VERSION ""

NS_ :

BS_:

BU_: CLOCK HUD H_U DATC CCP KMA_TMU CUBIS TMU IPM RSE_R RRC CGW RSE_L AMP EDT SWRC IBOX CLU FHCU ASD MON AVM KBD

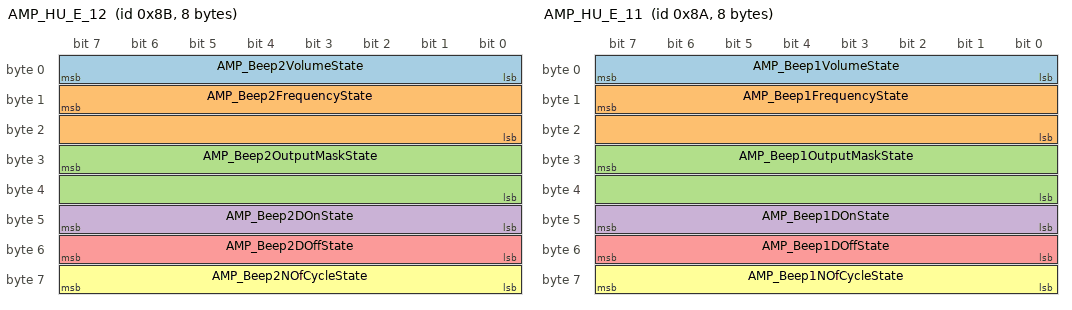
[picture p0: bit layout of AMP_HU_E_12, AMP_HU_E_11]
BO_ 139 AMP_HU_E_12: 8 AMP
 SG_ AMP_Beep2VolumeState : 7|8@0+ (1,0) [0|0] ""  H_U
 SG_ AMP_Beep2FrequencyState : 15|16@0+ (1,0) [0|0] ""  H_U
 SG_ AMP_Beep2OutputMaskState : 31|16@0+ (1,0) [0|0] ""  H_U
 SG_ AMP_Beep2DOnState : 47|8@0+ (1,0) [0|0] ""  H_U
 SG_ AMP_Beep2DOffState : 55|8@0+ (1,0) [0|0] ""  H_U
 SG_ AMP_Beep2NOfCycleState : 63|8@0+ (1,0) [0|0] ""  H_U

BO_ 138 AMP_HU_E_11: 8 AMP
 SG_ AMP_Beep1VolumeState : 7|8@0+ (1,0) [0|0] ""  H_U
 SG_ AMP_Beep1FrequencyState : 15|16@0+ (1,0) [0|0] ""  H_U
 SG_ AMP_Beep1OutputMaskState : 31|16@0+ (1,0) [0|0] ""  H_U
 SG_ AMP_Beep1DOnState : 47|8@0+ (1,0) [0|0] ""  H_U
 SG_ AMP_Beep1DOffState : 55|8@0+ (1,0) [0|0] ""  H_U
 SG_ AMP_Beep1NOfCycleState : 63|8@0+ (1,0) [0|0] ""  H_U

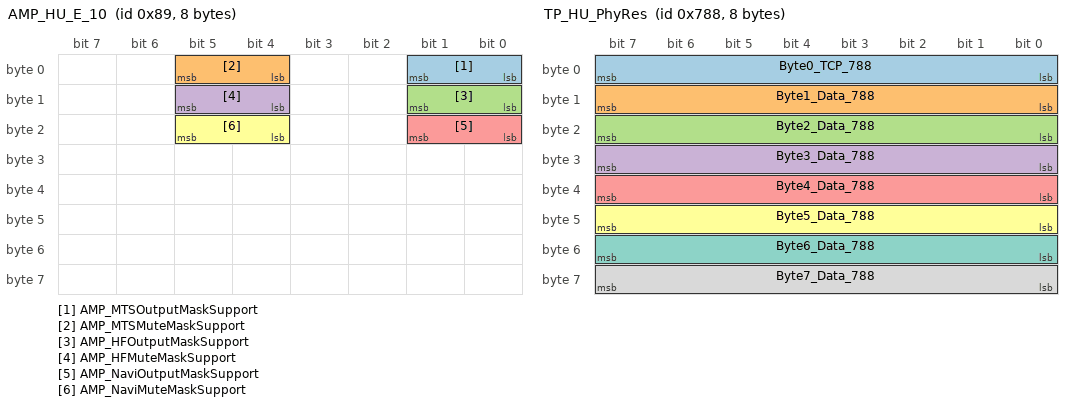
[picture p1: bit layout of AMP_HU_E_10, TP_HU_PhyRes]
BO_ 137 AMP_HU_E_10: 8 AMP
 SG_ AMP_MTSOutputMaskSupport : 1|2@0+ (1,0) [0|0] ""  H_U
 SG_ AMP_MTSMuteMaskSupport : 5|2@0+ (1,0) [0|0] ""  H_U
 SG_ AMP_HFOutputMaskSupport : 9|2@0+ (1,0) [0|0] ""  H_U
 SG_ AMP_HFMuteMaskSupport : 13|2@0+ (1,0) [0|0] ""  H_U
 SG_ AMP_NaviOutputMaskSupport : 17|2@0+ (1,0) [0|0] ""  H_U
 SG_ AMP_NaviMuteMaskSupport : 21|2@0+ (1,0) [0|0] ""  H_U

BO_ 1928 TP_HU_PhyRes: 8 H_U
 SG_ Byte0_TCP_788 : 7|8@0+ (1,0) [0|0] ""  EDT
 SG_ Byte1_Data_788 : 15|8@0+ (1,0) [0|0] ""  EDT
 SG_ Byte2_Data_788 : 23|8@0+ (1,0) [0|0] ""  EDT
 SG_ Byte3_Data_788 : 31|8@0+ (1,0) [0|0] ""  EDT
 SG_ Byte4_Data_788 : 39|8@0+ (1,0) [0|0] ""  EDT
 SG_ Byte5_Data_788 : 47|8@0+ (1,0) [0|0] ""  EDT
 SG_ Byte6_Data_788 : 55|8@0+ (1,0) [0|0] ""  EDT
 SG_ Byte7_Data_788 : 63|8@0+ (1,0) [0|0] ""  EDT

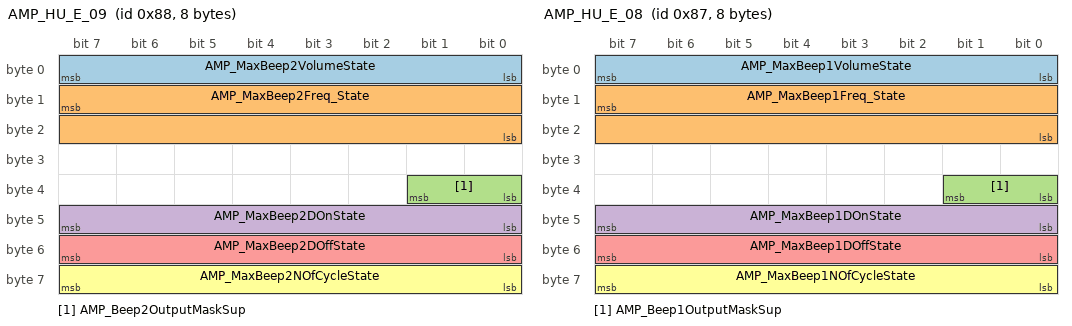
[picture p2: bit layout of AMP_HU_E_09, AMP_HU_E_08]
BO_ 136 AMP_HU_E_09: 8 AMP
 SG_ AMP_MaxBeep2VolumeState : 7|8@0+ (1,0) [0|0] ""  H_U
 SG_ AMP_MaxBeep2Freq_State : 15|16@0+ (1,0) [0|0] ""  H_U
 SG_ AMP_Beep2OutputMaskSup : 33|2@0+ (1,0) [0|0] ""  H_U
 SG_ AMP_MaxBeep2DOnState : 47|8@0+ (1,0) [0|0] ""  H_U
 SG_ AMP_MaxBeep2DOffState : 55|8@0+ (1,0) [0|0] ""  H_U
 SG_ AMP_MaxBeep2NOfCycleState : 63|8@0+ (1,0) [0|0] ""  H_U

BO_ 135 AMP_HU_E_08: 8 AMP
 SG_ AMP_MaxBeep1VolumeState : 7|8@0+ (1,0) [0|0] ""  H_U
 SG_ AMP_MaxBeep1Freq_State : 15|16@0+ (1,0) [0|0] ""  H_U
 SG_ AMP_Beep1OutputMaskSup : 33|2@0+ (1,0) [0|0] ""  H_U
 SG_ AMP_MaxBeep1DOnState : 47|8@0+ (1,0) [0|0] ""  H_U
 SG_ AMP_MaxBeep1DOffState : 55|8@0+ (1,0) [0|0] ""  H_U
 SG_ AMP_MaxBeep1NOfCycleState : 63|8@0+ (1,0) [0|0] ""  H_U

BO_ 134 AMP_HU_E_07: 8 AMP
 SG_ ASD_SetValue : 2|3@0+ (1,0) [0|0] ""  H_U,IBOX
 SG_ ASD_Version : 15|8@0+ (1,0) [0|0] ""  H_U,IBOX

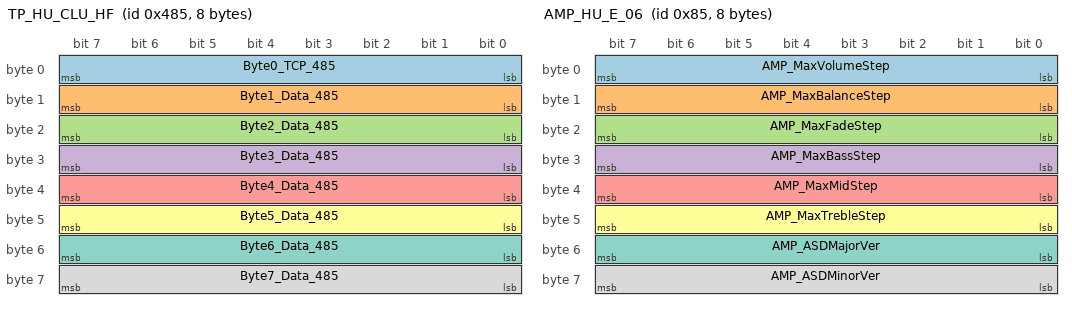
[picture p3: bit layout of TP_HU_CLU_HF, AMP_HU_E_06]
BO_ 1157 TP_HU_CLU_HF: 8 H_U
 SG_ Byte0_TCP_485 : 7|8@0+ (1,0) [0|0] ""  CLU
 SG_ Byte1_Data_485 : 15|8@0+ (1,0) [0|0] ""  CLU
 SG_ Byte2_Data_485 : 23|8@0+ (1,0) [0|0] ""  CLU
 SG_ Byte3_Data_485 : 31|8@0+ (1,0) [0|0] ""  CLU
 SG_ Byte4_Data_485 : 39|8@0+ (1,0) [0|0] ""  CLU
 SG_ Byte5_Data_485 : 47|8@0+ (1,0) [0|0] ""  CLU
 SG_ Byte6_Data_485 : 55|8@0+ (1,0) [0|0] ""  CLU
 SG_ Byte7_Data_485 : 63|8@0+ (1,0) [0|0] ""  CLU

BO_ 133 AMP_HU_E_06: 8 AMP
 SG_ AMP_MaxVolumeStep : 7|8@0+ (1,0) [0|0] ""  H_U
 SG_ AMP_MaxBalanceStep : 15|8@0+ (1,0) [0|0] ""  H_U
 SG_ AMP_MaxFadeStep : 23|8@0+ (1,0) [0|0] ""  H_U
 SG_ AMP_MaxBassStep : 31|8@0+ (1,0) [0|0] ""  H_U
 SG_ AMP_MaxMidStep : 39|8@0+ (1,0) [0|0] ""  H_U
 SG_ AMP_MaxTrebleStep : 47|8@0+ (1,0) [0|0] ""  H_U
 SG_ AMP_ASDMajorVer : 55|8@0+ (1,0) [0|0] ""  H_U
 SG_ AMP_ASDMinorVer : 63|8@0+ (1,0) [0|0] ""  H_U

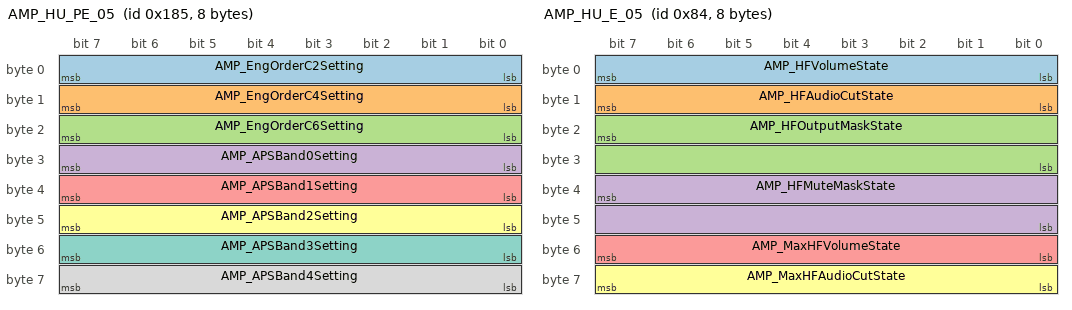
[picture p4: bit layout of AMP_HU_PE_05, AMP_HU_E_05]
BO_ 389 AMP_HU_PE_05: 8 AMP
 SG_ AMP_EngOrderC2Setting : 7|8@0+ (1,0) [0|0] ""  H_U
 SG_ AMP_EngOrderC4Setting : 15|8@0+ (1,0) [0|0] ""  H_U
 SG_ AMP_EngOrderC6Setting : 23|8@0+ (1,0) [0|0] ""  H_U
 SG_ AMP_APSBand0Setting : 31|8@0+ (1,0) [0|0] ""  H_U
 SG_ AMP_APSBand1Setting : 39|8@0+ (1,0) [0|0] ""  H_U
 SG_ AMP_APSBand2Setting : 47|8@0+ (1,0) [0|0] ""  H_U
 SG_ AMP_APSBand3Setting : 55|8@0+ (1,0) [0|0] ""  H_U
 SG_ AMP_APSBand4Setting : 63|8@0+ (1,0) [0|0] ""  H_U

BO_ 132 AMP_HU_E_05: 8 AMP
 SG_ AMP_HFVolumeState : 7|8@0+ (1,0) [0|0] ""  H_U
 SG_ AMP_HFAudioCutState : 15|8@0+ (1,0) [0|0] ""  H_U
 SG_ AMP_HFOutputMaskState : 23|16@0+ (1,0) [0|0] ""  H_U
 SG_ AMP_HFMuteMaskState : 39|16@0+ (1,0) [0|0] ""  H_U
 SG_ AMP_MaxHFVolumeState : 55|8@0+ (1,0) [0|0] ""  H_U
 SG_ AMP_MaxHFAudioCutState : 63|8@0+ (1,0) [0|0] ""  H_U

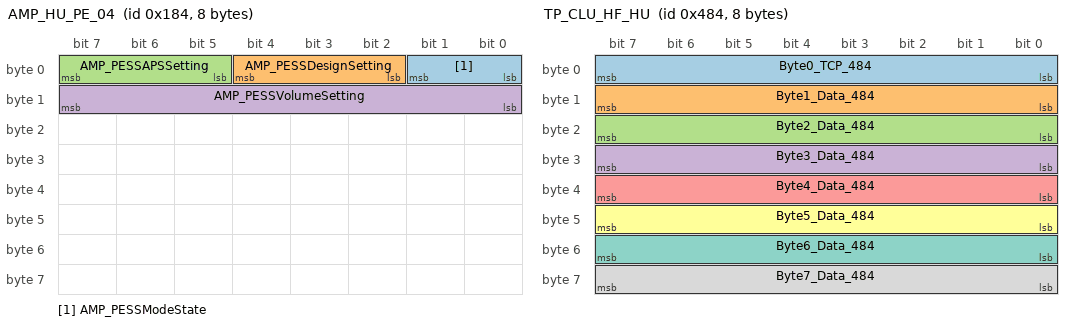
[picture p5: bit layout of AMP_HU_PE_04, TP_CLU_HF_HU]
BO_ 388 AMP_HU_PE_04: 8 AMP
 SG_ AMP_PESSModeState : 1|2@0+ (1,0) [0|0] ""  H_U
 SG_ AMP_PESSDesignSetting : 4|3@0+ (1,0) [0|0] ""  H_U
 SG_ AMP_PESSAPSSetting : 7|3@0+ (1,0) [0|0] ""  H_U
 SG_ AMP_PESSVolumeSetting : 15|8@0+ (1,0) [0|0] ""  H_U

BO_ 1156 TP_CLU_HF_HU: 8 CLU
 SG_ Byte0_TCP_484 : 7|8@0+ (1,0) [0|0] ""  H_U
 SG_ Byte1_Data_484 : 15|8@0+ (1,0) [0|0] ""  H_U
 SG_ Byte2_Data_484 : 23|8@0+ (1,0) [0|0] ""  H_U
 SG_ Byte3_Data_484 : 31|8@0+ (1,0) [0|0] ""  H_U
 SG_ Byte4_Data_484 : 39|8@0+ (1,0) [0|0] ""  H_U
 SG_ Byte5_Data_484 : 47|8@0+ (1,0) [0|0] ""  H_U
 SG_ Byte6_Data_484 : 55|8@0+ (1,0) [0|0] ""  H_U
 SG_ Byte7_Data_484 : 63|8@0+ (1,0) [0|0] ""  H_U

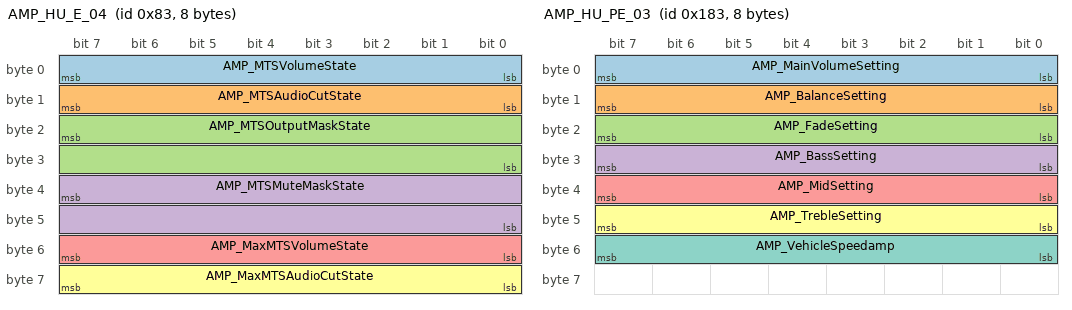
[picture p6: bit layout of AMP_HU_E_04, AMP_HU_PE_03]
BO_ 131 AMP_HU_E_04: 8 AMP
 SG_ AMP_MTSVolumeState : 7|8@0+ (1,0) [0|0] ""  H_U
 SG_ AMP_MTSAudioCutState : 15|8@0+ (1,0) [0|0] ""  H_U
 SG_ AMP_MTSOutputMaskState : 23|16@0+ (1,0) [0|0] ""  H_U
 SG_ AMP_MTSMuteMaskState : 39|16@0+ (1,0) [0|0] ""  H_U
 SG_ AMP_MaxMTSVolumeState : 55|8@0+ (1,0) [0|0] ""  H_U
 SG_ AMP_MaxMTSAudioCutState : 63|8@0+ (1,0) [0|0] ""  H_U

BO_ 387 AMP_HU_PE_03: 8 AMP
 SG_ AMP_MainVolumeSetting : 7|8@0+ (1,0) [0|0] ""  H_U
 SG_ AMP_BalanceSetting : 15|8@0+ (1,0) [0|0] ""  H_U
 SG_ AMP_FadeSetting : 23|8@0+ (1,0) [0|0] ""  H_U
 SG_ AMP_BassSetting : 31|8@0+ (1,0) [0|0] ""  H_U
 SG_ AMP_MidSetting : 39|8@0+ (1,0) [0|0] ""  H_U
 SG_ AMP_TrebleSetting : 47|8@0+ (1,0) [0|0] ""  H_U
 SG_ AMP_VehicleSpeedamp : 55|8@0+ (1,0) [0|0] ""  H_U

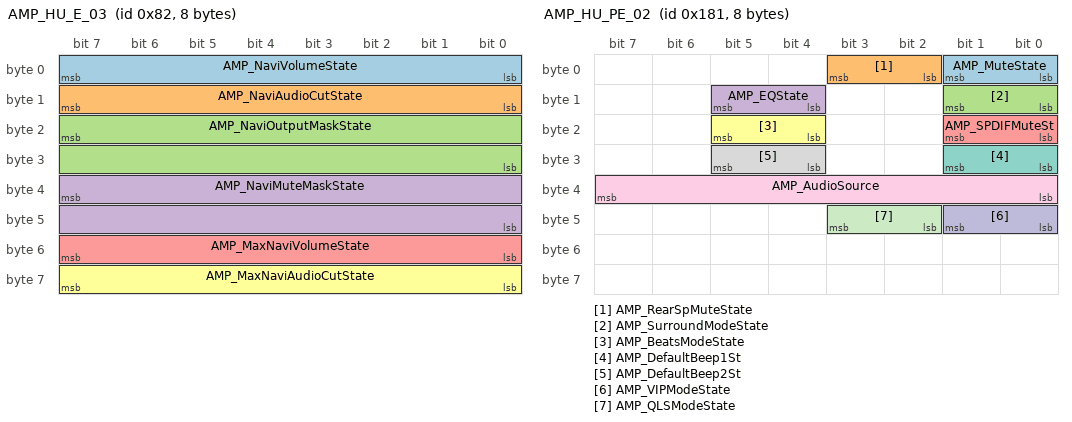
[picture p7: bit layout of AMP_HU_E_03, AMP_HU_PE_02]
BO_ 130 AMP_HU_E_03: 8 AMP
 SG_ AMP_NaviVolumeState : 7|8@0+ (1,0) [0|0] ""  H_U
 SG_ AMP_NaviAudioCutState : 15|8@0+ (1,0) [0|0] ""  H_U
 SG_ AMP_NaviOutputMaskState : 23|16@0+ (1,0) [0|0] ""  H_U
 SG_ AMP_NaviMuteMaskState : 39|16@0+ (1,0) [0|0] ""  H_U
 SG_ AMP_MaxNaviVolumeState : 55|8@0+ (1,0) [0|0] ""  H_U
 SG_ AMP_MaxNaviAudioCutState : 63|8@0+ (1,0) [0|0] ""  H_U

BO_ 129 AMP_HU_E_02: 8 AMP
 SG_ AMP_DriveState : 1|2@0+ (1,0) [0|0] ""  H_U
 SG_ AMP_ConvertibleTopState : 5|2@0+ (1,0) [0|0] ""  H_U

BO_ 385 AMP_HU_PE_02: 8 AMP
 SG_ AMP_MuteState : 1|2@0+ (1,0) [0|0] ""  H_U
 SG_ AMP_RearSpMuteState : 3|2@0+ (1,0) [0|0] ""  H_U
 SG_ AMP_SurroundModeState : 9|2@0+ (1,0) [0|0] ""  H_U
 SG_ AMP_EQState : 13|2@0+ (1,0) [0|0] ""  H_U
 SG_ AMP_SPDIFMuteSt : 17|2@0+ (1,0) [0|0] ""  H_U
 SG_ AMP_BeatsModeState : 21|2@0+ (1,0) [0|0] ""  H_U
 SG_ AMP_DefaultBeep1St : 25|2@0+ (1,0) [0|0] ""  H_U
 SG_ AMP_DefaultBeep2St : 29|2@0+ (1,0) [0|0] ""  H_U
 SG_ AMP_AudioSource : 39|8@0+ (1,0) [0|0] ""  H_U
 SG_ AMP_VIPModeState : 41|2@0+ (1,0) [0|0] ""  H_U
 SG_ AMP_QLSModeState : 43|2@0+ (1,0) [0|0] ""  H_U

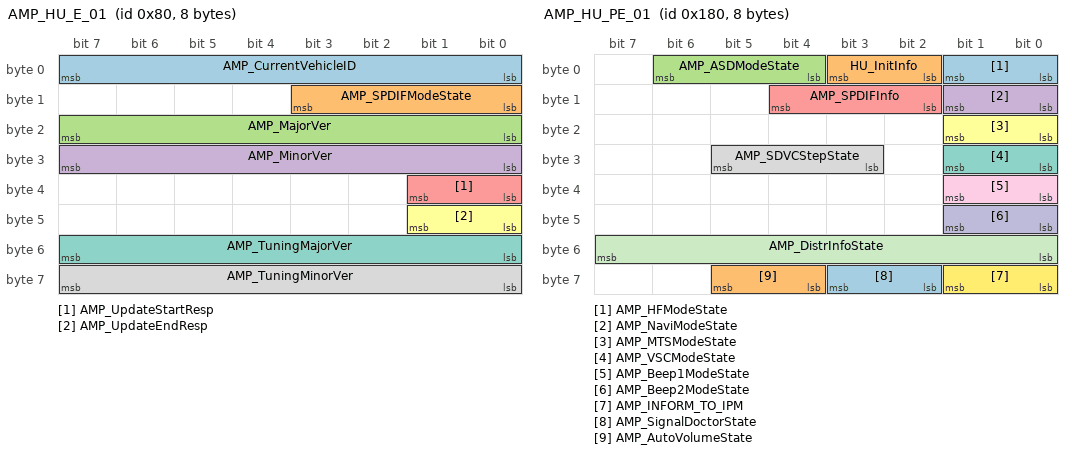
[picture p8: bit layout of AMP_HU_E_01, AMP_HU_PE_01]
BO_ 128 AMP_HU_E_01: 8 AMP
 SG_ AMP_CurrentVehicleID : 7|8@0+ (1,0) [0|0] ""  H_U
 SG_ AMP_SPDIFModeState : 11|4@0+ (1,0) [0|0] ""  H_U
 SG_ AMP_MajorVer : 23|8@0+ (1,0) [0|0] ""  H_U,MON
 SG_ AMP_MinorVer : 31|8@0+ (1,0) [0|0] ""  H_U,MON
 SG_ AMP_UpdateStartResp : 33|2@0+ (1,0) [0|0] ""  H_U
 SG_ AMP_UpdateEndResp : 41|2@0+ (1,0) [0|0] ""  H_U
 SG_ AMP_TuningMajorVer : 55|8@0+ (1,0) [0|0] ""  H_U
 SG_ AMP_TuningMinorVer : 63|8@0+ (1,0) [0|0] ""  H_U

BO_ 384 AMP_HU_PE_01: 8 AMP
 SG_ AMP_HFModeState : 1|2@0+ (1,0) [0|0] ""  CLU,H_U
 SG_ HU_InitInfo : 3|2@0+ (1,0) [0|0] ""  CLU,H_U
 SG_ AMP_ASDModeState : 6|3@0+ (1,0) [0|0] ""  CLU,H_U
 SG_ AMP_NaviModeState : 9|2@0+ (1,0) [0|0] ""  CLU,H_U
 SG_ AMP_SPDIFInfo : 12|3@0+ (1,0) [0|0] ""  CLU,H_U
 SG_ AMP_MTSModeState : 17|2@0+ (1,0) [0|0] ""  CLU,H_U
 SG_ AMP_VSCModeState : 25|2@0+ (1,0) [0|0] ""  CLU,H_U
 SG_ AMP_SDVCStepState : 29|3@0+ (1,0) [0|0] ""  CLU,H_U
 SG_ AMP_Beep1ModeState : 33|2@0+ (1,0) [0|0] ""  CLU,H_U
 SG_ AMP_Beep2ModeState : 41|2@0+ (1,0) [0|0] ""  CLU,H_U
 SG_ AMP_DistrInfoState : 55|8@0+ (1,0) [0|0] ""  CLU,H_U
 SG_ AMP_INFORM_TO_IPM : 57|2@0+ (1,0) [0|0] ""  CGW,CLU,DATC,H_U,IPM
 SG_ AMP_SignalDoctorState : 59|2@0+ (1,0) [0|0] ""  H_U
 SG_ AMP_AutoVolumeState : 61|2@0+ (1,0) [0|0] ""  H_U

BO_ 1408 AMP_HU_P_01: 8 AMP
 SG_ AMP_SupportMute : 1|2@0+ (1,0) [0|0] ""  H_U
 SG_ AMP_SupportHFMode : 3|2@0+ (1,0) [0|0] ""  H_U
 SG_ AMP_SupportCfgBeep1 : 5|2@0+ (1,0) [0|0] ""  H_U
 SG_ AMP_SupportCfgBeep2 : 7|2@0+ (1,0) [0|0] ""  H_U
 SG_ AMP_SupportSpeedAdjust : 9|2@0+ (1,0) [0|0] ""  H_U
 SG_ AMP_SupportSurroundMode : 11|2@0+ (1,0) [0|0] ""  H_U
 SG_ AMP_SupportNaviMode : 13|2@0+ (1,0) [0|0] ""  H_U
 SG_ AMP_SupportMTSMode : 15|2@0+ (1,0) [0|0] ""  H_U
 SG_ AMP_SupportTopState : 17|2@0+ (1,0) [0|0] ""  H_U
 SG_ AMP_SupportBothLHDandRHD : 19|2@0+ (1,0) [0|0] ""  H_U
 SG_ AMP_SupportEQState : 21|2@0+ (1,0) [0|0] ""  H_U
 SG_ AMP_SupportVehicleID : 23|2@0+ (1,0) [0|0] ""  H_U
 SG_ AMP_SupportAudioSource : 25|2@0+ (1,0) [0|0] ""  H_U
 SG_ AMP_SupportSPDIFModeState : 27|2@0+ (1,0) [0|0] ""  H_U
 SG_ AMP_SupportRearSpMute : 29|2@0+ (1,0) [0|0] ""  H_U
 SG_ AMP_SupportVEQMode : 31|2@0+ (1,0) [0|0] ""  H_U
 SG_ AMP_MakerID : 39|8@0+ (1,0) [0|0] ""  H_U
 SG_ AMP_SupportASDMode : 41|2@0+ (1,0) [0|0] ""  H_U
 SG_ AMP_SupportBeatsMode : 43|2@0+ (1,0) [0|0] ""  H_U
 SG_ AMP_SupportVIPMode : 45|2@0+ (1,0) [0|0] ""  H_U
 SG_ AMP_SupportQLS : 47|2@0+ (1,0) [0|0] ""  H_U
 SG_ AMP_SupportSignalDoctor : 49|2@0+ (1,0) [0|0] ""  H_U
 SG_ AMP_SupportAutoVolume : 51|2@0+ (1,0) [0|0] ""  H_U
 SG_ AMP_SupportPESSMode : 53|2@0+ (1,0) [0|0] ""  H_U

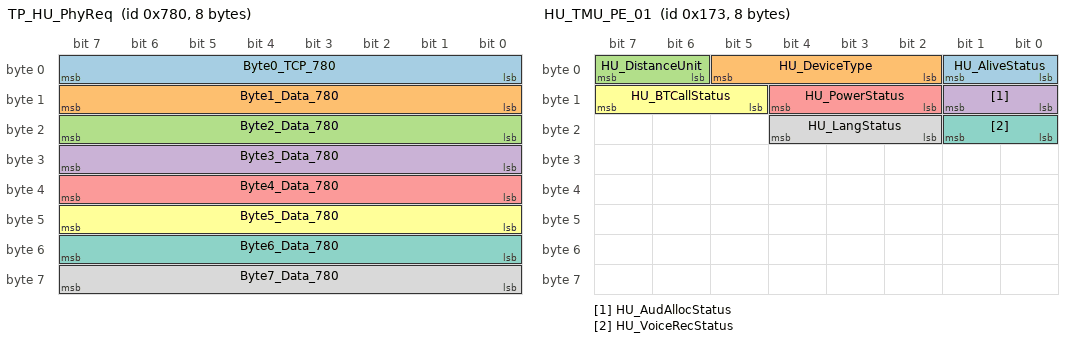
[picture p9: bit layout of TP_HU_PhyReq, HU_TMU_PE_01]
BO_ 1920 TP_HU_PhyReq: 8 EDT
 SG_ Byte0_TCP_780 : 7|8@0+ (1,0) [0|0] ""  H_U
 SG_ Byte1_Data_780 : 15|8@0+ (1,0) [0|0] ""  H_U
 SG_ Byte2_Data_780 : 23|8@0+ (1,0) [0|0] ""  H_U
 SG_ Byte3_Data_780 : 31|8@0+ (1,0) [0|0] ""  H_U
 SG_ Byte4_Data_780 : 39|8@0+ (1,0) [0|0] ""  H_U
 SG_ Byte5_Data_780 : 47|8@0+ (1,0) [0|0] ""  H_U
 SG_ Byte6_Data_780 : 55|8@0+ (1,0) [0|0] ""  H_U
 SG_ Byte7_Data_780 : 63|8@0+ (1,0) [0|0] ""  H_U

BO_ 371 HU_TMU_PE_01: 8 H_U
 SG_ HU_AliveStatus : 1|2@0+ (1,0) [0|0] ""  CLU,CGW,TMU
 SG_ HU_DeviceType : 5|4@0+ (1,0) [0|0] ""  TMU
 SG_ HU_DistanceUnit : 7|2@0+ (1,0) [0|0] ""  TMU
 SG_ HU_AudAllocStatus : 9|2@0+ (1,0) [0|0] ""  TMU
 SG_ HU_PowerStatus : 12|3@0+ (1,0) [0|0] ""  TMU
 SG_ HU_BTCallStatus : 15|3@0+ (1,0) [0|0] ""  TMU
 SG_ HU_VoiceRecStatus : 17|2@0+ (1,0) [0|0] ""  TMU
 SG_ HU_LangStatus : 20|3@0+ (1,0) [0|0] ""  TMU

BO_ 369 HU_Car_PE_01: 8 H_U
 SG_ HU_VehiclePwr : 3|4@0+ (1,0) [0|0] ""  AMP,ASD,AVM,CCP,CLOCK,CLU,CUBIS,DATC,FHCU,IPM,KBD,KMA_TMU,MON,RRC,RSE_L,RSE_R,TMU

BO_ 1392 HU_TMU_P_01: 8 H_U
 SG_ HU_GPS_Signal : 7|64@0+ (1,0) [0|0] ""  TMU

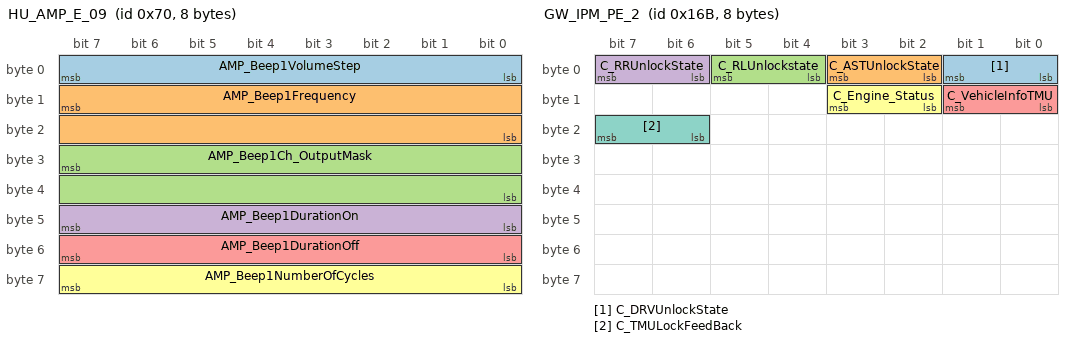
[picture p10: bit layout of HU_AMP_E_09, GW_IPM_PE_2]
BO_ 112 HU_AMP_E_09: 8 H_U
 SG_ AMP_Beep1VolumeStep : 7|8@0+ (1,0) [0|0] ""  AMP
 SG_ AMP_Beep1Frequency : 15|16@0+ (1,0) [0|0] ""  AMP
 SG_ AMP_Beep1Ch_OutputMask : 31|16@0+ (1,0) [0|0] ""  AMP
 SG_ AMP_Beep1DurationOn : 47|8@0+ (1,0) [0|0] ""  AMP
 SG_ AMP_Beep1DurationOff : 55|8@0+ (1,0) [0|0] ""  AMP
 SG_ AMP_Beep1NumberOfCycles : 63|8@0+ (1,0) [0|0] ""  AMP

BO_ 1390 GW_CLU_P: 8 CLU
 SG_ C_VehicleSpeed : 7|8@0+ (1,0) [0|254] ""  H_U,IBOX
 SG_ C_Odometer : 15|24@0+ (1,0) [0|999999] ""  H_U,IBOX

BO_ 363 GW_IPM_PE_2: 8 CLU
 SG_ C_DRVUnlockState : 1|2@0+ (1,0) [0|0] ""  CUBIS,TMU
 SG_ C_ASTUnlockState : 3|2@0+ (1,0) [0|0] ""  CUBIS,TMU
 SG_ C_RLUnlockstate : 5|2@0+ (1,0) [0|0] ""  CUBIS,TMU
 SG_ C_RRUnlockState : 7|2@0+ (1,0) [0|0] ""  CUBIS,TMU
 SG_ C_VehicleInfoTMU : 9|2@0+ (1,0) [0|0] ""  CUBIS,TMU
 SG_ C_Engine_Status : 11|2@0+ (1,0) [0|0] ""  CUBIS,TMU
 SG_ C_TMULockFeedBack : 23|2@0+ (1,0) [0|0] ""  CUBIS,TMU

BO_ 362 GW_IPM_PE_1: 8 CLU
 SG_ C_AV_Tail : 1|2@0+ (1,0) [0|0] ""  AMP,CCP,CLOCK,CLU,HUD,H_U,IBOX,RRC,RSE_L
 SG_ C_ParkingBrakeSW : 3|2@0+ (1,0) [0|0] ""  H_U
 SG_ C_RKECMD : 7|4@0+ (1,0) [0|0] ""  H_U
 SG_ C_BAState : 9|2@0+ (1,0) [0|0] ""  H_U,IBOX
 SG_ C_IGNSW : 14|3@0+ (1,0) [0|0] ""  AMP,AVM,CUBIS,EDT,H_U,MON,RRC,SWRC
 SG_ C_CountryCfg : 18|3@0+ (1,0) [0|0] ""  AVM,H_U
 SG_ C_AltL : 25|2@0+ (1,0) [0|0] ""  H_U
 SG_ C_TailLampActivity : 27|2@0+ (1,0) [0|0] ""  AMP,CCP,CLOCK,HUD,H_U,IBOX,RRC,RSE_L,SWRC
 SG_ RearSW_RSELockOnOff : 29|2@0+ (1,0) [0|0] ""  H_U,IBOX
 SG_ C_TMULockFeedBack : 31|2@0+ (1,0) [0|0] ""  CUBIS,TMU
 SG_ C_SMKTeleCrankingState : 33|2@0+ (1,0) [0|0] ""  H_U,IBOX
 SG_ C_SMKTeleCrankingFailRes : 35|2@0+ (1,0) [0|0] ""  H_U,IBOX
 SG_ C_RKECMD_GEN2 : 39|3@0+ (1,0) [0|0] ""  H_U,IBOX
 SG_ C_Acu_CshAct : 41|2@0+ (1,0) [0|0] ""  H_U,IBOX
 SG_ C_IntTailAct : 43|2@0+ (1,0) [0|0] ""  AMP,CCP,CLOCK,CLU,HUD,H_U,IBOX,RRC,RSE_L
 SG_ C_PassiveAccessUnlock : 47|3@0+ (1,0) [0|0] ""  H_U,IBOX
 SG_ Lca_IndLeft : 49|2@0+ (1,0) [0|0] ""  H_U
 SG_ FL_SndWarn : 51|2@0+ (1,0) [0|0] ""  AMP
 SG_ FR_SndWarn : 53|2@0+ (1,0) [0|0] ""  AMP
 SG_ Lca_IndRight : 55|2@0+ (1,0) [0|0] ""  H_U
 SG_ RCTA_IndLeft : 57|2@0+ (1,0) [0|0] ""  H_U
 SG_ RL_SndWarn : 59|2@0+ (1,0) [0|0] ""  AMP
 SG_ RR_SndWarn : 61|2@0+ (1,0) [0|0] ""  AMP
 SG_ RCTA_IndRight : 63|2@0+ (1,0) [0|0] ""  H_U

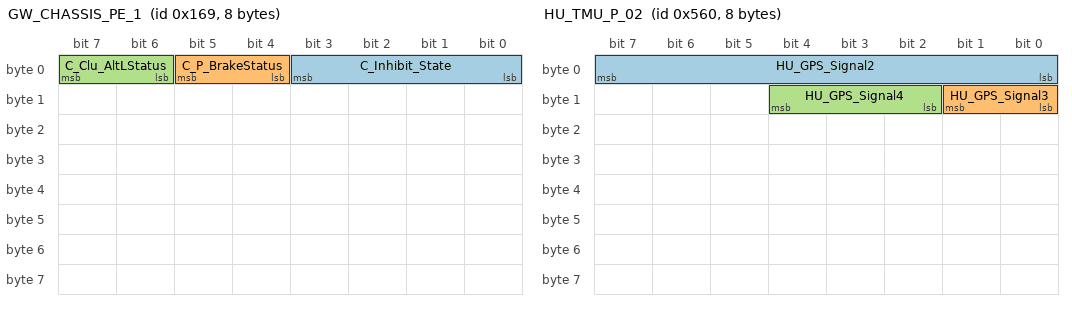
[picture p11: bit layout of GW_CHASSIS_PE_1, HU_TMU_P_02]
BO_ 361 GW_CHASSIS_PE_1: 8 CLU
 SG_ C_Inhibit_State : 3|4@0+ (1,0) [0|0] ""  AVM,H_U
 SG_ C_P_BrakeStatus : 5|2@0+ (1,0) [0|0] ""  AVM,H_U
 SG_ C_Clu_AltLStatus : 7|2@0+ (1,0) [0|0] ""  AVM,H_U

BO_ 359 GW_WARNING_PE_01: 8 CLU
 SG_ Spas_BEEP_Alarm : 3|4@0+ (1,0) [0|0] ""  AMP
 SG_ Spas_Audio_VolumeDown : 5|2@0+ (1,0) [0|0] ""  AMP
 SG_ Spas_Spkr_Flh_Alarm : 9|2@0+ (1,0) [0|0] ""  AMP,H_U
 SG_ Spas_Spkr_Fcnt_Alarm : 11|2@0+ (1,0) [0|0] ""  AMP,H_U
 SG_ Spas_Spkr_Frh_Alarm : 13|2@0+ (1,0) [0|0] ""  AMP,H_U
 SG_ Spas_Spkr_Rlh_Alarm : 17|2@0+ (1,0) [0|0] ""  AMP,H_U
 SG_ Spas_Spkr_Rcnt_Alarm : 19|2@0+ (1,0) [0|0] ""  AMP,H_U
 SG_ Spas_Spkr_Rrh_Alarm : 21|2@0+ (1,0) [0|0] ""  AMP,H_U
 SG_ Lkas_SysStatus : 27|4@0+ (1,0) [0|0] ""  AMP,H_U
 SG_ Lkas_LH_Warning : 29|2@0+ (1,0) [0|0] ""  AMP,H_U
 SG_ Lkas_RH_Warning : 31|2@0+ (1,0) [0|0] ""  AMP,H_U
 SG_ Spas_Spkr_Level : 35|3@0+ (1,0) [0|0] ""  AMP
 SG_ Lkas_Audio_VolumeDown : 37|2@0+ (1,0) [0|0] ""  AMP,H_U
 SG_ Audio_VolumeDown : 39|2@0+ (1,0) [0|0] ""  AMP,H_U
 SG_ Pas_BEEP_Alarm : 43|4@0+ (1,0) [0|0] ""  AMP
 SG_ Pas_Audio_VolumeDown : 45|2@0+ (1,0) [0|0] ""  AMP,H_U
 SG_ Pas_Spkr_Level : 32|3@0+ (1,0) [0|0] ""  AMP
 SG_ Pas_Spkr_Flh_Alarm : 49|2@0+ (1,0) [0|0] ""  AMP,H_U
 SG_ Pas_Spkr_Fcnt_Alarm : 51|2@0+ (1,0) [0|0] ""  AMP,H_U
 SG_ Pas_Spkr_Frh_Alarm : 53|2@0+ (1,0) [0|0] ""  AMP,H_U
 SG_ Pas_Spkr_Rlh_Alarm : 57|2@0+ (1,0) [0|0] ""  AMP,H_U
 SG_ Pas_Spkr_Rcnt_Alarm : 59|2@0+ (1,0) [0|0] ""  AMP,H_U
 SG_ Pas_Spkr_Rrh_Alarm : 61|2@0+ (1,0) [0|0] ""  AMP,H_U

BO_ 1376 HU_TMU_P_02: 8 H_U
 SG_ HU_GPS_Signal2 : 7|8@0+ (2,0) [0|0] "Degree"  TMU
 SG_ HU_GPS_Signal3 : 9|2@0+ (1,0) [0|0] ""  TMU
 SG_ HU_GPS_Signal4 : 12|3@0+ (1,0) [0|0] ""  TMU

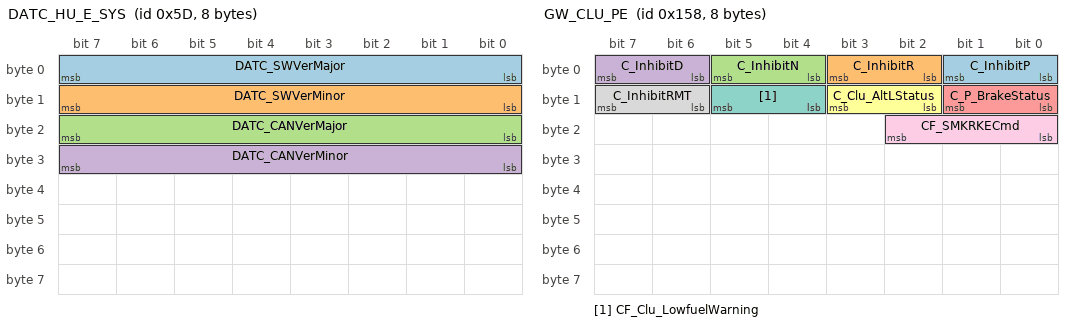
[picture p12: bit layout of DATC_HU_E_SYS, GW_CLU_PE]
BO_ 93 DATC_HU_E_SYS: 8 CLU
 SG_ DATC_SWVerMajor : 7|8@0+ (1,0) [0|254] ""  H_U
 SG_ DATC_SWVerMinor : 15|8@0+ (1,0) [0|254] ""  H_U
 SG_ DATC_CANVerMajor : 23|8@0+ (1,0) [0|254] ""  H_U
 SG_ DATC_CANVerMinor : 31|8@0+ (1,0) [0|254] ""  H_U

BO_ 344 GW_CLU_PE: 8 CLU
 SG_ C_InhibitP : 1|2@0+ (1,0) [0|0] ""  H_U,IBOX
 SG_ C_InhibitR : 3|2@0+ (1,0) [0|0] ""  H_U,IBOX
 SG_ C_InhibitN : 5|2@0+ (1,0) [0|0] ""  H_U,IBOX
 SG_ C_InhibitD : 7|2@0+ (1,0) [0|0] ""  H_U,IBOX
 SG_ C_P_BrakeStatus : 9|2@0+ (1,0) [0|0] ""  H_U,IBOX
 SG_ C_Clu_AltLStatus : 11|2@0+ (1,0) [0|0] ""  H_U,IBOX
 SG_ CF_Clu_LowfuelWarning : 13|2@0+ (1,0) [0|0] ""  H_U,IBOX
 SG_ C_InhibitRMT : 15|2@0+ (1,0) [0|0] ""  H_U
 SG_ CF_SMKRKECmd : 18|3@0+ (1,0) [0|0] ""  H_U

BO_ 87 HU_E_02: 8 H_U
 SG_ NaviValidity : 1|2@0+ (1,0) [0|0] ""  CGW,CLU

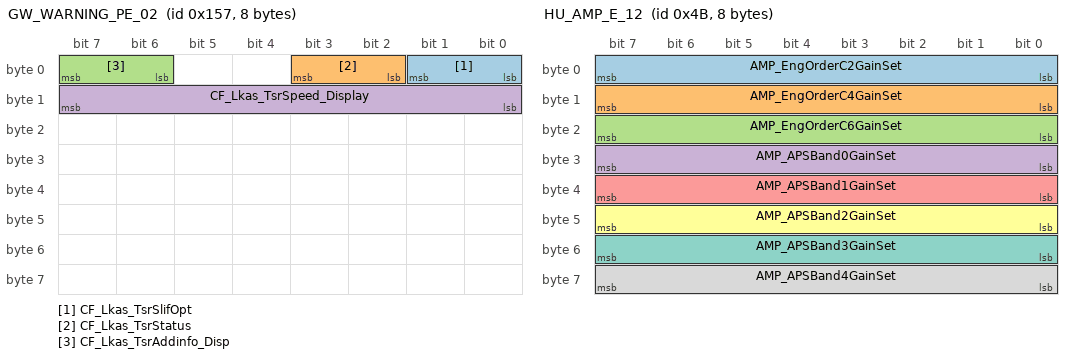
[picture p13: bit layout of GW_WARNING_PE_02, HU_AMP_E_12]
BO_ 343 GW_WARNING_PE_02: 8 CLU
 SG_ CF_Lkas_TsrSlifOpt : 1|2@0+ (1,0) [0|3] ""  H_U
 SG_ CF_Lkas_TsrStatus : 3|2@0+ (1,0) [0|3] ""  H_U
 SG_ CF_Lkas_TsrAddinfo_Disp : 7|2@0+ (1,0) [0|3] ""  H_U
 SG_ CF_Lkas_TsrSpeed_Display : 15|8@0+ (1,0) [0|255] ""  H_U

BO_ 75 HU_AMP_E_12: 8 H_U
 SG_ AMP_EngOrderC2GainSet : 7|8@0+ (1,0) [0|0] ""  AMP
 SG_ AMP_EngOrderC4GainSet : 15|8@0+ (1,0) [0|0] ""  AMP
 SG_ AMP_EngOrderC6GainSet : 23|8@0+ (1,0) [0|0] ""  AMP
 SG_ AMP_APSBand0GainSet : 31|8@0+ (1,0) [0|0] ""  AMP
 SG_ AMP_APSBand1GainSet : 39|8@0+ (1,0) [0|0] ""  AMP
 SG_ AMP_APSBand2GainSet : 47|8@0+ (1,0) [0|0] ""  AMP
 SG_ AMP_APSBand3GainSet : 55|8@0+ (1,0) [0|0] ""  AMP
 SG_ AMP_APSBand4GainSet : 63|8@0+ (1,0) [0|0] ""  AMP

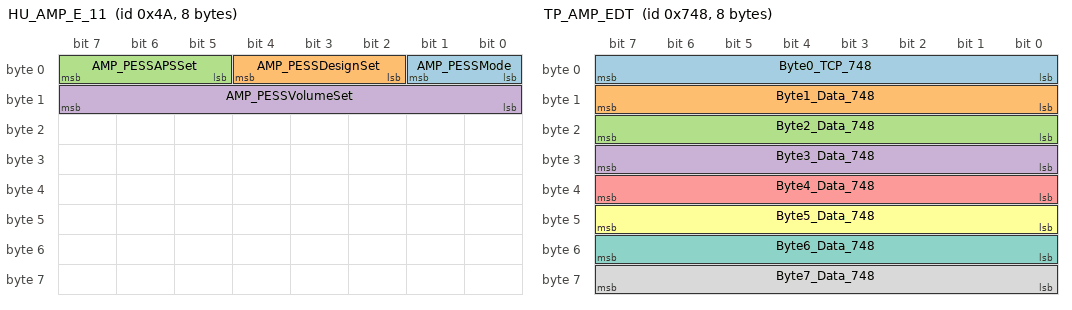
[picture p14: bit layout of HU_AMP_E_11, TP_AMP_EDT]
BO_ 74 HU_AMP_E_11: 8 H_U
 SG_ AMP_PESSMode : 1|2@0+ (1,0) [0|0] ""  AMP
 SG_ AMP_PESSDesignSet : 4|3@0+ (1,0) [0|0] ""  AMP
 SG_ AMP_PESSAPSSet : 7|3@0+ (1,0) [0|0] ""  AMP
 SG_ AMP_PESSVolumeSet : 15|8@0+ (1,0) [0|0] ""  AMP

BO_ 1864 TP_AMP_EDT: 8 AMP
 SG_ Byte0_TCP_748 : 7|8@0+ (1,0) [0|0] ""  EDT
 SG_ Byte1_Data_748 : 15|8@0+ (1,0) [0|0] ""  EDT
 SG_ Byte2_Data_748 : 23|8@0+ (1,0) [0|0] ""  EDT
 SG_ Byte3_Data_748 : 31|8@0+ (1,0) [0|0] ""  EDT
 SG_ Byte4_Data_748 : 39|8@0+ (1,0) [0|0] ""  EDT
 SG_ Byte5_Data_748 : 47|8@0+ (1,0) [0|0] ""  EDT
 SG_ Byte6_Data_748 : 55|8@0+ (1,0) [0|0] ""  EDT
 SG_ Byte7_Data_748 : 63|8@0+ (1,0) [0|0] ""  EDT

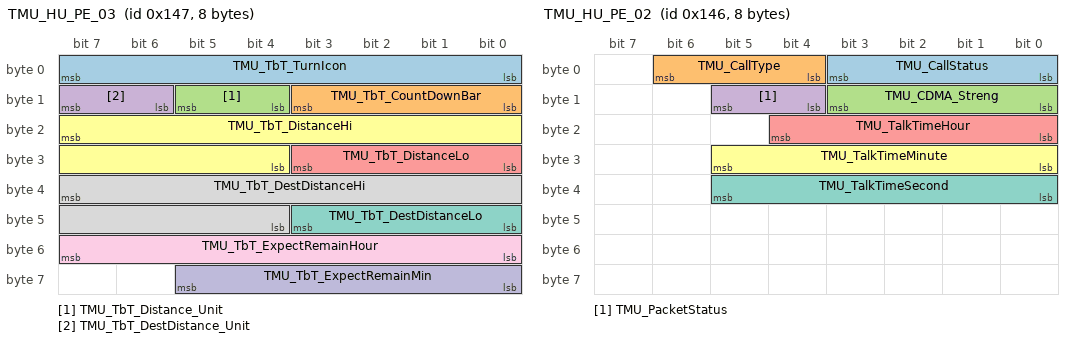
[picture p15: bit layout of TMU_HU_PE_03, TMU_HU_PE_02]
BO_ 327 TMU_HU_PE_03: 8 TMU
 SG_ TMU_TbT_TurnIcon : 7|8@0+ (1,0) [0|0] ""  H_U
 SG_ TMU_TbT_CountDownBar : 11|4@0+ (1,0) [0|0] ""  H_U
 SG_ TMU_TbT_Distance_Unit : 13|2@0+ (1,0) [0|0] ""  H_U
 SG_ TMU_TbT_DestDistance_Unit : 15|2@0+ (1,0) [0|0] ""  H_U
 SG_ TMU_TbT_DistanceLo : 27|4@0+ (1,0) [0|0] ""  H_U
 SG_ TMU_TbT_DistanceHi : 23|12@0+ (1,0) [0|0] ""  H_U
 SG_ TMU_TbT_DestDistanceLo : 43|4@0+ (1,0) [0|0] ""  H_U
 SG_ TMU_TbT_DestDistanceHi : 39|12@0+ (1,0) [0|0] ""  H_U
 SG_ TMU_TbT_ExpectRemainHour : 55|8@0+ (1,0) [0|0] ""  H_U
 SG_ TMU_TbT_ExpectRemainMin : 61|6@0+ (1,0) [0|0] ""  H_U

BO_ 326 TMU_HU_PE_02: 8 TMU
 SG_ TMU_CallStatus : 3|4@0+ (1,0) [0|0] ""  H_U
 SG_ TMU_CallType : 6|3@0+ (1,0) [0|0] ""  H_U
 SG_ TMU_CDMA_Streng : 11|4@0+ (1,0) [0|0] ""  H_U
 SG_ TMU_PacketStatus : 13|2@0+ (1,0) [0|0] ""  H_U
 SG_ TMU_TalkTimeHour : 20|5@0+ (1,0) [0|0] ""  H_U
 SG_ TMU_TalkTimeMinute : 29|6@0+ (1,0) [0|0] ""  H_U
 SG_ TMU_TalkTimeSecond : 37|6@0+ (1,0) [0|0] ""  H_U

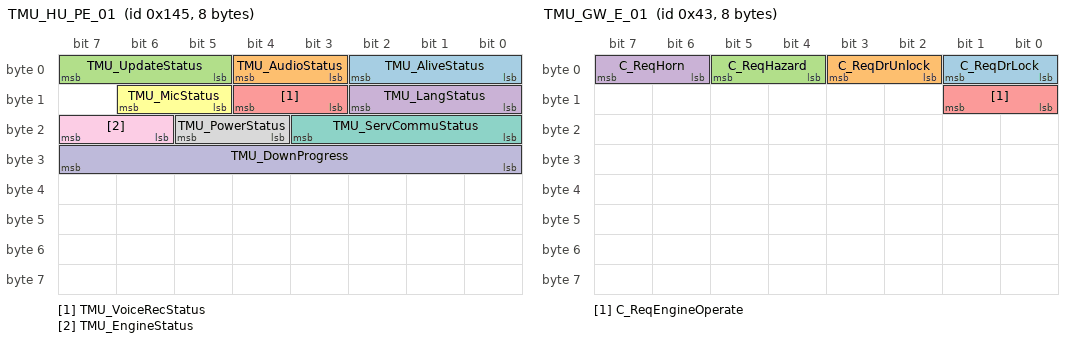
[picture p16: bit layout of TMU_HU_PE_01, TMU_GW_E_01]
BO_ 325 TMU_HU_PE_01: 8 TMU
 SG_ TMU_AliveStatus : 2|3@0+ (1,0) [0|0] ""  H_U
 SG_ TMU_AudioStatus : 4|2@0+ (1,0) [0|0] ""  H_U
 SG_ TMU_UpdateStatus : 7|3@0+ (1,0) [0|0] ""  H_U
 SG_ TMU_LangStatus : 10|3@0+ (1,0) [0|0] ""  H_U
 SG_ TMU_VoiceRecStatus : 12|2@0+ (1,0) [0|0] ""  H_U
 SG_ TMU_MicStatus : 14|2@0+ (1,0) [0|0] ""  H_U
 SG_ TMU_ServCommuStatus : 19|4@0+ (1,0) [0|0] ""  H_U
 SG_ TMU_PowerStatus : 21|2@0+ (1,0) [0|0] ""  H_U
 SG_ TMU_EngineStatus : 23|2@0+ (1,0) [0|0] ""  H_U
 SG_ TMU_DownProgress : 31|8@0+ (1,0) [0|0] ""  H_U

BO_ 69 TMU_HU_E_04: 8 TMU
 SG_ TMU_eCall : 1|2@0+ (1,0) [0|0] ""  H_U

BO_ 67 TMU_GW_E_01: 8 TMU
 SG_ C_ReqDrLock : 1|2@0+ (1,0) [0|0] ""  CGW,CLU,DATC,IPM
 SG_ C_ReqDrUnlock : 3|2@0+ (1,0) [0|0] ""  CGW,CLU,DATC,IPM
 SG_ C_ReqHazard : 5|2@0+ (1,0) [0|0] ""  CGW,CLU,DATC,IPM
 SG_ C_ReqHorn : 7|2@0+ (1,0) [0|0] ""  CGW,CLU,DATC,IPM
 SG_ C_ReqEngineOperate : 9|2@0+ (1,0) [0|0] ""  CGW,CLU,DATC,IPM

BO_ 66 TMU_HU_E_03: 8 TMU
 SG_ CDMA_SelfDiag : 1|2@0+ (1,0) [0|0] ""  H_U
 SG_ CDMA_Antena_SelfDiag : 3|2@0+ (1,0) [0|0] ""  H_U

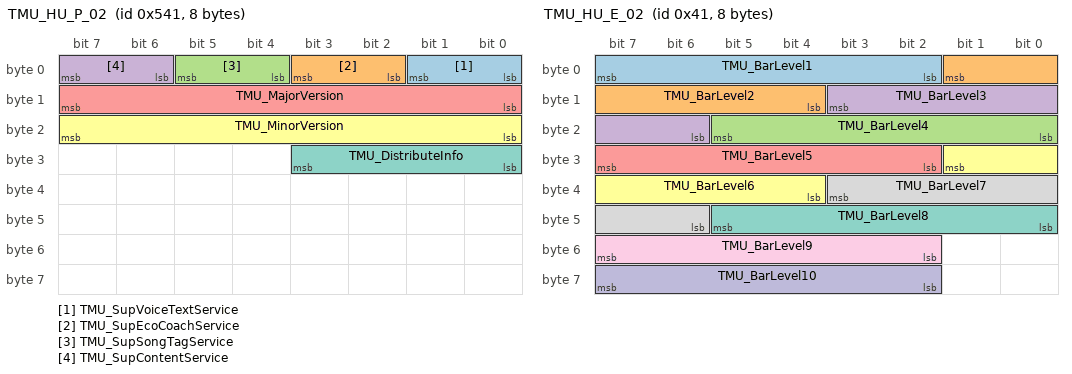
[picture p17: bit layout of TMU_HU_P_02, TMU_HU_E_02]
BO_ 1345 TMU_HU_P_02: 8 TMU
 SG_ TMU_SupVoiceTextService : 1|2@0+ (1,0) [0|0] ""  H_U
 SG_ TMU_SupEcoCoachService : 3|2@0+ (1,0) [0|0] ""  H_U
 SG_ TMU_SupSongTagService : 5|2@0+ (1,0) [0|0] ""  H_U
 SG_ TMU_SupContentService : 7|2@0+ (1,0) [0|0] ""  H_U
 SG_ TMU_MajorVersion : 15|8@0+ (1,0) [0|0] ""  H_U
 SG_ TMU_MinorVersion : 23|8@0+ (1,0) [0|0] ""  H_U
 SG_ TMU_DistributeInfo : 27|4@0+ (1,0) [0|0] ""  H_U

BO_ 65 TMU_HU_E_02: 8 TMU
 SG_ TMU_BarLevel1 : 7|6@0+ (1,0) [0|0] ""  H_U
 SG_ TMU_BarLevel2 : 1|6@0+ (1,0) [0|0] ""  H_U
 SG_ TMU_BarLevel4 : 21|6@0+ (1,0) [0|0] ""  H_U
 SG_ TMU_BarLevel3 : 11|6@0+ (1,0) [0|0] ""  H_U
 SG_ TMU_BarLevel5 : 31|6@0+ (1,0) [0|0] ""  H_U
 SG_ TMU_BarLevel6 : 25|6@0+ (1,0) [0|0] ""  H_U
 SG_ TMU_BarLevel8 : 45|6@0+ (1,0) [0|0] ""  H_U
 SG_ TMU_BarLevel7 : 35|6@0+ (1,0) [0|0] ""  H_U
 SG_ TMU_BarLevel9 : 55|6@0+ (1,0) [0|0] ""  H_U
 SG_ TMU_BarLevel10 : 63|6@0+ (1,0) [0|0] ""  H_U

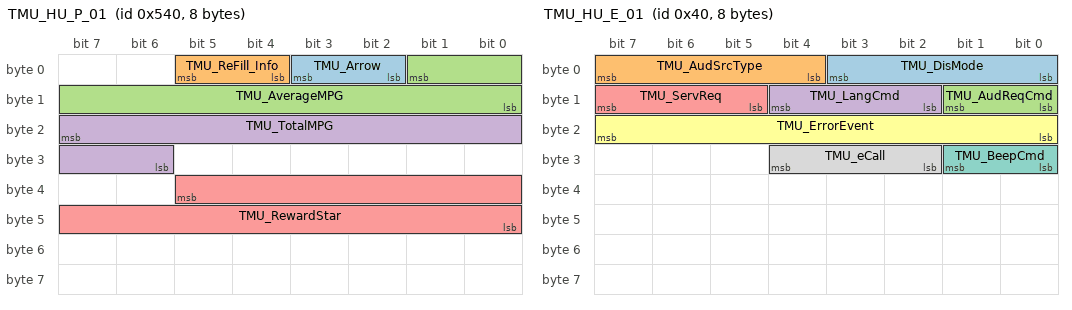
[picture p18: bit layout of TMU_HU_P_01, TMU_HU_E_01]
BO_ 1344 TMU_HU_P_01: 8 TMU
 SG_ TMU_Arrow : 3|2@0+ (1,0) [0|0] ""  H_U
 SG_ TMU_ReFill_Info : 5|2@0+ (1,0) [0|0] ""  H_U
 SG_ TMU_AverageMPG : 1|10@0+ (1,0) [0|0] ""  H_U
 SG_ TMU_TotalMPG : 23|10@0+ (1,0) [0|0] ""  H_U
 SG_ TMU_RewardStar : 37|14@0+ (1,0) [0|0] ""  H_U

BO_ 64 TMU_HU_E_01: 8 TMU
 SG_ TMU_DisMode : 3|4@0+ (1,0) [0|0] ""  H_U
 SG_ TMU_AudSrcType : 7|4@0+ (1,0) [0|0] ""  CLU,DATC,H_U
 SG_ TMU_AudReqCmd : 9|2@0+ (1,0) [0|0] ""  H_U
 SG_ TMU_LangCmd : 12|3@0+ (1,0) [0|0] ""  H_U
 SG_ TMU_ServReq : 15|3@0+ (1,0) [0|0] ""  H_U
 SG_ TMU_ErrorEvent : 23|8@0+ (1,0) [0|0] ""  H_U
 SG_ TMU_BeepCmd : 25|2@0+ (1,0) [0|0] ""  H_U
 SG_ TMU_eCall : 28|3@0+ (1,0) [0|0] ""  H_U

CM_ BO_ 139 "[EW] On Event and On Write";
CM_ SG_ 139 AMP_Beep2VolumeState "current beep2 volume setting";
CM_ SG_ 139 AMP_Beep2FrequencyState "current beep2 frequency setting";
CM_ SG_ 139 AMP_Beep2OutputMaskState "current status of bit mask used to identify which channels output Beep2";
CM_ SG_ 139 AMP_Beep2DOnState "current beep2 on-time setting

(the middle pause in double beeP= 0.5 x AMP_Beep2DurationOn)";
CM_ SG_ 139 AMP_Beep2DOffState "current beep2 off-time setting";
CM_ SG_ 139 AMP_Beep2NOfCycleState "current Beep2 repetition number";
CM_ BO_ 138 "[EW] On Event and On Write";
CM_ SG_ 138 AMP_Beep1VolumeState "current beep1 volume setting";
CM_ SG_ 138 AMP_Beep1FrequencyState "current beep1 frequency setting";
CM_ SG_ 138 AMP_Beep1OutputMaskState "current status of bit mask used to identify which channels output Beep1";
CM_ SG_ 138 AMP_Beep1DOnState "current Beep1 on-time setting";
CM_ SG_ 138 AMP_Beep1DOffState "current Beep1 off-time setting";
CM_ SG_ 138 AMP_Beep1NOfCycleState "current Beep1 repetition number";
CM_ BO_ 137 "[EC] On Event and On Change";
CM_ SG_ 137 AMP_MTSOutputMaskSupport "does amPsupport output masking during MTS mode?";
CM_ SG_ 137 AMP_MTSMuteMaskSupport "does amPsupport mute masking during MTS mode?";
CM_ SG_ 137 AMP_HFOutputMaskSupport "does amPsupport output masking during HF mode?";
CM_ SG_ 137 AMP_HFMuteMaskSupport "does amPsupport mute masking during HF mode?";
CM_ SG_ 137 AMP_NaviOutputMaskSupport "does amPsupport output masking during NAVI mode?";
CM_ SG_ 137 AMP_NaviMuteMaskSupport "does amPsupport mute masking during NAVI mode?";
CM_ BO_ 1928 "[TP] TP Message";
CM_ SG_ 1928 Byte0_TCP_788 "Diagnosis Response to external tester";
CM_ SG_ 1928 Byte1_Data_788 "Diagnosis Response to external tester";
CM_ SG_ 1928 Byte2_Data_788 "Diagnosis Response to external tester";
CM_ SG_ 1928 Byte3_Data_788 "Diagnosis Response to external tester";
CM_ SG_ 1928 Byte4_Data_788 "Diagnosis Response to external tester";
CM_ SG_ 1928 Byte5_Data_788 "Diagnosis Response to external tester";
CM_ SG_ 1928 Byte6_Data_788 "Diagnosis Response to external tester";
CM_ SG_ 1928 Byte7_Data_788 "Diagnosis Response to external tester";
CM_ BO_ 136 "[EC] On Event and On Change";
CM_ SG_ 136 AMP_MaxBeep2VolumeState "current beeP2 max volume limit";
CM_ SG_ 136 AMP_MaxBeep2Freq_State "current Beep2 max frequency limit";
CM_ SG_ 136 AMP_Beep2OutputMaskSup "Does amPsupport output masking for beep2";
CM_ SG_ 136 AMP_MaxBeep2DOnState "Current Beep2 max on-time limit";
CM_ SG_ 136 AMP_MaxBeep2DOffState "Current Beep2 max off-time limit";
CM_ SG_ 136 AMP_MaxBeep2NOfCycleState "current max beep2 repetition limit";
CM_ BO_ 135 "[EC] On Event and On Change";
CM_ SG_ 135 AMP_MaxBeep1VolumeState "current beeP1 max volume limit";
CM_ SG_ 135 AMP_MaxBeep1Freq_State "current Beep1 max frequency limit";
CM_ SG_ 135 AMP_Beep1OutputMaskSup "Does amPsupport output masking for beep1?";
CM_ SG_ 135 AMP_MaxBeep1DOnState "Current Beep1 max on-time limit";
CM_ SG_ 135 AMP_MaxBeep1DOffState "Current Beep1 max off-time limit";
CM_ SG_ 135 AMP_MaxBeep1NOfCycleState "current max beep1 repetition limit";
CM_ BO_ 134 "[EC] On Event and On Change";
CM_ SG_ 134 ASD_SetValue "ASD Set Function Signal";
CM_ SG_ 134 ASD_Version "ASD Module Version";
CM_ BO_ 1157 "[TP] TP Message";
CM_ BO_ 133 "[EC] On Event and On Change";
CM_ SG_ 133 AMP_MaxVolumeStep "current max Main audio volume limit";
CM_ SG_ 133 AMP_MaxBalanceStep "current max Left/right audio balance limit";
CM_ SG_ 133 AMP_MaxFadeStep "current max Front/rear audio fader limit";
CM_ SG_ 133 AMP_MaxBassStep "current max Bass tone control limit";
CM_ SG_ 133 AMP_MaxMidStep "current max Midrange tone control limit";
CM_ SG_ 133 AMP_MaxTrebleStep "current max Treble tone control limit";
CM_ SG_ 133 AMP_ASDMajorVer "Version information related with ASD Module";
CM_ SG_ 133 AMP_ASDMinorVer "Version information related with ASD Module";
CM_ BO_ 389 "[PE] Periodic and On Event";
CM_ BO_ 132 "[EC] On Event and On Change";
CM_ SG_ 132 AMP_HFVolumeState "current HF call volume setting status";
CM_ SG_ 132 AMP_HFAudioCutState "current main audio volume cut setting status during HF call";
CM_ SG_ 132 AMP_HFOutputMaskState "current status of bit mask used to identify which speakers will output HF call audio";
CM_ SG_ 132 AMP_HFMuteMaskState "current status of bit mask used to identify which speakers will mute main audio during HF call";
CM_ SG_ 132 AMP_MaxHFVolumeState "HFM Maximum Volume limit";
CM_ SG_ 132 AMP_MaxHFAudioCutState "maximum main audio volume limit during HF mode";
CM_ BO_ 388 "[PE] Periodic and On Event";
CM_ BO_ 1156 "[TP] TP Message";
CM_ BO_ 131 "[EC] On Event and On Change";
CM_ SG_ 131 AMP_MTSVolumeState "current MTS call volume setting status";
CM_ SG_ 131 AMP_MTSAudioCutState "current main audio volume cut setting status during MTS call";
CM_ SG_ 131 AMP_MTSOutputMaskState "current status of bit mask used to identify which speakers will output MTS call audio";
CM_ SG_ 131 AMP_MTSMuteMaskState "current status of bit mask used to identify which speakers will mute main audio during MTS call";
CM_ SG_ 131 AMP_MaxMTSVolumeState "MTS Maximum Volume limit";
CM_ SG_ 131 AMP_MaxMTSAudioCutState "maximum main audio volume limit during MTS mode";
CM_ BO_ 387 "[PE] Periodic and On Event";
CM_ SG_ 387 AMP_MainVolumeSetting "Current main audio volume setting status";
CM_ SG_ 387 AMP_BalanceSetting "Current Left/Right Audio balance setting status";
CM_ SG_ 387 AMP_FadeSetting "Current Front/Rear audio Fader Setting status";
CM_ SG_ 387 AMP_BassSetting "Current bass tone control setting status";
CM_ SG_ 387 AMP_MidSetting "current midrange tone control setting status";
CM_ SG_ 387 AMP_TrebleSetting "Current treble tone control setting status";
CM_ SG_ 387 AMP_VehicleSpeedamp "current vehicle speed status";
CM_ BO_ 130 "[EC] On Event and On Change";
CM_ SG_ 130 AMP_NaviVolumeState "current Navi prompt volume setting";
CM_ SG_ 130 AMP_NaviAudioCutState "current main audio volume setting during NAVI prompt";
CM_ SG_ 130 AMP_NaviOutputMaskState "current status of bit mask used to identify which speakers will output NAVI prompt";
CM_ SG_ 130 AMP_NaviMuteMaskState "current status of bit mask used to identify which speakers will mute main audio during NAVI prompt";
CM_ SG_ 130 AMP_MaxNaviVolumeState "Navi Prompt Maximum Volume limit";
CM_ SG_ 130 AMP_MaxNaviAudioCutState "maximum main audio volume limit during NAVI mode";
CM_ BO_ 129 "[EC] On Event and On Change";
CM_ SG_ 129 AMP_DriveState "Current status of Driver side";
CM_ SG_ 129 AMP_ConvertibleTopState "current convertible toPinformation status";
CM_ BO_ 385 "[PE] Periodic and On Event";
CM_ SG_ 385 AMP_MuteState "Current mute state";
CM_ SG_ 385 AMP_RearSpMuteState "Current rear speaker mute state during RSE
use";
CM_ SG_ 385 AMP_SurroundModeState "Current surround on/off status";
CM_ SG_ 385 AMP_EQState "Current EQ loading and active state check";
CM_ SG_ 385 AMP_SPDIFMuteSt "Current SPDIF Mute state";
CM_ SG_ 385 AMP_BeatsModeState "Current Beats On/Off state";
CM_ SG_ 385 AMP_DefaultBeep1St "current Beep1 state";
CM_ SG_ 385 AMP_DefaultBeep2St "current Beep1 state";
CM_ SG_ 385 AMP_AudioSource "Current audio mode status";
CM_ SG_ 385 AMP_VIPModeState "Current VIP mode ON/OFF state";
CM_ SG_ 385 AMP_QLSModeState "Current QLS mode ON/OFF state";
CM_ BO_ 128 "[EC] On Event and On Change";
CM_ SG_ 128 AMP_CurrentVehicleID "current Vehicle ID setting status";
CM_ SG_ 128 AMP_SPDIFModeState "current SPDIF audio source information status";
CM_ SG_ 128 AMP_MajorVer "Version information releated with Hardware";
CM_ SG_ 128 AMP_MinorVer "Version information releated with Software";
CM_ SG_ 128 AMP_UpdateStartResp "Responds to AMPUpdate？Command Start";
CM_ SG_ 128 AMP_UpdateEndResp "Responds to AMPUpdate？Command End";
CM_ SG_ 128 AMP_TuningMajorVer "Version information related with tuning data";
CM_ SG_ 128 AMP_TuningMinorVer "Version information related with tuning data";
CM_ BO_ 384 "[PE] Periodic and On Event";
CM_ SG_ 384 AMP_HFModeState "current HF call status";
CM_ SG_ 384 HU_InitInfo "External AMP Initiation related signal

0x1 : Request AMP Initialization
0x2 : AMP Initialization complted";
CM_ SG_ 384 AMP_ASDModeState "current ASD Mode status";
CM_ SG_ 384 AMP_NaviModeState "current Navi prompt status";
CM_ SG_ 384 AMP_SPDIFInfo "External AMP Initiation related signal

0x1: SPDIF PLL Unlock
0x2: PLL Lock & Null Data Received 
0x3:PLL Lock &  PCM Data Received 
0x4: PLL Lock & Compressed Data Received";
CM_ SG_ 384 AMP_MTSModeState "current MTS call status";
CM_ SG_ 384 AMP_VSCModeState "current Vehicle Speed Compensation mode
state";
CM_ SG_ 384 AMP_SDVCStepState "current SDVC stePstate";
CM_ SG_ 384 AMP_Beep1ModeState "current Beep1 mode status";
CM_ SG_ 384 AMP_Beep2ModeState "current Beep2 mode status";
CM_ SG_ 384 AMP_DistrInfoState "current status of:
Region :Europe/North America/..
 Driver Position : RHD/LHD
  Positionning Information";
CM_ SG_ 384 AMP_INFORM_TO_IPM "AMPIS CONNECTED MM-CAN";
CM_ SG_ 384 AMP_SignalDoctorState "Current SignalDoctor ON/OFF state";
CM_ SG_ 384 AMP_AutoVolumeState "Current AutoVolume ON/OFF state";
CM_ BO_ 1408 "[P] Periodic";
CM_ SG_ 1408 AMP_SupportMute "does amPsupport mute control?";
CM_ SG_ 1408 AMP_SupportHFMode "does amPsupport HF mode?";
CM_ SG_ 1408 AMP_SupportCfgBeep1 "does amPsupport configurable Beep1?";
CM_ SG_ 1408 AMP_SupportCfgBeep2 "does amPsupport configurable Beep1?";
CM_ SG_ 1408 AMP_SupportSpeedAdjust "does amPsupport Vehicle Speed Compensation function?";
CM_ SG_ 1408 AMP_SupportSurroundMode "does amPsupport Surround mode?";
CM_ SG_ 1408 AMP_SupportNaviMode "does amPsupport NAVI mode?";
CM_ SG_ 1408 AMP_SupportMTSMode "does amPsupport MTS mode?";
CM_ SG_ 1408 AMP_SupportTopState "does amPsupport ConvertibleToPState?";
CM_ SG_ 1408 AMP_SupportBothLHDandRHD "does amPsupport both LHD and RHD?";
CM_ SG_ 1408 AMP_SupportEQState "does amPsupport EQ loading status?";
CM_ SG_ 1408 AMP_SupportVehicleID "does amPsupport Vehicle ID recognition?";
CM_ SG_ 1408 AMP_SupportAudioSource "does amPsupport Audio Source?";
CM_ SG_ 1408 AMP_SupportSPDIFModeState "does amPsupport SPDIF mode state?";
CM_ SG_ 1408 AMP_SupportRearSpMute "does amPsupport Rear Speaker Mute during RSE use?";
CM_ SG_ 1408 AMP_SupportVEQMode "does amPsupport VEQ Mode?";
CM_ SG_ 1408 AMP_MakerID "For model afrer 2014, use 0x01~0x03 only.";
CM_ SG_ 1408 AMP_SupportASDMode "does amPsupport ASD?";
CM_ SG_ 1408 AMP_SupportBeatsMode "Does amp Support Beats mode?";
CM_ SG_ 1408 AMP_SupportVIPMode "Does amp support VIP mode?";
CM_ SG_ 1408 AMP_SupportQLS "Does amp support Quantum Logic Surround mode?";
CM_ SG_ 1408 AMP_SupportSignalDoctor "Does amp support SignalDoctor?";
CM_ SG_ 1408 AMP_SupportAutoVolume "Does amp support AutoVolume?";
CM_ SG_ 1408 AMP_SupportPESSMode "Does amp
Support
PESS mode?";
CM_ BO_ 1920 "[TP] TP Message";
CM_ SG_ 1920 Byte0_TCP_780 "TP";
CM_ SG_ 1920 Byte1_Data_780 "TP";
CM_ SG_ 1920 Byte2_Data_780 "TP";
CM_ SG_ 1920 Byte3_Data_780 "TP";
CM_ SG_ 1920 Byte4_Data_780 "TP";
CM_ SG_ 1920 Byte5_Data_780 "TP";
CM_ SG_ 1920 Byte6_Data_780 "TP";
CM_ SG_ 1920 Byte7_Data_780 "TP";
CM_ BO_ 371 "[PE] Periodic and On Event";
CM_ SG_ 371 HU_AliveStatus "descripe the status of Head Unit
0x00 : Headunit is booting so, Headunit cant display any state
0x01 : Headunit is normal state, Headunit could display according to MM CAN  command.
0x02 : Headunit is doing their internal process, so Headunit cant communicate with other node.";
CM_ SG_ 371 HU_DeviceType "decribe the Head Unit type";
CM_ SG_ 371 HU_DistanceUnit "Head Unit Distance Unit";
CM_ SG_ 371 HU_AudAllocStatus "Response of TMU_AudReqCmd signal";
CM_ SG_ 371 HU_BTCallStatus "describe the Bluetooth Phone Status connectted with Headunit";
CM_ SG_ 371 HU_VoiceRecStatus "audio TMU only notifies HU VR is using";
CM_ SG_ 371 HU_LangStatus "shows language setting of HU";
CM_ BO_ 369 "[PE] Periodic and On Event";
CM_ SG_ 369 HU_VehiclePwr "descripe the status of IGN Switch";
CM_ BO_ 1392 "[P] Periodic";
CM_ SG_ 1392 HU_GPS_Signal "GPS Signal


GPS Signal(MSB) nsFlag(1) + Latitude_sub(5) + Latitude(20) + ewFlag(1) + Longitute_sub(5) + Longitute(20) + Heading(12) (LSB)";
CM_ BO_ 112 "[EC] On Event and On Change";
CM_ SG_ 112 AMP_Beep1VolumeStep "Beep1 Frequency Setting";
CM_ SG_ 112 AMP_Beep1Frequency "Beep1 frequency setting";
CM_ SG_ 112 AMP_Beep1Ch_OutputMask "Bit mask used to identify which speakers will output beep1";
CM_ SG_ 112 AMP_Beep1DurationOn "Beep1 on-time setting";
CM_ SG_ 112 AMP_Beep1DurationOff "Beep 1 Off time setting";
CM_ SG_ 112 AMP_Beep1NumberOfCycles "Beep1 repitition number setting";
CM_ BO_ 1390 "[P] Periodic";
CM_ SG_ 1390 C_VehicleSpeed "Vehicle speed";
CM_ SG_ 1390 C_Odometer "Odometer";
CM_ BO_ 363 "[PE] Periodic and On Event";
CM_ SG_ 363 C_DRVUnlockState "Driver Door Lock Status";
CM_ SG_ 363 C_ASTUnlockState "Assist Door Lock Status";
CM_ SG_ 363 C_RLUnlockstate "Rear Left Door Lock Status";
CM_ SG_ 363 C_RRUnlockState "Rear Right Door Lock Status";
CM_ SG_ 363 C_VehicleInfoTMU "Buglar Alarm / Panic Signal";
CM_ SG_ 363 C_Engine_Status "Engine Start/Stop Status";
CM_ SG_ 363 C_TMULockFeedBack "All Door lock & Close State";
CM_ BO_ 362 "[PE] Periodic and On Event";
CM_ SG_ 362 C_AV_Tail "Autolight Info";
CM_ SG_ 362 C_RKECMD "리모콘 door Unlock 신호
(리모콘 MAX 4개까지 등록 가능 각각 구분함)";
CM_ SG_ 362 C_BAState "Alarm Detection";
CM_ SG_ 362 C_IGNSW "Vehicle engine status data";
CM_ SG_ 362 C_CountryCfg "Country Configuration";
CM_ SG_ 362 C_AltL "C_AltL 시그널 수신 필요";
CM_ SG_ 362 C_TailLampActivity "Tail Lamp Info";
CM_ SG_ 362 RearSW_RSELockOnOff "Rear Console SW Lock Request";
CM_ SG_ 362 C_TMULockFeedBack "All Door Lock & Close State";
CM_ SG_ 362 C_SMKTeleCrankingState "Telematics cranking operation mode
On : Telematics cranking on mode
Off : Telematics cranking off mode";
CM_ SG_ 362 C_SMKTeleCrankingFailRes "Telematics cranking fail reason";
CM_ SG_ 362 C_RKECMD_GEN2 "RKE Input Info (2세대 C-CAN)";
CM_ SG_ 362 C_Acu_CshAct "Vehicle crash Info";
CM_ SG_ 362 C_IntTailAct "Interior Tail Lamp Activity";
CM_ SG_ 362 C_PassiveAccessUnlock "This signal is used for control about Passive access unlock function.";
CM_ SG_ 362 Lca_IndLeft "BSD Warning Display : LH";
CM_ SG_ 362 FL_SndWarn "LCA Warning Sound : LH";
CM_ SG_ 362 FR_SndWarn "LCA Warning Sound : RH";
CM_ SG_ 362 Lca_IndRight "BSD Warning Display : RH";
CM_ SG_ 362 RCTA_IndLeft "RCTA Warning Display : LH";
CM_ SG_ 362 RL_SndWarn "RCTA Warning Sound : LH";
CM_ SG_ 362 RR_SndWarn "RCTA Warning Sound : RH";
CM_ SG_ 362 RCTA_IndRight "RCTA Warning Display : RH";
CM_ BO_ 361 "[PE] Periodic and On Event";
CM_ SG_ 361 C_Inhibit_State "Selected gear";
CM_ BO_ 359 "[PE] Periodic and On Event";
CM_ SG_ 359 Spas_BEEP_Alarm "Warning Sound based on SPAS alarms";
CM_ SG_ 359 Spas_Audio_VolumeDown "Current AMP Main Audio Volume attenuation during Multi-tone Beep output";
CM_ SG_ 359 Spas_Spkr_Flh_Alarm "SPAS Warning Sound : Frt Left";
CM_ SG_ 359 Spas_Spkr_Fcnt_Alarm "SPAS Warning Sound : Frt Left + Frt Right";
CM_ SG_ 359 Spas_Spkr_Frh_Alarm "SPAS Warning Sound : Frt Right";
CM_ SG_ 359 Spas_Spkr_Rlh_Alarm "SPAS Warning Sound : Rear Left";
CM_ SG_ 359 Spas_Spkr_Rcnt_Alarm "SPAS Warning Sound : Rear Left + Rear Right";
CM_ SG_ 359 Spas_Spkr_Rrh_Alarm "SPAS Warning Sound : Rear Right";
CM_ SG_ 359 Lkas_SysStatus "Warning Sound based on Driver status, hand off or not";
CM_ SG_ 359 Lkas_LH_Warning "LKAS Warning Sound : LH";
CM_ SG_ 359 Lkas_RH_Warning "LKAS Warning Sound : RH";
CM_ SG_ 359 Spas_Spkr_Level "SPAS Warning Sound Level Adjustment";
CM_ SG_ 359 Lkas_Audio_VolumeDown "Current AMP Main Audio Volume attenuation during Multi-tone Beep output";
CM_ SG_ 359 Audio_VolumeDown "Audio Volume down for making clear warning sound (SPAS, LKAS, BSD, PAS, SCC)";
CM_ SG_ 359 Pas_BEEP_Alarm "Warning Sound based on PAS alarms";
CM_ SG_ 359 Pas_Audio_VolumeDown "Current AMP Main Audio Volume attenuation during Multi-tone Beep output";
CM_ SG_ 359 Pas_Spkr_Level "PAS Warning Sound Level Adjustment";
CM_ SG_ 359 Pas_Spkr_Flh_Alarm "PAS Warning Sound : Frt Left";
CM_ SG_ 359 Pas_Spkr_Fcnt_Alarm "PAS Warning Sound : Frt Left + Frt Right";
CM_ SG_ 359 Pas_Spkr_Frh_Alarm "PAS Warning Sound : Frt Right";
CM_ SG_ 359 Pas_Spkr_Rlh_Alarm "PAS Warning Sound : Rear Left";
CM_ SG_ 359 Pas_Spkr_Rcnt_Alarm "PAS Warning Sound : Rear Left + Rear Right";
CM_ SG_ 359 Pas_Spkr_Rrh_Alarm "PAS Warning Sound : Rear Right";
CM_ BO_ 1376 "[P] Periodic";
CM_ SG_ 1376 HU_GPS_Signal2 "Vehicle Directional information";
CM_ SG_ 1376 HU_GPS_Signal3 "GPS signal confidence information";
CM_ SG_ 1376 HU_GPS_Signal4 "GNSS Diagnostics information";
CM_ BO_ 93 "[EC] On Event and On Change";
CM_ SG_ 93 DATC_SWVerMajor "SW Major Version of DATC";
CM_ SG_ 93 DATC_SWVerMinor "SW Minor Version of DATC";
CM_ SG_ 93 DATC_CANVerMajor "CAN Major Version of DATC";
CM_ SG_ 93 DATC_CANVerMinor "CAN Minor Version of DATC";
CM_ BO_ 344 "[PE] Periodic and On Event";
CM_ SG_ 344 C_InhibitP "TGS Lever - P";
CM_ SG_ 344 C_InhibitR "TGS Lever - R";
CM_ SG_ 344 C_InhibitN "TGS Lever - N";
CM_ SG_ 344 C_InhibitD "TGS Lever - D";
CM_ SG_ 344 C_P_BrakeStatus "Parking Brake Status";
CM_ SG_ 344 C_Clu_AltLStatus "Alternator Status";
CM_ SG_ 344 CF_Clu_LowfuelWarning "Low fuel warning information";
CM_ SG_ 344 CF_SMKRKECmd "This signal is used for confirm the SMK RKE command.

This signal is valid from B+ (Battery attached) state. (Also valid over B+ : ACC, IGN1)
And it can be used to wake up C-CAN bus during IG-OFF Status.

-B-CAN Source: C_SMKRKECmd";
CM_ BO_ 87 "[EC] On Event and On Change";
CM_ SG_ 87 NaviValidity "SCC로 전달되는 TP 데이터의 유효성을 판단하는 기준이 되는 신호.
Normal인 경우 SCC는 TP 데이터를 처리.
Navi Error인 경우 SCC는 TP 데이터 미처리.
No Navi 인 경우 TP 데이터 미전송하므로 SCC는 신호 기다리지 말 것.";
CM_ BO_ 343 "[PE] Periodic and On Event";
CM_ SG_ 343 CF_Lkas_TsrSlifOpt "SLIF option information";
CM_ SG_ 343 CF_Lkas_TsrStatus "Validity of TSR information";
CM_ SG_ 343 CF_Lkas_TsrAddinfo_Disp "Passing Zone information setting";
CM_ SG_ 343 CF_Lkas_TsrSpeed_Display "TSR(ISA/SLIF) speed information for velocity display";
CM_ BO_ 75 "[EC] On Event and On Change";
CM_ BO_ 74 "[E] On Event";
CM_ BO_ 1864 "[TP] TP Message";
CM_ SG_ 1864 Byte0_TCP_748 "TP";
CM_ SG_ 1864 Byte1_Data_748 "TP";
CM_ SG_ 1864 Byte2_Data_748 "TP";
CM_ SG_ 1864 Byte3_Data_748 "TP";
CM_ SG_ 1864 Byte4_Data_748 "TP";
CM_ SG_ 1864 Byte5_Data_748 "TP";
CM_ SG_ 1864 Byte6_Data_748 "TP";
CM_ SG_ 1864 Byte7_Data_748 "TP";
CM_ BO_ 327 "[PE] Periodic and On Event";
CM_ SG_ 327 TMU_TbT_TurnIcon "Turn Icon";
CM_ SG_ 327 TMU_TbT_CountDownBar "Count Down Bar";
CM_ SG_ 327 TMU_TbT_DistanceLo "Distance Low Bit";
CM_ SG_ 327 TMU_TbT_DistanceHi "Distance Hi Bit";
CM_ SG_ 327 TMU_TbT_DestDistanceLo "Destination Distance Low Bit";
CM_ SG_ 327 TMU_TbT_DestDistanceHi "Destination Distance Hi Bit";
CM_ SG_ 327 TMU_TbT_ExpectRemainHour "Expect Remain Hour";
CM_ SG_ 327 TMU_TbT_ExpectRemainMin "Expect Remain Minute";
CM_ BO_ 326 "[PE] Periodic and On Event";
CM_ SG_ 326 TMU_CallStatus "This signal shall be set according to CDMA status";
CM_ SG_ 326 TMU_CallType "defines incoming call type.";
CM_ SG_ 326 TMU_CDMA_Streng "CDMA Strength";
CM_ SG_ 326 TMU_PacketStatus "Packet Status";
CM_ SG_ 326 TMU_TalkTimeHour "Talk Time Hour";
CM_ SG_ 326 TMU_TalkTimeMinute "Talk Time Minute";
CM_ SG_ 326 TMU_TalkTimeSecond "Talk Time Second";
CM_ BO_ 325 "[PE] Periodic and On Event";
CM_ SG_ 325 TMU_AliveStatus "According to TMU mode, this signal shall be set.";
CM_ SG_ 325 TMU_AudioStatus "Whenever TMU generates audio sound, this signal shall be set to 'Playing Audio'";
CM_ SG_ 325 TMU_UpdateStatus "This signal shall be set when device is updating";
CM_ SG_ 325 TMU_LangStatus "This signal shows language setting on TMU";
CM_ SG_ 325 TMU_VoiceRecStatus "This signal shall be set when VR is active or VRS prompt is playing.";
CM_ SG_ 325 TMU_MicStatus "Mic Status";
CM_ SG_ 325 TMU_ServCommuStatus "Server Communication Status";
CM_ SG_ 325 TMU_PowerStatus "TMU Power Status";
CM_ SG_ 325 TMU_EngineStatus "It shows what percentage of operation is progressed";
CM_ SG_ 325 TMU_DownProgress "Engine Running Status";
CM_ BO_ 69 "[EC] On Event and On Change";
CM_ SG_ 69 TMU_eCall "This signal shall be set to 0x01 when eCall mode. If H/U receive 0x01, H/U mute all sound and eCall unit can get MIC operational control. 'eCall in progress' pop-up shall be displayed";
CM_ BO_ 67 "[EC] On Event and On Change";
CM_ SG_ 67 C_ReqDrLock "Request Door Lock";
CM_ SG_ 67 C_ReqDrUnlock "Request Door Unlock";
CM_ SG_ 67 C_ReqHazard "Request Hazard On";
CM_ SG_ 67 C_ReqHorn "Request Horn On";
CM_ SG_ 67 C_ReqEngineOperate "Request Engine Start/Stop";
CM_ BO_ 66 "[EC] On Event and On Change";
CM_ SG_ 66 CDMA_SelfDiag "This signal shall be set only if engineer requests CDMA status";
CM_ SG_ 66 CDMA_Antena_SelfDiag "This signal shall be set only if engineer requests CDMA status";
CM_ BO_ 1345 "[P] Periodic";
CM_ SG_ 1345 TMU_SupVoiceTextService "Availability of Voice Text Serviec";
CM_ SG_ 1345 TMU_SupEcoCoachService "Availability of Eco Coach Service";
CM_ SG_ 1345 TMU_SupSongTagService "Availability of SongTag Service";
CM_ SG_ 1345 TMU_SupContentService "Availability of Weather Service";
CM_ SG_ 1345 TMU_MajorVersion "H/W version";
CM_ SG_ 1345 TMU_MinorVersion "S/W version";
CM_ SG_ 1345 TMU_DistributeInfo "TMU Module Distribution Information";
CM_ BO_ 65 "[EC] On Event and On Change";
CM_ SG_ 65 TMU_BarLevel1 "1st level of historgram
This value is converted form average MPG per 2.5 minutes";
CM_ SG_ 65 TMU_BarLevel2 "2nd level of historgram
This value is converted form average MPG per 2.5 minutes";
CM_ SG_ 65 TMU_BarLevel4 "4th level of historgram
This value is converted form average MPG per 2.5 minutes";
CM_ SG_ 65 TMU_BarLevel3 "3rd level of historgram
This value is converted form average MPG per 2.5 minutes";
CM_ SG_ 65 TMU_BarLevel5 "5th level of historgram
This value is converted form average MPG per 2.5 minutes";
CM_ SG_ 65 TMU_BarLevel6 "6th level of historgram
This value is converted form average MPG per 2.5 minutes";
CM_ SG_ 65 TMU_BarLevel8 "8th level of historgram
This value is converted form average MPG per 2.5 minutes";
CM_ SG_ 65 TMU_BarLevel7 "7th level of historgram
This value is converted form average MPG per 2.5 minutes";
CM_ SG_ 65 TMU_BarLevel9 "9th level of historgram
This value is converted form average MPG per 2.5 minutes";
CM_ SG_ 65 TMU_BarLevel10 "10th level of historgram
This value is converted form average MPG per 2.5 minutes";
CM_ BO_ 1344 "[P] Periodic";
CM_ SG_ 1344 TMU_Arrow "Arrow";
CM_ SG_ 1344 TMU_ReFill_Info "TMU shall send ClearRequest to HU when fuel is refilled.";
CM_ SG_ 1344 TMU_AverageMPG "E=N*0.1
MPG range = 0 ~ 35.9(TBD)";
CM_ SG_ 1344 TMU_TotalMPG "E=N*0.1
MPG range = 0 ~ 35.9(TBD)";
CM_ SG_ 1344 TMU_RewardStar "Reward Star";
CM_ BO_ 64 "[EC] On Event and On Change";
CM_ SG_ 64 TMU_DisMode "This signal shall be set to proper display mode
before requesting display to HU";
CM_ SG_ 64 TMU_AudSrcType "This signal shall be set to proper source type
before requesting audio allocation";
CM_ SG_ 64 TMU_AudReqCmd "TMU shall set this signal before generating or releasing audio sound";
CM_ SG_ 64 TMU_LangCmd "If language of TMU is changed, this signal shall be set to the changed language";
CM_ SG_ 64 TMU_ServReq "If song tag is requested by VR command, this signal shall be set to 'Song Tag'.
If TMU is in SVR mode, this signal shall be set to 'Power On by Stolen Vehicle'.";
CM_ SG_ 64 TMU_ErrorEvent "If there is any error, this signal shall be set.";
CM_ SG_ 64 TMU_BeepCmd "TMU shall set this signal before generating or releasing audio sound";
CM_ SG_ 64 TMU_eCall "This signal shall be set to 0x01 when eCall mode and 0x03 when Test mode. If H/U receive 0x01 or 0x03, H/U mute all sound and eCall unit can get MIC operational control with relative Pop-up message.";
BA_DEF_ SG_  "Gatewaysignal" ENUM  "No","M-B","B-M","M-C","C-M","M-C-B";
BA_DEF_ SG_  "GenSigEnvVarType" ENUM  "Int","Float","undef";
BA_DEF_ SG_  "GenSigSendType" ENUM  "Cyclic","OnWrite","OnWriteWithRepetition","OnChange","OnChangeWithRepetition","IfActive","IfActiveWithRepetition","NoSigSendType";
BA_DEF_ SG_  "GenSigStartValue" INT 0 0;
BA_DEF_ SG_  "GwSigLatencyTime" INT 0 65535;
BA_DEF_ SG_  "GwSigMissingSourceType" ENUM  "Undef","OldValue","DefaultValue","InitialValue";
BA_DEF_ SG_  "NmNetworkRequest" ENUM  "No","Yes";
BA_DEF_ SG_  "NmNetworkRequestHoldingTime" INT 0 65535;
BA_DEF_ SG_  "Purpose" ENUM  "<t.b.d.>","Function","Diagnostic","Development","NM";
BA_DEF_ SG_  "SignalCategory" HEX 10 15;
BA_DEF_ SG_  "TimeoutValue" STRING ;
BA_DEF_ SG_  "UpdateRateMax" INT 0 0;
BA_DEF_ SG_  "UpdateRateMin" INT 0 0;
BA_DEF_ SG_  "Validity" ENUM  "B+","ACC","IGN1","IGN2";
BA_DEF_ BO_  "DiagRequest" ENUM  "No","Yes";
BA_DEF_ BO_  "DiagResponse" ENUM  "No","Yes";
BA_DEF_ BO_  "DiagState" ENUM  "No","Yes";
BA_DEF_ BO_  "GenMsgCycleTime" INT 0 100000;
BA_DEF_ BO_  "GenMsgCycleTimeFast" INT 0 500;
BA_DEF_ BO_  "GenMsgDelayTime" INT 0 20;
BA_DEF_ BO_  "GenMsgEVName" STRING ;
BA_DEF_ BO_  "GenMsgILSupport" ENUM  "No","Yes";
BA_DEF_ BO_  "GenMsgNrOfRepetition" INT 0 3;
BA_DEF_ BO_  "GenMsgSendType" ENUM  "Cyclic","not_used","not_used","not_used","not_used","not_used","not_used","not_used","NoMsgSendType";
BA_DEF_ BO_  "GenMsgStartDelayTime" INT 0 2000;
BA_DEF_ BO_  "NmMessage" ENUM  "No","Yes";
BA_DEF_ BO_  "RoutingType" ENUM  "<n.a.>","Direct","Indirect";
BA_DEF_ BO_  "TpMessage" ENUM  "No","Yes";
BA_DEF_ BO_  "TpTxIndex" INT 0 255;
BA_DEF_REL_ BU_SG_REL_  "GenSigTimeoutTime" INT 0 7000;
BA_DEF_DEF_  "Gatewaysignal" "No";
BA_DEF_DEF_  "GenSigEnvVarType" "undef";
BA_DEF_DEF_  "GenSigSendType" "NoSigSendType";
BA_DEF_DEF_  "GenSigStartValue" 0;
BA_DEF_DEF_  "GwSigLatencyTime" 40;
BA_DEF_DEF_  "GwSigMissingSourceType" "Undef";
BA_DEF_DEF_  "NmNetworkRequest" "No";
BA_DEF_DEF_  "NmNetworkRequestHoldingTime" 0;
BA_DEF_DEF_  "Purpose" "<t.b.d.>";
BA_DEF_DEF_  "SignalCategory" 12;
BA_DEF_DEF_  "TimeoutValue" "";
BA_DEF_DEF_  "UpdateRateMax" 0;
BA_DEF_DEF_  "UpdateRateMin" 0;
BA_DEF_DEF_  "Validity" "ACC";
BA_DEF_DEF_  "DiagRequest" "No";
BA_DEF_DEF_  "DiagResponse" "No";
BA_DEF_DEF_  "DiagState" "No";
BA_DEF_DEF_  "GenMsgCycleTime" 0;
BA_DEF_DEF_  "GenMsgCycleTimeFast" 0;
BA_DEF_DEF_  "GenMsgDelayTime" 20;
BA_DEF_DEF_  "GenMsgEVName" "@Signame";
BA_DEF_DEF_  "GenMsgILSupport" "Yes";
BA_DEF_DEF_  "GenMsgNrOfRepetition" 0;
BA_DEF_DEF_  "GenMsgSendType" "NoMsgSendType";
BA_DEF_DEF_  "GenMsgStartDelayTime" 0;
BA_DEF_DEF_  "NmMessage" "No";
BA_DEF_DEF_  "RoutingType" "<n.a.>";
BA_DEF_DEF_  "TpMessage" "No";
BA_DEF_DEF_  "TpTxIndex" 0;
BA_DEF_DEF_REL_ "GenSigTimeoutTime" 700;
BA_ "GenMsgCycleTimeFast" BO_ 139 40;
BA_ "GenMsgNrOfRepetition" BO_ 139 3;
BA_ "GenMsgCycleTimeFast" BO_ 138 40;
BA_ "GenMsgNrOfRepetition" BO_ 138 3;
BA_ "GenMsgCycleTimeFast" BO_ 137 40;
BA_ "GenMsgNrOfRepetition" BO_ 137 3;
BA_ "DiagResponse" BO_ 1928 1;
BA_ "GenMsgILSupport" BO_ 1928 0;
BA_ "TpMessage" BO_ 1928 1;
BA_ "TpTxIndex" BO_ 1928 13;
BA_ "GenMsgCycleTimeFast" BO_ 136 40;
BA_ "GenMsgNrOfRepetition" BO_ 136 3;
BA_ "GenMsgCycleTimeFast" BO_ 135 40;
BA_ "GenMsgNrOfRepetition" BO_ 135 3;
BA_ "GenMsgCycleTimeFast" BO_ 134 40;
BA_ "GenMsgNrOfRepetition" BO_ 134 3;
BA_ "GenMsgILSupport" BO_ 1157 0;
BA_ "TpMessage" BO_ 1157 1;
BA_ "TpTxIndex" BO_ 1157 10;
BA_ "GenMsgCycleTimeFast" BO_ 133 40;
BA_ "GenMsgNrOfRepetition" BO_ 133 3;
BA_ "GenMsgSendType" BO_ 389 0;
BA_ "GenMsgCycleTime" BO_ 389 2000;
BA_ "GenMsgCycleTimeFast" BO_ 389 40;
BA_ "GenMsgNrOfRepetition" BO_ 389 3;
BA_ "GenMsgCycleTimeFast" BO_ 132 40;
BA_ "GenMsgNrOfRepetition" BO_ 132 3;
BA_ "GenMsgSendType" BO_ 388 0;
BA_ "GenMsgCycleTime" BO_ 388 2000;
BA_ "GenMsgCycleTimeFast" BO_ 388 40;
BA_ "GenMsgNrOfRepetition" BO_ 388 3;
BA_ "GenMsgILSupport" BO_ 1156 0;
BA_ "TpMessage" BO_ 1156 1;
BA_ "TpTxIndex" BO_ 1156 10;
BA_ "GenMsgCycleTimeFast" BO_ 131 40;
BA_ "GenMsgNrOfRepetition" BO_ 131 3;
BA_ "GenMsgSendType" BO_ 387 0;
BA_ "GenMsgCycleTime" BO_ 387 2000;
BA_ "GenMsgCycleTimeFast" BO_ 387 40;
BA_ "GenMsgNrOfRepetition" BO_ 387 3;
BA_ "GenMsgStartDelayTime" BO_ 387 30;
BA_ "GenMsgCycleTimeFast" BO_ 130 40;
BA_ "GenMsgNrOfRepetition" BO_ 130 3;
BA_ "GenMsgCycleTimeFast" BO_ 129 40;
BA_ "GenMsgNrOfRepetition" BO_ 129 3;
BA_ "GenMsgSendType" BO_ 385 0;
BA_ "GenMsgCycleTime" BO_ 385 1000;
BA_ "GenMsgCycleTimeFast" BO_ 385 40;
BA_ "GenMsgNrOfRepetition" BO_ 385 3;
BA_ "GenMsgStartDelayTime" BO_ 385 20;
BA_ "GenMsgCycleTimeFast" BO_ 128 40;
BA_ "GenMsgNrOfRepetition" BO_ 128 3;
BA_ "GenMsgSendType" BO_ 384 0;
BA_ "GenMsgCycleTime" BO_ 384 1000;
BA_ "GenMsgCycleTimeFast" BO_ 384 40;
BA_ "GenMsgNrOfRepetition" BO_ 384 3;
BA_ "GenMsgStartDelayTime" BO_ 384 10;
BA_ "GenMsgSendType" BO_ 1408 0;
BA_ "GenMsgCycleTime" BO_ 1408 200;
BA_ "DiagRequest" BO_ 1920 1;
BA_ "GenMsgILSupport" BO_ 1920 0;
BA_ "TpMessage" BO_ 1920 1;
BA_ "TpTxIndex" BO_ 1920 13;
BA_ "GenMsgSendType" BO_ 371 0;
BA_ "GenMsgCycleTime" BO_ 371 200;
BA_ "GenMsgCycleTimeFast" BO_ 371 40;
BA_ "GenMsgNrOfRepetition" BO_ 371 3;
BA_ "GenMsgStartDelayTime" BO_ 371 30;
BA_ "GenMsgSendType" BO_ 369 0;
BA_ "GenMsgCycleTime" BO_ 369 200;
BA_ "GenMsgCycleTimeFast" BO_ 369 40;
BA_ "GenMsgNrOfRepetition" BO_ 369 3;
BA_ "GenMsgStartDelayTime" BO_ 369 20;
BA_ "GenMsgSendType" BO_ 1392 0;
BA_ "GenMsgCycleTime" BO_ 1392 1000;
BA_ "GenMsgStartDelayTime" BO_ 1392 120;
BA_ "GenMsgCycleTimeFast" BO_ 112 40;
BA_ "GenMsgNrOfRepetition" BO_ 112 3;
BA_ "GenMsgSendType" BO_ 1390 0;
BA_ "GenMsgCycleTime" BO_ 1390 200;
BA_ "GenMsgSendType" BO_ 363 0;
BA_ "GenMsgCycleTime" BO_ 363 200;
BA_ "GenMsgCycleTimeFast" BO_ 363 40;
BA_ "GenMsgNrOfRepetition" BO_ 363 3;
BA_ "GenMsgStartDelayTime" BO_ 363 10;
BA_ "GenMsgSendType" BO_ 362 0;
BA_ "GenMsgCycleTime" BO_ 362 200;
BA_ "GenMsgCycleTimeFast" BO_ 362 40;
BA_ "GenMsgNrOfRepetition" BO_ 362 3;
BA_ "GenMsgStartDelayTime" BO_ 362 10;
BA_ "GenMsgSendType" BO_ 361 0;
BA_ "GenMsgCycleTime" BO_ 361 200;
BA_ "GenMsgCycleTimeFast" BO_ 361 40;
BA_ "GenMsgNrOfRepetition" BO_ 361 3;
BA_ "GenMsgSendType" BO_ 359 0;
BA_ "GenMsgCycleTime" BO_ 359 1000;
BA_ "GenMsgCycleTimeFast" BO_ 359 40;
BA_ "GenMsgNrOfRepetition" BO_ 359 3;
BA_ "GenMsgSendType" BO_ 1376 0;
BA_ "GenMsgCycleTime" BO_ 1376 1000;
BA_ "GenMsgCycleTimeFast" BO_ 93 40;
BA_ "GenMsgNrOfRepetition" BO_ 93 3;
BA_ "GenMsgSendType" BO_ 344 0;
BA_ "GenMsgCycleTime" BO_ 344 200;
BA_ "GenMsgCycleTimeFast" BO_ 344 40;
BA_ "GenMsgNrOfRepetition" BO_ 344 3;
BA_ "GenMsgCycleTimeFast" BO_ 87 40;
BA_ "GenMsgNrOfRepetition" BO_ 87 3;
BA_ "GenMsgSendType" BO_ 343 0;
BA_ "GenMsgCycleTime" BO_ 343 200;
BA_ "GenMsgCycleTimeFast" BO_ 75 40;
BA_ "GenMsgNrOfRepetition" BO_ 75 3;
BA_ "GenMsgCycleTimeFast" BO_ 74 40;
BA_ "GenMsgNrOfRepetition" BO_ 74 3;
BA_ "GenMsgILSupport" BO_ 1864 0;
BA_ "TpMessage" BO_ 1864 1;
BA_ "TpTxIndex" BO_ 1864 6;
BA_ "GenMsgSendType" BO_ 327 0;
BA_ "GenMsgCycleTime" BO_ 327 200;
BA_ "GenMsgCycleTimeFast" BO_ 327 40;
BA_ "GenMsgNrOfRepetition" BO_ 327 3;
BA_ "GenMsgStartDelayTime" BO_ 327 30;
BA_ "GenMsgSendType" BO_ 326 0;
BA_ "GenMsgCycleTime" BO_ 326 1000;
BA_ "GenMsgCycleTimeFast" BO_ 326 40;
BA_ "GenMsgNrOfRepetition" BO_ 326 3;
BA_ "GenMsgStartDelayTime" BO_ 326 20;
BA_ "GenMsgSendType" BO_ 325 0;
BA_ "GenMsgCycleTime" BO_ 325 200;
BA_ "GenMsgCycleTimeFast" BO_ 325 40;
BA_ "GenMsgNrOfRepetition" BO_ 325 3;
BA_ "GenMsgStartDelayTime" BO_ 325 10;
BA_ "GenMsgCycleTimeFast" BO_ 67 40;
BA_ "GenMsgNrOfRepetition" BO_ 67 3;
BA_ "GenMsgCycleTimeFast" BO_ 66 40;
BA_ "GenMsgNrOfRepetition" BO_ 66 3;
BA_ "GenMsgSendType" BO_ 1345 0;
BA_ "GenMsgCycleTime" BO_ 1345 1000;
BA_ "GenMsgStartDelayTime" BO_ 1345 10;
BA_ "GenMsgCycleTimeFast" BO_ 65 40;
BA_ "GenMsgNrOfRepetition" BO_ 65 3;
BA_ "GenMsgSendType" BO_ 1344 0;
BA_ "GenMsgCycleTime" BO_ 1344 2000;
BA_ "GenMsgCycleTimeFast" BO_ 64 40;
BA_ "GenMsgNrOfRepetition" BO_ 64 3;
BA_ "GenSigSendType" SG_ 139 AMP_Beep2VolumeState 2;
BA_ "GenSigStartValue" SG_ 139 AMP_Beep2VolumeState 255;
BA_ "NmNetworkRequest" SG_ 139 AMP_Beep2VolumeState 1;
BA_ "GenSigSendType" SG_ 139 AMP_Beep2FrequencyState 2;
BA_ "GenSigStartValue" SG_ 139 AMP_Beep2FrequencyState 65535;
BA_ "NmNetworkRequest" SG_ 139 AMP_Beep2FrequencyState 1;
BA_ "GenSigSendType" SG_ 139 AMP_Beep2OutputMaskState 2;
BA_ "GenSigStartValue" SG_ 139 AMP_Beep2OutputMaskState 65535;
BA_ "NmNetworkRequest" SG_ 139 AMP_Beep2OutputMaskState 1;
BA_ "GenSigSendType" SG_ 139 AMP_Beep2DOnState 2;
BA_ "GenSigStartValue" SG_ 139 AMP_Beep2DOnState 255;
BA_ "NmNetworkRequest" SG_ 139 AMP_Beep2DOnState 1;
BA_ "GenSigSendType" SG_ 139 AMP_Beep2DOffState 2;
BA_ "GenSigStartValue" SG_ 139 AMP_Beep2DOffState 255;
BA_ "NmNetworkRequest" SG_ 139 AMP_Beep2DOffState 1;
BA_ "GenSigSendType" SG_ 139 AMP_Beep2NOfCycleState 2;
BA_ "GenSigStartValue" SG_ 139 AMP_Beep2NOfCycleState 255;
BA_ "NmNetworkRequest" SG_ 139 AMP_Beep2NOfCycleState 1;
BA_ "GenSigSendType" SG_ 138 AMP_Beep1VolumeState 2;
BA_ "GenSigStartValue" SG_ 138 AMP_Beep1VolumeState 255;
BA_ "NmNetworkRequest" SG_ 138 AMP_Beep1VolumeState 1;
BA_ "GenSigSendType" SG_ 138 AMP_Beep1FrequencyState 2;
BA_ "GenSigStartValue" SG_ 138 AMP_Beep1FrequencyState 65535;
BA_ "NmNetworkRequest" SG_ 138 AMP_Beep1FrequencyState 1;
BA_ "GenSigSendType" SG_ 138 AMP_Beep1OutputMaskState 2;
BA_ "GenSigStartValue" SG_ 138 AMP_Beep1OutputMaskState 65535;
BA_ "NmNetworkRequest" SG_ 138 AMP_Beep1OutputMaskState 1;
BA_ "GenSigSendType" SG_ 138 AMP_Beep1DOnState 2;
BA_ "GenSigStartValue" SG_ 138 AMP_Beep1DOnState 255;
BA_ "NmNetworkRequest" SG_ 138 AMP_Beep1DOnState 1;
BA_ "GenSigSendType" SG_ 138 AMP_Beep1DOffState 2;
BA_ "GenSigStartValue" SG_ 138 AMP_Beep1DOffState 255;
BA_ "NmNetworkRequest" SG_ 138 AMP_Beep1DOffState 1;
BA_ "GenSigSendType" SG_ 138 AMP_Beep1NOfCycleState 2;
BA_ "GenSigStartValue" SG_ 138 AMP_Beep1NOfCycleState 255;
BA_ "NmNetworkRequest" SG_ 138 AMP_Beep1NOfCycleState 1;
BA_ "GenSigSendType" SG_ 137 AMP_MTSOutputMaskSupport 4;
BA_ "GenSigStartValue" SG_ 137 AMP_MTSOutputMaskSupport 3;
BA_ "NmNetworkRequest" SG_ 137 AMP_MTSOutputMaskSupport 1;
BA_ "GenSigSendType" SG_ 137 AMP_MTSMuteMaskSupport 4;
BA_ "GenSigStartValue" SG_ 137 AMP_MTSMuteMaskSupport 3;
BA_ "NmNetworkRequest" SG_ 137 AMP_MTSMuteMaskSupport 1;
BA_ "GenSigSendType" SG_ 137 AMP_HFOutputMaskSupport 4;
BA_ "GenSigStartValue" SG_ 137 AMP_HFOutputMaskSupport 3;
BA_ "NmNetworkRequest" SG_ 137 AMP_HFOutputMaskSupport 1;
BA_ "GenSigSendType" SG_ 137 AMP_HFMuteMaskSupport 4;
BA_ "GenSigStartValue" SG_ 137 AMP_HFMuteMaskSupport 3;
BA_ "NmNetworkRequest" SG_ 137 AMP_HFMuteMaskSupport 1;
BA_ "GenSigSendType" SG_ 137 AMP_NaviOutputMaskSupport 4;
BA_ "GenSigStartValue" SG_ 137 AMP_NaviOutputMaskSupport 3;
BA_ "NmNetworkRequest" SG_ 137 AMP_NaviOutputMaskSupport 1;
BA_ "GenSigSendType" SG_ 137 AMP_NaviMuteMaskSupport 4;
BA_ "GenSigStartValue" SG_ 137 AMP_NaviMuteMaskSupport 3;
BA_ "NmNetworkRequest" SG_ 137 AMP_NaviMuteMaskSupport 1;
BA_ "GenSigSendType" SG_ 136 AMP_MaxBeep2VolumeState 4;
BA_ "GenSigStartValue" SG_ 136 AMP_MaxBeep2VolumeState 255;
BA_ "NmNetworkRequest" SG_ 136 AMP_MaxBeep2VolumeState 1;
BA_ "GenSigSendType" SG_ 136 AMP_MaxBeep2Freq_State 4;
BA_ "GenSigStartValue" SG_ 136 AMP_MaxBeep2Freq_State 65535;
BA_ "NmNetworkRequest" SG_ 136 AMP_MaxBeep2Freq_State 1;
BA_ "GenSigSendType" SG_ 136 AMP_Beep2OutputMaskSup 4;
BA_ "GenSigStartValue" SG_ 136 AMP_Beep2OutputMaskSup 3;
BA_ "NmNetworkRequest" SG_ 136 AMP_Beep2OutputMaskSup 1;
BA_ "GenSigSendType" SG_ 136 AMP_MaxBeep2DOnState 4;
BA_ "GenSigStartValue" SG_ 136 AMP_MaxBeep2DOnState 255;
BA_ "NmNetworkRequest" SG_ 136 AMP_MaxBeep2DOnState 1;
BA_ "GenSigSendType" SG_ 136 AMP_MaxBeep2DOffState 4;
BA_ "GenSigStartValue" SG_ 136 AMP_MaxBeep2DOffState 255;
BA_ "NmNetworkRequest" SG_ 136 AMP_MaxBeep2DOffState 1;
BA_ "GenSigSendType" SG_ 136 AMP_MaxBeep2NOfCycleState 4;
BA_ "GenSigStartValue" SG_ 136 AMP_MaxBeep2NOfCycleState 255;
BA_ "NmNetworkRequest" SG_ 136 AMP_MaxBeep2NOfCycleState 1;
BA_ "GenSigSendType" SG_ 135 AMP_MaxBeep1VolumeState 4;
BA_ "GenSigStartValue" SG_ 135 AMP_MaxBeep1VolumeState 255;
BA_ "NmNetworkRequest" SG_ 135 AMP_MaxBeep1VolumeState 1;
BA_ "GenSigSendType" SG_ 135 AMP_MaxBeep1Freq_State 4;
BA_ "GenSigStartValue" SG_ 135 AMP_MaxBeep1Freq_State 65535;
BA_ "NmNetworkRequest" SG_ 135 AMP_MaxBeep1Freq_State 1;
BA_ "GenSigSendType" SG_ 135 AMP_Beep1OutputMaskSup 4;
BA_ "GenSigStartValue" SG_ 135 AMP_Beep1OutputMaskSup 3;
BA_ "NmNetworkRequest" SG_ 135 AMP_Beep1OutputMaskSup 1;
BA_ "GenSigSendType" SG_ 135 AMP_MaxBeep1DOnState 4;
BA_ "GenSigStartValue" SG_ 135 AMP_MaxBeep1DOnState 255;
BA_ "NmNetworkRequest" SG_ 135 AMP_MaxBeep1DOnState 1;
BA_ "GenSigSendType" SG_ 135 AMP_MaxBeep1DOffState 4;
BA_ "GenSigStartValue" SG_ 135 AMP_MaxBeep1DOffState 255;
BA_ "NmNetworkRequest" SG_ 135 AMP_MaxBeep1DOffState 1;
BA_ "GenSigSendType" SG_ 135 AMP_MaxBeep1NOfCycleState 4;
BA_ "GenSigStartValue" SG_ 135 AMP_MaxBeep1NOfCycleState 255;
BA_ "NmNetworkRequest" SG_ 135 AMP_MaxBeep1NOfCycleState 1;
BA_ "GenSigSendType" SG_ 134 ASD_SetValue 4;
BA_ "GenSigStartValue" SG_ 134 ASD_SetValue 7;
BA_ "NmNetworkRequest" SG_ 134 ASD_SetValue 1;
BA_ "GenSigSendType" SG_ 134 ASD_Version 4;
BA_ "GenSigStartValue" SG_ 134 ASD_Version 255;
BA_ "NmNetworkRequest" SG_ 134 ASD_Version 1;
BA_ "GenSigSendType" SG_ 133 AMP_MaxVolumeStep 4;
BA_ "GenSigStartValue" SG_ 133 AMP_MaxVolumeStep 255;
BA_ "NmNetworkRequest" SG_ 133 AMP_MaxVolumeStep 1;
BA_ "GenSigSendType" SG_ 133 AMP_MaxBalanceStep 4;
BA_ "GenSigStartValue" SG_ 133 AMP_MaxBalanceStep 255;
BA_ "NmNetworkRequest" SG_ 133 AMP_MaxBalanceStep 1;
BA_ "GenSigSendType" SG_ 133 AMP_MaxFadeStep 4;
BA_ "GenSigStartValue" SG_ 133 AMP_MaxFadeStep 255;
BA_ "NmNetworkRequest" SG_ 133 AMP_MaxFadeStep 1;
BA_ "GenSigSendType" SG_ 133 AMP_MaxBassStep 4;
BA_ "GenSigStartValue" SG_ 133 AMP_MaxBassStep 255;
BA_ "NmNetworkRequest" SG_ 133 AMP_MaxBassStep 1;
BA_ "GenSigSendType" SG_ 133 AMP_MaxMidStep 4;
BA_ "GenSigStartValue" SG_ 133 AMP_MaxMidStep 255;
BA_ "NmNetworkRequest" SG_ 133 AMP_MaxMidStep 1;
BA_ "GenSigSendType" SG_ 133 AMP_MaxTrebleStep 4;
BA_ "GenSigStartValue" SG_ 133 AMP_MaxTrebleStep 255;
BA_ "NmNetworkRequest" SG_ 133 AMP_MaxTrebleStep 1;
BA_ "GenSigSendType" SG_ 133 AMP_ASDMajorVer 4;
BA_ "GenSigStartValue" SG_ 133 AMP_ASDMajorVer 255;
BA_ "NmNetworkRequest" SG_ 133 AMP_ASDMajorVer 1;
BA_ "GenSigSendType" SG_ 133 AMP_ASDMinorVer 4;
BA_ "GenSigStartValue" SG_ 133 AMP_ASDMinorVer 255;
BA_ "NmNetworkRequest" SG_ 133 AMP_ASDMinorVer 1;
BA_ "GenSigSendType" SG_ 389 AMP_EngOrderC2Setting 4;
BA_ "GenSigStartValue" SG_ 389 AMP_EngOrderC2Setting 255;
BA_ "NmNetworkRequest" SG_ 389 AMP_EngOrderC2Setting 1;
BA_ "GenSigSendType" SG_ 389 AMP_EngOrderC4Setting 4;
BA_ "GenSigStartValue" SG_ 389 AMP_EngOrderC4Setting 255;
BA_ "NmNetworkRequest" SG_ 389 AMP_EngOrderC4Setting 1;
BA_ "GenSigSendType" SG_ 389 AMP_EngOrderC6Setting 4;
BA_ "GenSigStartValue" SG_ 389 AMP_EngOrderC6Setting 255;
BA_ "NmNetworkRequest" SG_ 389 AMP_EngOrderC6Setting 1;
BA_ "GenSigSendType" SG_ 389 AMP_APSBand0Setting 4;
BA_ "GenSigStartValue" SG_ 389 AMP_APSBand0Setting 255;
BA_ "NmNetworkRequest" SG_ 389 AMP_APSBand0Setting 1;
BA_ "GenSigSendType" SG_ 389 AMP_APSBand1Setting 4;
BA_ "GenSigStartValue" SG_ 389 AMP_APSBand1Setting 255;
BA_ "NmNetworkRequest" SG_ 389 AMP_APSBand1Setting 1;
BA_ "GenSigSendType" SG_ 389 AMP_APSBand2Setting 4;
BA_ "GenSigStartValue" SG_ 389 AMP_APSBand2Setting 255;
BA_ "NmNetworkRequest" SG_ 389 AMP_APSBand2Setting 1;
BA_ "GenSigSendType" SG_ 389 AMP_APSBand3Setting 4;
BA_ "GenSigStartValue" SG_ 389 AMP_APSBand3Setting 255;
BA_ "NmNetworkRequest" SG_ 389 AMP_APSBand3Setting 1;
BA_ "GenSigSendType" SG_ 389 AMP_APSBand4Setting 4;
BA_ "GenSigStartValue" SG_ 389 AMP_APSBand4Setting 255;
BA_ "NmNetworkRequest" SG_ 389 AMP_APSBand4Setting 1;
BA_ "GenSigSendType" SG_ 132 AMP_HFVolumeState 4;
BA_ "GenSigStartValue" SG_ 132 AMP_HFVolumeState 255;
BA_ "NmNetworkRequest" SG_ 132 AMP_HFVolumeState 1;
BA_ "GenSigSendType" SG_ 132 AMP_HFAudioCutState 4;
BA_ "GenSigStartValue" SG_ 132 AMP_HFAudioCutState 255;
BA_ "NmNetworkRequest" SG_ 132 AMP_HFAudioCutState 1;
BA_ "GenSigSendType" SG_ 132 AMP_HFOutputMaskState 4;
BA_ "GenSigStartValue" SG_ 132 AMP_HFOutputMaskState 65535;
BA_ "NmNetworkRequest" SG_ 132 AMP_HFOutputMaskState 1;
BA_ "GenSigSendType" SG_ 132 AMP_HFMuteMaskState 4;
BA_ "GenSigStartValue" SG_ 132 AMP_HFMuteMaskState 65535;
BA_ "NmNetworkRequest" SG_ 132 AMP_HFMuteMaskState 1;
BA_ "GenSigSendType" SG_ 132 AMP_MaxHFVolumeState 4;
BA_ "GenSigStartValue" SG_ 132 AMP_MaxHFVolumeState 255;
BA_ "NmNetworkRequest" SG_ 132 AMP_MaxHFVolumeState 1;
BA_ "GenSigSendType" SG_ 132 AMP_MaxHFAudioCutState 4;
BA_ "GenSigStartValue" SG_ 132 AMP_MaxHFAudioCutState 255;
BA_ "NmNetworkRequest" SG_ 132 AMP_MaxHFAudioCutState 1;
BA_ "GenSigSendType" SG_ 388 AMP_PESSModeState 4;
BA_ "GenSigStartValue" SG_ 388 AMP_PESSModeState 3;
BA_ "NmNetworkRequest" SG_ 388 AMP_PESSModeState 1;
BA_ "GenSigSendType" SG_ 388 AMP_PESSDesignSetting 4;
BA_ "GenSigStartValue" SG_ 388 AMP_PESSDesignSetting 7;
BA_ "NmNetworkRequest" SG_ 388 AMP_PESSDesignSetting 1;
BA_ "GenSigSendType" SG_ 388 AMP_PESSAPSSetting 4;
BA_ "GenSigStartValue" SG_ 388 AMP_PESSAPSSetting 7;
BA_ "NmNetworkRequest" SG_ 388 AMP_PESSAPSSetting 1;
BA_ "GenSigSendType" SG_ 388 AMP_PESSVolumeSetting 4;
BA_ "GenSigStartValue" SG_ 388 AMP_PESSVolumeSetting 255;
BA_ "NmNetworkRequest" SG_ 388 AMP_PESSVolumeSetting 1;
BA_ "GenSigSendType" SG_ 131 AMP_MTSVolumeState 4;
BA_ "GenSigStartValue" SG_ 131 AMP_MTSVolumeState 255;
BA_ "NmNetworkRequest" SG_ 131 AMP_MTSVolumeState 1;
BA_ "GenSigSendType" SG_ 131 AMP_MTSAudioCutState 4;
BA_ "GenSigStartValue" SG_ 131 AMP_MTSAudioCutState 255;
BA_ "NmNetworkRequest" SG_ 131 AMP_MTSAudioCutState 1;
BA_ "GenSigSendType" SG_ 131 AMP_MTSOutputMaskState 4;
BA_ "GenSigStartValue" SG_ 131 AMP_MTSOutputMaskState 65535;
BA_ "NmNetworkRequest" SG_ 131 AMP_MTSOutputMaskState 1;
BA_ "GenSigSendType" SG_ 131 AMP_MTSMuteMaskState 4;
BA_ "GenSigStartValue" SG_ 131 AMP_MTSMuteMaskState 65535;
BA_ "NmNetworkRequest" SG_ 131 AMP_MTSMuteMaskState 1;
BA_ "GenSigSendType" SG_ 131 AMP_MaxMTSVolumeState 4;
BA_ "GenSigStartValue" SG_ 131 AMP_MaxMTSVolumeState 255;
BA_ "NmNetworkRequest" SG_ 131 AMP_MaxMTSVolumeState 1;
BA_ "GenSigSendType" SG_ 131 AMP_MaxMTSAudioCutState 4;
BA_ "GenSigStartValue" SG_ 131 AMP_MaxMTSAudioCutState 255;
BA_ "NmNetworkRequest" SG_ 131 AMP_MaxMTSAudioCutState 1;
BA_ "GenSigSendType" SG_ 387 AMP_MainVolumeSetting 4;
BA_ "GenSigStartValue" SG_ 387 AMP_MainVolumeSetting 255;
BA_ "NmNetworkRequest" SG_ 387 AMP_MainVolumeSetting 1;
BA_ "TimeoutValue" SG_ 387 AMP_MainVolumeSetting "0xFF";
BA_ "GenSigSendType" SG_ 387 AMP_BalanceSetting 4;
BA_ "GenSigStartValue" SG_ 387 AMP_BalanceSetting 255;
BA_ "NmNetworkRequest" SG_ 387 AMP_BalanceSetting 1;
BA_ "TimeoutValue" SG_ 387 AMP_BalanceSetting "0xFF";
BA_ "GenSigSendType" SG_ 387 AMP_FadeSetting 4;
BA_ "GenSigStartValue" SG_ 387 AMP_FadeSetting 255;
BA_ "NmNetworkRequest" SG_ 387 AMP_FadeSetting 1;
BA_ "TimeoutValue" SG_ 387 AMP_FadeSetting "0xFF";
BA_ "GenSigSendType" SG_ 387 AMP_BassSetting 4;
BA_ "GenSigStartValue" SG_ 387 AMP_BassSetting 255;
BA_ "NmNetworkRequest" SG_ 387 AMP_BassSetting 1;
BA_ "TimeoutValue" SG_ 387 AMP_BassSetting "0xFF";
BA_ "GenSigSendType" SG_ 387 AMP_MidSetting 4;
BA_ "GenSigStartValue" SG_ 387 AMP_MidSetting 255;
BA_ "NmNetworkRequest" SG_ 387 AMP_MidSetting 1;
BA_ "TimeoutValue" SG_ 387 AMP_MidSetting "0xFF";
BA_ "GenSigSendType" SG_ 387 AMP_TrebleSetting 4;
BA_ "GenSigStartValue" SG_ 387 AMP_TrebleSetting 255;
BA_ "NmNetworkRequest" SG_ 387 AMP_TrebleSetting 1;
BA_ "TimeoutValue" SG_ 387 AMP_TrebleSetting "0xFF";
BA_ "GenSigSendType" SG_ 387 AMP_VehicleSpeedamp 4;
BA_ "GenSigStartValue" SG_ 387 AMP_VehicleSpeedamp 255;
BA_ "NmNetworkRequest" SG_ 387 AMP_VehicleSpeedamp 1;
BA_ "TimeoutValue" SG_ 387 AMP_VehicleSpeedamp "0xFF";
BA_ "GenSigSendType" SG_ 130 AMP_NaviVolumeState 4;
BA_ "GenSigStartValue" SG_ 130 AMP_NaviVolumeState 255;
BA_ "NmNetworkRequest" SG_ 130 AMP_NaviVolumeState 1;
BA_ "GenSigSendType" SG_ 130 AMP_NaviAudioCutState 4;
BA_ "GenSigStartValue" SG_ 130 AMP_NaviAudioCutState 255;
BA_ "NmNetworkRequest" SG_ 130 AMP_NaviAudioCutState 1;
BA_ "GenSigSendType" SG_ 130 AMP_NaviOutputMaskState 4;
BA_ "GenSigStartValue" SG_ 130 AMP_NaviOutputMaskState 65535;
BA_ "NmNetworkRequest" SG_ 130 AMP_NaviOutputMaskState 1;
BA_ "GenSigSendType" SG_ 130 AMP_NaviMuteMaskState 4;
BA_ "GenSigStartValue" SG_ 130 AMP_NaviMuteMaskState 65535;
BA_ "NmNetworkRequest" SG_ 130 AMP_NaviMuteMaskState 1;
BA_ "GenSigSendType" SG_ 130 AMP_MaxNaviVolumeState 4;
BA_ "GenSigStartValue" SG_ 130 AMP_MaxNaviVolumeState 255;
BA_ "NmNetworkRequest" SG_ 130 AMP_MaxNaviVolumeState 1;
BA_ "GenSigSendType" SG_ 130 AMP_MaxNaviAudioCutState 4;
BA_ "GenSigStartValue" SG_ 130 AMP_MaxNaviAudioCutState 255;
BA_ "NmNetworkRequest" SG_ 130 AMP_MaxNaviAudioCutState 1;
BA_ "GenSigSendType" SG_ 129 AMP_DriveState 4;
BA_ "GenSigStartValue" SG_ 129 AMP_DriveState 3;
BA_ "NmNetworkRequest" SG_ 129 AMP_DriveState 1;
BA_ "GenSigSendType" SG_ 129 AMP_ConvertibleTopState 4;
BA_ "GenSigStartValue" SG_ 129 AMP_ConvertibleTopState 3;
BA_ "NmNetworkRequest" SG_ 129 AMP_ConvertibleTopState 1;
BA_ "GenSigSendType" SG_ 385 AMP_MuteState 4;
BA_ "GenSigStartValue" SG_ 385 AMP_MuteState 3;
BA_ "NmNetworkRequest" SG_ 385 AMP_MuteState 1;
BA_ "TimeoutValue" SG_ 385 AMP_MuteState "0x3";
BA_ "GenSigSendType" SG_ 385 AMP_RearSpMuteState 4;
BA_ "GenSigStartValue" SG_ 385 AMP_RearSpMuteState 3;
BA_ "NmNetworkRequest" SG_ 385 AMP_RearSpMuteState 1;
BA_ "TimeoutValue" SG_ 385 AMP_RearSpMuteState "0x3";
BA_ "GenSigSendType" SG_ 385 AMP_SurroundModeState 4;
BA_ "GenSigStartValue" SG_ 385 AMP_SurroundModeState 3;
BA_ "NmNetworkRequest" SG_ 385 AMP_SurroundModeState 1;
BA_ "TimeoutValue" SG_ 385 AMP_SurroundModeState "0x3";
BA_ "GenSigSendType" SG_ 385 AMP_EQState 4;
BA_ "GenSigStartValue" SG_ 385 AMP_EQState 3;
BA_ "NmNetworkRequest" SG_ 385 AMP_EQState 1;
BA_ "TimeoutValue" SG_ 385 AMP_EQState "0x3";
BA_ "GenSigSendType" SG_ 385 AMP_SPDIFMuteSt 4;
BA_ "GenSigStartValue" SG_ 385 AMP_SPDIFMuteSt 1;
BA_ "NmNetworkRequest" SG_ 385 AMP_SPDIFMuteSt 1;
BA_ "TimeoutValue" SG_ 385 AMP_SPDIFMuteSt "0x3";
BA_ "GenSigSendType" SG_ 385 AMP_BeatsModeState 3;
BA_ "GenSigStartValue" SG_ 385 AMP_BeatsModeState 3;
BA_ "GenSigSendType" SG_ 385 AMP_DefaultBeep1St 4;
BA_ "NmNetworkRequest" SG_ 385 AMP_DefaultBeep1St 1;
BA_ "TimeoutValue" SG_ 385 AMP_DefaultBeep1St "0x3";
BA_ "GenSigSendType" SG_ 385 AMP_DefaultBeep2St 4;
BA_ "NmNetworkRequest" SG_ 385 AMP_DefaultBeep2St 1;
BA_ "TimeoutValue" SG_ 385 AMP_DefaultBeep2St "0x3";
BA_ "GenSigSendType" SG_ 385 AMP_AudioSource 4;
BA_ "GenSigStartValue" SG_ 385 AMP_AudioSource 255;
BA_ "NmNetworkRequest" SG_ 385 AMP_AudioSource 1;
BA_ "TimeoutValue" SG_ 385 AMP_AudioSource "0xFF";
BA_ "GenSigSendType" SG_ 385 AMP_VIPModeState 3;
BA_ "GenSigStartValue" SG_ 385 AMP_VIPModeState 3;
BA_ "GenSigSendType" SG_ 385 AMP_QLSModeState 3;
BA_ "GenSigStartValue" SG_ 385 AMP_QLSModeState 3;
BA_ "GenSigSendType" SG_ 128 AMP_CurrentVehicleID 4;
BA_ "GenSigStartValue" SG_ 128 AMP_CurrentVehicleID 255;
BA_ "NmNetworkRequest" SG_ 128 AMP_CurrentVehicleID 1;
BA_ "GenSigSendType" SG_ 128 AMP_SPDIFModeState 4;
BA_ "GenSigStartValue" SG_ 128 AMP_SPDIFModeState 15;
BA_ "NmNetworkRequest" SG_ 128 AMP_SPDIFModeState 1;
BA_ "GenSigSendType" SG_ 128 AMP_MajorVer 4;
BA_ "GenSigStartValue" SG_ 128 AMP_MajorVer 255;
BA_ "NmNetworkRequest" SG_ 128 AMP_MajorVer 1;
BA_ "GenSigSendType" SG_ 128 AMP_MinorVer 4;
BA_ "GenSigStartValue" SG_ 128 AMP_MinorVer 255;
BA_ "NmNetworkRequest" SG_ 128 AMP_MinorVer 1;
BA_ "GenSigSendType" SG_ 128 AMP_UpdateStartResp 4;
BA_ "GenSigStartValue" SG_ 128 AMP_UpdateStartResp 3;
BA_ "NmNetworkRequest" SG_ 128 AMP_UpdateStartResp 1;
BA_ "GenSigSendType" SG_ 128 AMP_UpdateEndResp 4;
BA_ "GenSigStartValue" SG_ 128 AMP_UpdateEndResp 3;
BA_ "NmNetworkRequest" SG_ 128 AMP_UpdateEndResp 1;
BA_ "GenSigSendType" SG_ 128 AMP_TuningMajorVer 4;
BA_ "GenSigStartValue" SG_ 128 AMP_TuningMajorVer 255;
BA_ "NmNetworkRequest" SG_ 128 AMP_TuningMajorVer 1;
BA_ "GenSigSendType" SG_ 128 AMP_TuningMinorVer 4;
BA_ "GenSigStartValue" SG_ 128 AMP_TuningMinorVer 255;
BA_ "NmNetworkRequest" SG_ 128 AMP_TuningMinorVer 1;
BA_ "GenSigSendType" SG_ 384 AMP_HFModeState 4;
BA_ "GenSigStartValue" SG_ 384 AMP_HFModeState 3;
BA_ "NmNetworkRequest" SG_ 384 AMP_HFModeState 1;
BA_ "TimeoutValue" SG_ 384 AMP_HFModeState "0x3";
BA_ "GenSigSendType" SG_ 384 HU_InitInfo 3;
BA_ "GenSigStartValue" SG_ 384 HU_InitInfo 3;
BA_ "GenSigSendType" SG_ 384 AMP_ASDModeState 4;
BA_ "GenSigStartValue" SG_ 384 AMP_ASDModeState 7;
BA_ "NmNetworkRequest" SG_ 384 AMP_ASDModeState 1;
BA_ "TimeoutValue" SG_ 384 AMP_ASDModeState "0x7";
BA_ "GenSigSendType" SG_ 384 AMP_NaviModeState 4;
BA_ "GenSigStartValue" SG_ 384 AMP_NaviModeState 3;
BA_ "NmNetworkRequest" SG_ 384 AMP_NaviModeState 1;
BA_ "TimeoutValue" SG_ 384 AMP_NaviModeState "0x3";
BA_ "GenSigSendType" SG_ 384 AMP_SPDIFInfo 3;
BA_ "GenSigStartValue" SG_ 384 AMP_SPDIFInfo 7;
BA_ "GenSigSendType" SG_ 384 AMP_MTSModeState 4;
BA_ "GenSigStartValue" SG_ 384 AMP_MTSModeState 3;
BA_ "NmNetworkRequest" SG_ 384 AMP_MTSModeState 1;
BA_ "TimeoutValue" SG_ 384 AMP_MTSModeState "0x3";
BA_ "GenSigSendType" SG_ 384 AMP_VSCModeState 4;
BA_ "GenSigStartValue" SG_ 384 AMP_VSCModeState 3;
BA_ "NmNetworkRequest" SG_ 384 AMP_VSCModeState 1;
BA_ "TimeoutValue" SG_ 384 AMP_VSCModeState "0x3";
BA_ "GenSigSendType" SG_ 384 AMP_SDVCStepState 4;
BA_ "GenSigStartValue" SG_ 384 AMP_SDVCStepState 7;
BA_ "NmNetworkRequest" SG_ 384 AMP_SDVCStepState 1;
BA_ "TimeoutValue" SG_ 384 AMP_SDVCStepState "0x7";
BA_ "GenSigSendType" SG_ 384 AMP_Beep1ModeState 4;
BA_ "GenSigStartValue" SG_ 384 AMP_Beep1ModeState 3;
BA_ "NmNetworkRequest" SG_ 384 AMP_Beep1ModeState 1;
BA_ "TimeoutValue" SG_ 384 AMP_Beep1ModeState "0x3";
BA_ "GenSigSendType" SG_ 384 AMP_Beep2ModeState 4;
BA_ "GenSigStartValue" SG_ 384 AMP_Beep2ModeState 3;
BA_ "NmNetworkRequest" SG_ 384 AMP_Beep2ModeState 1;
BA_ "TimeoutValue" SG_ 384 AMP_Beep2ModeState "0x3";
BA_ "GenSigSendType" SG_ 384 AMP_DistrInfoState 4;
BA_ "GenSigStartValue" SG_ 384 AMP_DistrInfoState 3;
BA_ "NmNetworkRequest" SG_ 384 AMP_DistrInfoState 1;
BA_ "TimeoutValue" SG_ 384 AMP_DistrInfoState "0x3";
BA_ "GenSigSendType" SG_ 384 AMP_INFORM_TO_IPM 4;
BA_ "GenSigStartValue" SG_ 384 AMP_INFORM_TO_IPM 3;
BA_ "NmNetworkRequest" SG_ 384 AMP_INFORM_TO_IPM 1;
BA_ "TimeoutValue" SG_ 384 AMP_INFORM_TO_IPM "0x3";
BA_ "GenSigSendType" SG_ 384 AMP_SignalDoctorState 3;
BA_ "GenSigStartValue" SG_ 384 AMP_SignalDoctorState 3;
BA_ "GenSigSendType" SG_ 384 AMP_AutoVolumeState 3;
BA_ "GenSigStartValue" SG_ 384 AMP_AutoVolumeState 3;
BA_ "GenSigStartValue" SG_ 1408 AMP_SupportMute 3;
BA_ "TimeoutValue" SG_ 1408 AMP_SupportMute "0x3";
BA_ "GenSigStartValue" SG_ 1408 AMP_SupportHFMode 3;
BA_ "TimeoutValue" SG_ 1408 AMP_SupportHFMode "0x3";
BA_ "GenSigStartValue" SG_ 1408 AMP_SupportCfgBeep1 3;
BA_ "TimeoutValue" SG_ 1408 AMP_SupportCfgBeep1 "0x3";
BA_ "GenSigStartValue" SG_ 1408 AMP_SupportCfgBeep2 3;
BA_ "TimeoutValue" SG_ 1408 AMP_SupportCfgBeep2 "0x3";
BA_ "GenSigStartValue" SG_ 1408 AMP_SupportSpeedAdjust 3;
BA_ "TimeoutValue" SG_ 1408 AMP_SupportSpeedAdjust "0x3";
BA_ "GenSigStartValue" SG_ 1408 AMP_SupportSurroundMode 3;
BA_ "TimeoutValue" SG_ 1408 AMP_SupportSurroundMode "0x3";
BA_ "GenSigStartValue" SG_ 1408 AMP_SupportNaviMode 3;
BA_ "TimeoutValue" SG_ 1408 AMP_SupportNaviMode "0x3";
BA_ "GenSigStartValue" SG_ 1408 AMP_SupportMTSMode 3;
BA_ "TimeoutValue" SG_ 1408 AMP_SupportMTSMode "0x3";
BA_ "GenSigStartValue" SG_ 1408 AMP_SupportTopState 3;
BA_ "TimeoutValue" SG_ 1408 AMP_SupportTopState "0x3";
BA_ "GenSigStartValue" SG_ 1408 AMP_SupportBothLHDandRHD 3;
BA_ "TimeoutValue" SG_ 1408 AMP_SupportBothLHDandRHD "0x3";
BA_ "GenSigStartValue" SG_ 1408 AMP_SupportEQState 3;
BA_ "TimeoutValue" SG_ 1408 AMP_SupportEQState "0x3";
BA_ "GenSigStartValue" SG_ 1408 AMP_SupportVehicleID 3;
BA_ "TimeoutValue" SG_ 1408 AMP_SupportVehicleID "0x3";
BA_ "GenSigStartValue" SG_ 1408 AMP_SupportAudioSource 3;
BA_ "TimeoutValue" SG_ 1408 AMP_SupportAudioSource "0x3";
BA_ "GenSigStartValue" SG_ 1408 AMP_SupportSPDIFModeState 3;
BA_ "TimeoutValue" SG_ 1408 AMP_SupportSPDIFModeState "0x3";
BA_ "GenSigStartValue" SG_ 1408 AMP_SupportRearSpMute 3;
BA_ "TimeoutValue" SG_ 1408 AMP_SupportRearSpMute "0x3";
BA_ "GenSigStartValue" SG_ 1408 AMP_SupportVEQMode 3;
BA_ "TimeoutValue" SG_ 1408 AMP_SupportVEQMode "0x3";
BA_ "GenSigStartValue" SG_ 1408 AMP_MakerID 255;
BA_ "TimeoutValue" SG_ 1408 AMP_MakerID "0xFF";
BA_ "GenSigStartValue" SG_ 1408 AMP_SupportASDMode 3;
BA_ "TimeoutValue" SG_ 1408 AMP_SupportASDMode "0x3";
BA_ "GenSigStartValue" SG_ 1408 AMP_SupportBeatsMode 3;
BA_ "GenSigStartValue" SG_ 1408 AMP_SupportVIPMode 3;
BA_ "GenSigStartValue" SG_ 1408 AMP_SupportQLS 3;
BA_ "GenSigStartValue" SG_ 1408 AMP_SupportSignalDoctor 3;
BA_ "GenSigStartValue" SG_ 1408 AMP_SupportAutoVolume 3;
BA_ "GenSigStartValue" SG_ 1408 AMP_SupportPESSMode 3;
BA_ "GenSigSendType" SG_ 371 HU_AliveStatus 4;
BA_ "GenSigStartValue" SG_ 371 HU_AliveStatus 3;
BA_ "NmNetworkRequest" SG_ 371 HU_AliveStatus 1;
BA_ "TimeoutValue" SG_ 371 HU_AliveStatus "0x00";
BA_ "Validity" SG_ 371 HU_AliveStatus 0;
BA_ "GenSigSendType" SG_ 371 HU_DeviceType 4;
BA_ "GenSigStartValue" SG_ 371 HU_DeviceType 15;
BA_ "NmNetworkRequest" SG_ 371 HU_DeviceType 1;
BA_ "TimeoutValue" SG_ 371 HU_DeviceType "invalid";
BA_ "Validity" SG_ 371 HU_DeviceType 0;
BA_ "GenSigSendType" SG_ 371 HU_DistanceUnit 4;
BA_ "GenSigStartValue" SG_ 371 HU_DistanceUnit 3;
BA_ "NmNetworkRequest" SG_ 371 HU_DistanceUnit 1;
BA_ "TimeoutValue" SG_ 371 HU_DistanceUnit "Old";
BA_ "GenSigSendType" SG_ 371 HU_AudAllocStatus 4;
BA_ "GenSigStartValue" SG_ 371 HU_AudAllocStatus 3;
BA_ "NmNetworkRequest" SG_ 371 HU_AudAllocStatus 1;
BA_ "TimeoutValue" SG_ 371 HU_AudAllocStatus "Old";
BA_ "GenSigSendType" SG_ 371 HU_PowerStatus 4;
BA_ "GenSigStartValue" SG_ 371 HU_PowerStatus 7;
BA_ "NmNetworkRequest" SG_ 371 HU_PowerStatus 1;
BA_ "TimeoutValue" SG_ 371 HU_PowerStatus "invalid";
BA_ "GenSigSendType" SG_ 371 HU_BTCallStatus 4;
BA_ "GenSigStartValue" SG_ 371 HU_BTCallStatus 7;
BA_ "NmNetworkRequest" SG_ 371 HU_BTCallStatus 1;
BA_ "TimeoutValue" SG_ 371 HU_BTCallStatus "0x00";
BA_ "GenSigSendType" SG_ 371 HU_VoiceRecStatus 4;
BA_ "GenSigStartValue" SG_ 371 HU_VoiceRecStatus 3;
BA_ "NmNetworkRequest" SG_ 371 HU_VoiceRecStatus 1;
BA_ "TimeoutValue" SG_ 371 HU_VoiceRecStatus "Old";
BA_ "GenSigSendType" SG_ 371 HU_LangStatus 4;
BA_ "GenSigStartValue" SG_ 371 HU_LangStatus 7;
BA_ "NmNetworkRequest" SG_ 371 HU_LangStatus 1;
BA_ "TimeoutValue" SG_ 371 HU_LangStatus "Old";
BA_ "GenSigSendType" SG_ 369 HU_VehiclePwr 4;
BA_ "NmNetworkRequest" SG_ 369 HU_VehiclePwr 1;
BA_ "NmNetworkRequestHoldingTime" SG_ 369 HU_VehiclePwr 5;
BA_ "TimeoutValue" SG_ 369 HU_VehiclePwr "0x0";
BA_ "Validity" SG_ 369 HU_VehiclePwr 0;
BA_ "TimeoutValue" SG_ 1392 HU_GPS_Signal "invalid";
BA_ "GenSigSendType" SG_ 112 AMP_Beep1VolumeStep 4;
BA_ "GenSigStartValue" SG_ 112 AMP_Beep1VolumeStep 255;
BA_ "NmNetworkRequest" SG_ 112 AMP_Beep1VolumeStep 1;
BA_ "GenSigSendType" SG_ 112 AMP_Beep1Frequency 4;
BA_ "GenSigStartValue" SG_ 112 AMP_Beep1Frequency 65535;
BA_ "NmNetworkRequest" SG_ 112 AMP_Beep1Frequency 1;
BA_ "GenSigSendType" SG_ 112 AMP_Beep1Ch_OutputMask 4;
BA_ "GenSigStartValue" SG_ 112 AMP_Beep1Ch_OutputMask 65535;
BA_ "NmNetworkRequest" SG_ 112 AMP_Beep1Ch_OutputMask 1;
BA_ "GenSigSendType" SG_ 112 AMP_Beep1DurationOn 4;
BA_ "GenSigStartValue" SG_ 112 AMP_Beep1DurationOn 255;
BA_ "NmNetworkRequest" SG_ 112 AMP_Beep1DurationOn 1;
BA_ "GenSigSendType" SG_ 112 AMP_Beep1DurationOff 4;
BA_ "GenSigStartValue" SG_ 112 AMP_Beep1DurationOff 255;
BA_ "NmNetworkRequest" SG_ 112 AMP_Beep1DurationOff 1;
BA_ "GenSigSendType" SG_ 112 AMP_Beep1NumberOfCycles 4;
BA_ "GenSigStartValue" SG_ 112 AMP_Beep1NumberOfCycles 255;
BA_ "NmNetworkRequest" SG_ 112 AMP_Beep1NumberOfCycles 1;
BA_ "GenSigStartValue" SG_ 1390 C_VehicleSpeed 255;
BA_ "Gatewaysignal" SG_ 1390 C_VehicleSpeed 4;
BA_ "SignalCategory" SG_ 1390 C_VehicleSpeed 13;
BA_ "TimeoutValue" SG_ 1390 C_VehicleSpeed "Old Value";
BA_ "Validity" SG_ 1390 C_VehicleSpeed 2;
BA_ "GenSigStartValue" SG_ 1390 C_Odometer 16777215;
BA_ "Gatewaysignal" SG_ 1390 C_Odometer 4;
BA_ "SignalCategory" SG_ 1390 C_Odometer 13;
BA_ "TimeoutValue" SG_ 1390 C_Odometer "Old Value";
BA_ "Validity" SG_ 1390 C_Odometer 2;
BA_ "GenSigSendType" SG_ 363 C_DRVUnlockState 4;
BA_ "GenSigStartValue" SG_ 363 C_DRVUnlockState 3;
BA_ "NmNetworkRequest" SG_ 363 C_DRVUnlockState 1;
BA_ "Validity" SG_ 363 C_DRVUnlockState 0;
BA_ "GenSigSendType" SG_ 363 C_ASTUnlockState 4;
BA_ "GenSigStartValue" SG_ 363 C_ASTUnlockState 3;
BA_ "NmNetworkRequest" SG_ 363 C_ASTUnlockState 1;
BA_ "Validity" SG_ 363 C_ASTUnlockState 0;
BA_ "GenSigSendType" SG_ 363 C_RLUnlockstate 4;
BA_ "GenSigStartValue" SG_ 363 C_RLUnlockstate 3;
BA_ "NmNetworkRequest" SG_ 363 C_RLUnlockstate 1;
BA_ "Validity" SG_ 363 C_RLUnlockstate 0;
BA_ "GenSigSendType" SG_ 363 C_RRUnlockState 4;
BA_ "GenSigStartValue" SG_ 363 C_RRUnlockState 3;
BA_ "NmNetworkRequest" SG_ 363 C_RRUnlockState 1;
BA_ "Validity" SG_ 363 C_RRUnlockState 0;
BA_ "GenSigSendType" SG_ 363 C_VehicleInfoTMU 4;
BA_ "NmNetworkRequest" SG_ 363 C_VehicleInfoTMU 1;
BA_ "Validity" SG_ 363 C_VehicleInfoTMU 0;
BA_ "GenSigSendType" SG_ 363 C_Engine_Status 4;
BA_ "GenSigStartValue" SG_ 363 C_Engine_Status 3;
BA_ "NmNetworkRequest" SG_ 363 C_Engine_Status 1;
BA_ "Validity" SG_ 363 C_Engine_Status 0;
BA_ "GenSigSendType" SG_ 363 C_TMULockFeedBack 4;
BA_ "NmNetworkRequest" SG_ 363 C_TMULockFeedBack 1;
BA_ "Validity" SG_ 363 C_TMULockFeedBack 0;
BA_ "GenSigSendType" SG_ 362 C_AV_Tail 4;
BA_ "GenSigStartValue" SG_ 362 C_AV_Tail 3;
BA_ "Gatewaysignal" SG_ 362 C_AV_Tail 4;
BA_ "NmNetworkRequest" SG_ 362 C_AV_Tail 1;
BA_ "TimeoutValue" SG_ 362 C_AV_Tail "0x3";
BA_ "GenSigSendType" SG_ 362 C_ParkingBrakeSW 4;
BA_ "GenSigStartValue" SG_ 362 C_ParkingBrakeSW 3;
BA_ "Gatewaysignal" SG_ 362 C_ParkingBrakeSW 2;
BA_ "NmNetworkRequest" SG_ 362 C_ParkingBrakeSW 1;
BA_ "TimeoutValue" SG_ 362 C_ParkingBrakeSW "0x3";
BA_ "GenSigSendType" SG_ 362 C_RKECMD 4;
BA_ "GenSigStartValue" SG_ 362 C_RKECMD 15;
BA_ "Gatewaysignal" SG_ 362 C_RKECMD 2;
BA_ "NmNetworkRequest" SG_ 362 C_RKECMD 1;
BA_ "NmNetworkRequestHoldingTime" SG_ 362 C_RKECMD 5;
BA_ "TimeoutValue" SG_ 362 C_RKECMD "0xF";
BA_ "Validity" SG_ 362 C_RKECMD 0;
BA_ "GenSigSendType" SG_ 362 C_BAState 4;
BA_ "GenSigStartValue" SG_ 362 C_BAState 3;
BA_ "Gatewaysignal" SG_ 362 C_BAState 4;
BA_ "NmNetworkRequest" SG_ 362 C_BAState 1;
BA_ "TimeoutValue" SG_ 362 C_BAState "0x3";
BA_ "Validity" SG_ 362 C_BAState 0;
BA_ "GenSigSendType" SG_ 362 C_IGNSW 4;
BA_ "GenSigStartValue" SG_ 362 C_IGNSW 7;
BA_ "Gatewaysignal" SG_ 362 C_IGNSW 2;
BA_ "NmNetworkRequest" SG_ 362 C_IGNSW 1;
BA_ "NmNetworkRequestHoldingTime" SG_ 362 C_IGNSW 5;
BA_ "TimeoutValue" SG_ 362 C_IGNSW "0x0";
BA_ "Validity" SG_ 362 C_IGNSW 0;
BA_ "GenSigSendType" SG_ 362 C_CountryCfg 4;
BA_ "GenSigStartValue" SG_ 362 C_CountryCfg 7;
BA_ "Gatewaysignal" SG_ 362 C_CountryCfg 2;
BA_ "NmNetworkRequest" SG_ 362 C_CountryCfg 1;
BA_ "NmNetworkRequestHoldingTime" SG_ 362 C_CountryCfg 5;
BA_ "TimeoutValue" SG_ 362 C_CountryCfg "0x7";
BA_ "Validity" SG_ 362 C_CountryCfg 0;
BA_ "GenSigSendType" SG_ 362 C_AltL 3;
BA_ "Validity" SG_ 362 C_AltL 2;
BA_ "GenSigSendType" SG_ 362 C_TailLampActivity 3;
BA_ "GenSigStartValue" SG_ 362 C_TailLampActivity 3;
BA_ "Gatewaysignal" SG_ 362 C_TailLampActivity 2;
BA_ "SignalCategory" SG_ 362 C_TailLampActivity 13;
BA_ "TimeoutValue" SG_ 362 C_TailLampActivity "Old Value";
BA_ "GenSigSendType" SG_ 362 RearSW_RSELockOnOff 3;
BA_ "GenSigStartValue" SG_ 362 RearSW_RSELockOnOff 3;
BA_ "Gatewaysignal" SG_ 362 RearSW_RSELockOnOff 2;
BA_ "SignalCategory" SG_ 362 RearSW_RSELockOnOff 13;
BA_ "TimeoutValue" SG_ 362 RearSW_RSELockOnOff "Old Value";
BA_ "GenSigSendType" SG_ 362 C_TMULockFeedBack 4;
BA_ "NmNetworkRequest" SG_ 362 C_TMULockFeedBack 1;
BA_ "TimeoutValue" SG_ 362 C_TMULockFeedBack "Old";
BA_ "Validity" SG_ 362 C_TMULockFeedBack 0;
BA_ "GenSigSendType" SG_ 362 C_SMKTeleCrankingState 3;
BA_ "GenSigStartValue" SG_ 362 C_SMKTeleCrankingState 3;
BA_ "Gatewaysignal" SG_ 362 C_SMKTeleCrankingState 2;
BA_ "SignalCategory" SG_ 362 C_SMKTeleCrankingState 13;
BA_ "TimeoutValue" SG_ 362 C_SMKTeleCrankingState "Old Value";
BA_ "Validity" SG_ 362 C_SMKTeleCrankingState 0;
BA_ "GenSigSendType" SG_ 362 C_SMKTeleCrankingFailRes 3;
BA_ "GenSigStartValue" SG_ 362 C_SMKTeleCrankingFailRes 3;
BA_ "Gatewaysignal" SG_ 362 C_SMKTeleCrankingFailRes 2;
BA_ "SignalCategory" SG_ 362 C_SMKTeleCrankingFailRes 13;
BA_ "TimeoutValue" SG_ 362 C_SMKTeleCrankingFailRes "Old Value";
BA_ "Validity" SG_ 362 C_SMKTeleCrankingFailRes 0;
BA_ "GenSigSendType" SG_ 362 C_RKECMD_GEN2 4;
BA_ "GenSigStartValue" SG_ 362 C_RKECMD_GEN2 7;
BA_ "Gatewaysignal" SG_ 362 C_RKECMD_GEN2 4;
BA_ "NmNetworkRequest" SG_ 362 C_RKECMD_GEN2 1;
BA_ "TimeoutValue" SG_ 362 C_RKECMD_GEN2 "0x7";
BA_ "Validity" SG_ 362 C_RKECMD_GEN2 0;
BA_ "GenSigSendType" SG_ 362 C_Acu_CshAct 4;
BA_ "Gatewaysignal" SG_ 362 C_Acu_CshAct 2;
BA_ "NmNetworkRequest" SG_ 362 C_Acu_CshAct 1;
BA_ "NmNetworkRequestHoldingTime" SG_ 362 C_Acu_CshAct 5;
BA_ "SignalCategory" SG_ 362 C_Acu_CshAct 13;
BA_ "TimeoutValue" SG_ 362 C_Acu_CshAct "Old Value";
BA_ "Validity" SG_ 362 C_Acu_CshAct 2;
BA_ "GenSigSendType" SG_ 362 C_IntTailAct 4;
BA_ "GenSigStartValue" SG_ 362 C_IntTailAct 3;
BA_ "Gatewaysignal" SG_ 362 C_IntTailAct 2;
BA_ "NmNetworkRequest" SG_ 362 C_IntTailAct 1;
BA_ "TimeoutValue" SG_ 362 C_IntTailAct "Old Value";
BA_ "GenSigSendType" SG_ 362 C_PassiveAccessUnlock 4;
BA_ "GenSigStartValue" SG_ 362 C_PassiveAccessUnlock 7;
BA_ "Gatewaysignal" SG_ 362 C_PassiveAccessUnlock 4;
BA_ "NmNetworkRequest" SG_ 362 C_PassiveAccessUnlock 1;
BA_ "TimeoutValue" SG_ 362 C_PassiveAccessUnlock "0x7";
BA_ "Validity" SG_ 362 C_PassiveAccessUnlock 0;
BA_ "GenSigSendType" SG_ 362 Lca_IndLeft 4;
BA_ "GenSigStartValue" SG_ 362 Lca_IndLeft 3;
BA_ "Gatewaysignal" SG_ 362 Lca_IndLeft 4;
BA_ "NmNetworkRequest" SG_ 362 Lca_IndLeft 1;
BA_ "TimeoutValue" SG_ 362 Lca_IndLeft "0x3";
BA_ "Validity" SG_ 362 Lca_IndLeft 2;
BA_ "GenSigSendType" SG_ 362 FL_SndWarn 4;
BA_ "GenSigStartValue" SG_ 362 FL_SndWarn 3;
BA_ "Gatewaysignal" SG_ 362 FL_SndWarn 4;
BA_ "NmNetworkRequest" SG_ 362 FL_SndWarn 1;
BA_ "TimeoutValue" SG_ 362 FL_SndWarn "0x3";
BA_ "Validity" SG_ 362 FL_SndWarn 2;
BA_ "GenSigSendType" SG_ 362 FR_SndWarn 4;
BA_ "GenSigStartValue" SG_ 362 FR_SndWarn 3;
BA_ "Gatewaysignal" SG_ 362 FR_SndWarn 4;
BA_ "NmNetworkRequest" SG_ 362 FR_SndWarn 1;
BA_ "TimeoutValue" SG_ 362 FR_SndWarn "0x3";
BA_ "Validity" SG_ 362 FR_SndWarn 2;
BA_ "GenSigSendType" SG_ 362 Lca_IndRight 4;
BA_ "GenSigStartValue" SG_ 362 Lca_IndRight 3;
BA_ "Gatewaysignal" SG_ 362 Lca_IndRight 4;
BA_ "NmNetworkRequest" SG_ 362 Lca_IndRight 1;
BA_ "TimeoutValue" SG_ 362 Lca_IndRight "0x3";
BA_ "Validity" SG_ 362 Lca_IndRight 2;
BA_ "GenSigSendType" SG_ 362 RCTA_IndLeft 4;
BA_ "GenSigStartValue" SG_ 362 RCTA_IndLeft 3;
BA_ "Gatewaysignal" SG_ 362 RCTA_IndLeft 4;
BA_ "NmNetworkRequest" SG_ 362 RCTA_IndLeft 1;
BA_ "TimeoutValue" SG_ 362 RCTA_IndLeft "0x3";
BA_ "Validity" SG_ 362 RCTA_IndLeft 2;
BA_ "GenSigSendType" SG_ 362 RL_SndWarn 4;
BA_ "GenSigStartValue" SG_ 362 RL_SndWarn 3;
BA_ "Gatewaysignal" SG_ 362 RL_SndWarn 4;
BA_ "NmNetworkRequest" SG_ 362 RL_SndWarn 1;
BA_ "TimeoutValue" SG_ 362 RL_SndWarn "0x3";
BA_ "Validity" SG_ 362 RL_SndWarn 2;
BA_ "GenSigSendType" SG_ 362 RR_SndWarn 4;
BA_ "GenSigStartValue" SG_ 362 RR_SndWarn 3;
BA_ "Gatewaysignal" SG_ 362 RR_SndWarn 4;
BA_ "NmNetworkRequest" SG_ 362 RR_SndWarn 1;
BA_ "TimeoutValue" SG_ 362 RR_SndWarn "0x3";
BA_ "Validity" SG_ 362 RR_SndWarn 2;
BA_ "GenSigSendType" SG_ 362 RCTA_IndRight 4;
BA_ "GenSigStartValue" SG_ 362 RCTA_IndRight 3;
BA_ "Gatewaysignal" SG_ 362 RCTA_IndRight 4;
BA_ "NmNetworkRequest" SG_ 362 RCTA_IndRight 1;
BA_ "TimeoutValue" SG_ 362 RCTA_IndRight "0x3";
BA_ "Validity" SG_ 362 RCTA_IndRight 2;
BA_ "GenSigSendType" SG_ 361 C_Inhibit_State 4;
BA_ "GenSigStartValue" SG_ 361 C_Inhibit_State 15;
BA_ "NmNetworkRequest" SG_ 361 C_Inhibit_State 1;
BA_ "TimeoutValue" SG_ 361 C_Inhibit_State "OldValue";
BA_ "Validity" SG_ 361 C_Inhibit_State 2;
BA_ "GenSigSendType" SG_ 361 C_P_BrakeStatus 4;
BA_ "GenSigStartValue" SG_ 361 C_P_BrakeStatus 3;
BA_ "NmNetworkRequest" SG_ 361 C_P_BrakeStatus 1;
BA_ "TimeoutValue" SG_ 361 C_P_BrakeStatus "OldValue";
BA_ "Validity" SG_ 361 C_P_BrakeStatus 2;
BA_ "GenSigSendType" SG_ 361 C_Clu_AltLStatus 4;
BA_ "GenSigStartValue" SG_ 361 C_Clu_AltLStatus 3;
BA_ "NmNetworkRequest" SG_ 361 C_Clu_AltLStatus 1;
BA_ "TimeoutValue" SG_ 361 C_Clu_AltLStatus "OldValue";
BA_ "Validity" SG_ 361 C_Clu_AltLStatus 2;
BA_ "GenSigSendType" SG_ 359 Spas_BEEP_Alarm 4;
BA_ "GenSigStartValue" SG_ 359 Spas_BEEP_Alarm 15;
BA_ "NmNetworkRequest" SG_ 359 Spas_BEEP_Alarm 1;
BA_ "TimeoutValue" SG_ 359 Spas_BEEP_Alarm "0xF";
BA_ "Validity" SG_ 359 Spas_BEEP_Alarm 2;
BA_ "GenSigSendType" SG_ 359 Spas_Audio_VolumeDown 4;
BA_ "GenSigStartValue" SG_ 359 Spas_Audio_VolumeDown 3;
BA_ "NmNetworkRequest" SG_ 359 Spas_Audio_VolumeDown 1;
BA_ "TimeoutValue" SG_ 359 Spas_Audio_VolumeDown "0x3";
BA_ "Validity" SG_ 359 Spas_Audio_VolumeDown 2;
BA_ "GenSigSendType" SG_ 359 Spas_Spkr_Flh_Alarm 4;
BA_ "Gatewaysignal" SG_ 359 Spas_Spkr_Flh_Alarm 4;
BA_ "NmNetworkRequest" SG_ 359 Spas_Spkr_Flh_Alarm 1;
BA_ "TimeoutValue" SG_ 359 Spas_Spkr_Flh_Alarm "0x0";
BA_ "Validity" SG_ 359 Spas_Spkr_Flh_Alarm 2;
BA_ "GenSigSendType" SG_ 359 Spas_Spkr_Fcnt_Alarm 4;
BA_ "Gatewaysignal" SG_ 359 Spas_Spkr_Fcnt_Alarm 4;
BA_ "NmNetworkRequest" SG_ 359 Spas_Spkr_Fcnt_Alarm 1;
BA_ "TimeoutValue" SG_ 359 Spas_Spkr_Fcnt_Alarm "0x0";
BA_ "Validity" SG_ 359 Spas_Spkr_Fcnt_Alarm 2;
BA_ "GenSigSendType" SG_ 359 Spas_Spkr_Frh_Alarm 4;
BA_ "Gatewaysignal" SG_ 359 Spas_Spkr_Frh_Alarm 4;
BA_ "NmNetworkRequest" SG_ 359 Spas_Spkr_Frh_Alarm 1;
BA_ "TimeoutValue" SG_ 359 Spas_Spkr_Frh_Alarm "0x0";
BA_ "Validity" SG_ 359 Spas_Spkr_Frh_Alarm 2;
BA_ "GenSigSendType" SG_ 359 Spas_Spkr_Rlh_Alarm 4;
BA_ "Gatewaysignal" SG_ 359 Spas_Spkr_Rlh_Alarm 4;
BA_ "NmNetworkRequest" SG_ 359 Spas_Spkr_Rlh_Alarm 1;
BA_ "TimeoutValue" SG_ 359 Spas_Spkr_Rlh_Alarm "0x0";
BA_ "Validity" SG_ 359 Spas_Spkr_Rlh_Alarm 2;
BA_ "GenSigSendType" SG_ 359 Spas_Spkr_Rcnt_Alarm 4;
BA_ "Gatewaysignal" SG_ 359 Spas_Spkr_Rcnt_Alarm 4;
BA_ "NmNetworkRequest" SG_ 359 Spas_Spkr_Rcnt_Alarm 1;
BA_ "TimeoutValue" SG_ 359 Spas_Spkr_Rcnt_Alarm "0x0";
BA_ "Validity" SG_ 359 Spas_Spkr_Rcnt_Alarm 2;
BA_ "GenSigSendType" SG_ 359 Spas_Spkr_Rrh_Alarm 4;
BA_ "Gatewaysignal" SG_ 359 Spas_Spkr_Rrh_Alarm 4;
BA_ "NmNetworkRequest" SG_ 359 Spas_Spkr_Rrh_Alarm 1;
BA_ "TimeoutValue" SG_ 359 Spas_Spkr_Rrh_Alarm "0x0";
BA_ "Validity" SG_ 359 Spas_Spkr_Rrh_Alarm 2;
BA_ "GenSigSendType" SG_ 359 Lkas_SysStatus 4;
BA_ "GenSigStartValue" SG_ 359 Lkas_SysStatus 15;
BA_ "Gatewaysignal" SG_ 359 Lkas_SysStatus 4;
BA_ "NmNetworkRequest" SG_ 359 Lkas_SysStatus 1;
BA_ "TimeoutValue" SG_ 359 Lkas_SysStatus "0xF";
BA_ "Validity" SG_ 359 Lkas_SysStatus 2;
BA_ "GenSigSendType" SG_ 359 Lkas_LH_Warning 4;
BA_ "GenSigStartValue" SG_ 359 Lkas_LH_Warning 3;
BA_ "Gatewaysignal" SG_ 359 Lkas_LH_Warning 4;
BA_ "NmNetworkRequest" SG_ 359 Lkas_LH_Warning 1;
BA_ "TimeoutValue" SG_ 359 Lkas_LH_Warning "0x3";
BA_ "Validity" SG_ 359 Lkas_LH_Warning 2;
BA_ "GenSigSendType" SG_ 359 Lkas_RH_Warning 4;
BA_ "GenSigStartValue" SG_ 359 Lkas_RH_Warning 3;
BA_ "Gatewaysignal" SG_ 359 Lkas_RH_Warning 4;
BA_ "NmNetworkRequest" SG_ 359 Lkas_RH_Warning 1;
BA_ "TimeoutValue" SG_ 359 Lkas_RH_Warning "0x3";
BA_ "Validity" SG_ 359 Lkas_RH_Warning 2;
BA_ "GenSigSendType" SG_ 359 Spas_Spkr_Level 4;
BA_ "Gatewaysignal" SG_ 359 Spas_Spkr_Level 2;
BA_ "NmNetworkRequest" SG_ 359 Spas_Spkr_Level 1;
BA_ "TimeoutValue" SG_ 359 Spas_Spkr_Level "0x0";
BA_ "Validity" SG_ 359 Spas_Spkr_Level 2;
BA_ "GenSigSendType" SG_ 359 Lkas_Audio_VolumeDown 4;
BA_ "GenSigStartValue" SG_ 359 Lkas_Audio_VolumeDown 3;
BA_ "Gatewaysignal" SG_ 359 Lkas_Audio_VolumeDown 4;
BA_ "NmNetworkRequest" SG_ 359 Lkas_Audio_VolumeDown 1;
BA_ "TimeoutValue" SG_ 359 Lkas_Audio_VolumeDown "0x3";
BA_ "GenSigSendType" SG_ 359 Audio_VolumeDown 4;
BA_ "GenSigStartValue" SG_ 359 Audio_VolumeDown 3;
BA_ "Gatewaysignal" SG_ 359 Audio_VolumeDown 4;
BA_ "NmNetworkRequest" SG_ 359 Audio_VolumeDown 1;
BA_ "TimeoutValue" SG_ 359 Audio_VolumeDown "0x3";
BA_ "Validity" SG_ 359 Audio_VolumeDown 2;
BA_ "GenSigSendType" SG_ 359 Pas_BEEP_Alarm 4;
BA_ "GenSigStartValue" SG_ 359 Pas_BEEP_Alarm 15;
BA_ "NmNetworkRequest" SG_ 359 Pas_BEEP_Alarm 1;
BA_ "TimeoutValue" SG_ 359 Pas_BEEP_Alarm "0xF";
BA_ "Validity" SG_ 359 Pas_BEEP_Alarm 2;
BA_ "GenSigSendType" SG_ 359 Pas_Audio_VolumeDown 4;
BA_ "GenSigStartValue" SG_ 359 Pas_Audio_VolumeDown 3;
BA_ "Gatewaysignal" SG_ 359 Pas_Audio_VolumeDown 4;
BA_ "NmNetworkRequest" SG_ 359 Pas_Audio_VolumeDown 1;
BA_ "TimeoutValue" SG_ 359 Pas_Audio_VolumeDown "0x3";
BA_ "Validity" SG_ 359 Pas_Audio_VolumeDown 2;
BA_ "GenSigSendType" SG_ 359 Pas_Spkr_Level 4;
BA_ "Gatewaysignal" SG_ 359 Pas_Spkr_Level 2;
BA_ "NmNetworkRequest" SG_ 359 Pas_Spkr_Level 1;
BA_ "TimeoutValue" SG_ 359 Pas_Spkr_Level "0x0";
BA_ "Validity" SG_ 359 Pas_Spkr_Level 2;
BA_ "GenSigSendType" SG_ 359 Pas_Spkr_Flh_Alarm 4;
BA_ "Gatewaysignal" SG_ 359 Pas_Spkr_Flh_Alarm 2;
BA_ "NmNetworkRequest" SG_ 359 Pas_Spkr_Flh_Alarm 1;
BA_ "TimeoutValue" SG_ 359 Pas_Spkr_Flh_Alarm "0x0";
BA_ "Validity" SG_ 359 Pas_Spkr_Flh_Alarm 2;
BA_ "GenSigSendType" SG_ 359 Pas_Spkr_Fcnt_Alarm 4;
BA_ "Gatewaysignal" SG_ 359 Pas_Spkr_Fcnt_Alarm 2;
BA_ "NmNetworkRequest" SG_ 359 Pas_Spkr_Fcnt_Alarm 1;
BA_ "TimeoutValue" SG_ 359 Pas_Spkr_Fcnt_Alarm "0x0";
BA_ "Validity" SG_ 359 Pas_Spkr_Fcnt_Alarm 2;
BA_ "GenSigSendType" SG_ 359 Pas_Spkr_Frh_Alarm 4;
BA_ "Gatewaysignal" SG_ 359 Pas_Spkr_Frh_Alarm 2;
BA_ "NmNetworkRequest" SG_ 359 Pas_Spkr_Frh_Alarm 1;
BA_ "TimeoutValue" SG_ 359 Pas_Spkr_Frh_Alarm "0x0";
BA_ "Validity" SG_ 359 Pas_Spkr_Frh_Alarm 2;
BA_ "GenSigSendType" SG_ 359 Pas_Spkr_Rlh_Alarm 4;
BA_ "Gatewaysignal" SG_ 359 Pas_Spkr_Rlh_Alarm 2;
BA_ "NmNetworkRequest" SG_ 359 Pas_Spkr_Rlh_Alarm 1;
BA_ "TimeoutValue" SG_ 359 Pas_Spkr_Rlh_Alarm "0x0";
BA_ "Validity" SG_ 359 Pas_Spkr_Rlh_Alarm 2;
BA_ "GenSigSendType" SG_ 359 Pas_Spkr_Rcnt_Alarm 4;
BA_ "Gatewaysignal" SG_ 359 Pas_Spkr_Rcnt_Alarm 2;
BA_ "NmNetworkRequest" SG_ 359 Pas_Spkr_Rcnt_Alarm 1;
BA_ "TimeoutValue" SG_ 359 Pas_Spkr_Rcnt_Alarm "0x0";
BA_ "Validity" SG_ 359 Pas_Spkr_Rcnt_Alarm 2;
BA_ "GenSigSendType" SG_ 359 Pas_Spkr_Rrh_Alarm 4;
BA_ "Gatewaysignal" SG_ 359 Pas_Spkr_Rrh_Alarm 2;
BA_ "NmNetworkRequest" SG_ 359 Pas_Spkr_Rrh_Alarm 1;
BA_ "TimeoutValue" SG_ 359 Pas_Spkr_Rrh_Alarm "0x0";
BA_ "Validity" SG_ 359 Pas_Spkr_Rrh_Alarm 2;
BA_ "GenSigStartValue" SG_ 1376 HU_GPS_Signal2 255;
BA_ "NmNetworkRequest" SG_ 1376 HU_GPS_Signal2 1;
BA_ "TimeoutValue" SG_ 1376 HU_GPS_Signal2 "Invalid";
BA_ "GenSigStartValue" SG_ 1376 HU_GPS_Signal3 3;
BA_ "NmNetworkRequest" SG_ 1376 HU_GPS_Signal3 1;
BA_ "TimeoutValue" SG_ 1376 HU_GPS_Signal3 "0x03";
BA_ "GenSigStartValue" SG_ 1376 HU_GPS_Signal4 7;
BA_ "NmNetworkRequest" SG_ 1376 HU_GPS_Signal4 1;
BA_ "TimeoutValue" SG_ 1376 HU_GPS_Signal4 "Invalid";
BA_ "GenSigSendType" SG_ 93 DATC_SWVerMajor 4;
BA_ "GenSigStartValue" SG_ 93 DATC_SWVerMajor 255;
BA_ "NmNetworkRequest" SG_ 93 DATC_SWVerMajor 1;
BA_ "SignalCategory" SG_ 93 DATC_SWVerMajor 13;
BA_ "GenSigSendType" SG_ 93 DATC_SWVerMinor 4;
BA_ "GenSigStartValue" SG_ 93 DATC_SWVerMinor 255;
BA_ "NmNetworkRequest" SG_ 93 DATC_SWVerMinor 1;
BA_ "SignalCategory" SG_ 93 DATC_SWVerMinor 13;
BA_ "GenSigSendType" SG_ 93 DATC_CANVerMajor 4;
BA_ "GenSigStartValue" SG_ 93 DATC_CANVerMajor 255;
BA_ "NmNetworkRequest" SG_ 93 DATC_CANVerMajor 1;
BA_ "SignalCategory" SG_ 93 DATC_CANVerMajor 13;
BA_ "GenSigSendType" SG_ 93 DATC_CANVerMinor 4;
BA_ "GenSigStartValue" SG_ 93 DATC_CANVerMinor 255;
BA_ "NmNetworkRequest" SG_ 93 DATC_CANVerMinor 1;
BA_ "SignalCategory" SG_ 93 DATC_CANVerMinor 13;
BA_ "TimeoutValue" SG_ 93 DATC_CANVerMinor "32";
BA_ "GenSigSendType" SG_ 344 C_InhibitP 4;
BA_ "GenSigStartValue" SG_ 344 C_InhibitP 3;
BA_ "Gatewaysignal" SG_ 344 C_InhibitP 4;
BA_ "NmNetworkRequest" SG_ 344 C_InhibitP 1;
BA_ "TimeoutValue" SG_ 344 C_InhibitP "Old Value";
BA_ "Validity" SG_ 344 C_InhibitP 2;
BA_ "GenSigSendType" SG_ 344 C_InhibitR 4;
BA_ "GenSigStartValue" SG_ 344 C_InhibitR 3;
BA_ "Gatewaysignal" SG_ 344 C_InhibitR 4;
BA_ "NmNetworkRequest" SG_ 344 C_InhibitR 1;
BA_ "TimeoutValue" SG_ 344 C_InhibitR "Old Value";
BA_ "Validity" SG_ 344 C_InhibitR 2;
BA_ "GenSigSendType" SG_ 344 C_InhibitN 4;
BA_ "GenSigStartValue" SG_ 344 C_InhibitN 3;
BA_ "Gatewaysignal" SG_ 344 C_InhibitN 4;
BA_ "NmNetworkRequest" SG_ 344 C_InhibitN 1;
BA_ "TimeoutValue" SG_ 344 C_InhibitN "Old Value";
BA_ "Validity" SG_ 344 C_InhibitN 2;
BA_ "GenSigSendType" SG_ 344 C_InhibitD 4;
BA_ "GenSigStartValue" SG_ 344 C_InhibitD 3;
BA_ "Gatewaysignal" SG_ 344 C_InhibitD 4;
BA_ "NmNetworkRequest" SG_ 344 C_InhibitD 1;
BA_ "TimeoutValue" SG_ 344 C_InhibitD "Old Value";
BA_ "Validity" SG_ 344 C_InhibitD 2;
BA_ "GenSigSendType" SG_ 344 C_P_BrakeStatus 4;
BA_ "GenSigStartValue" SG_ 344 C_P_BrakeStatus 3;
BA_ "Gatewaysignal" SG_ 344 C_P_BrakeStatus 4;
BA_ "NmNetworkRequest" SG_ 344 C_P_BrakeStatus 1;
BA_ "TimeoutValue" SG_ 344 C_P_BrakeStatus "Old Value";
BA_ "GenSigSendType" SG_ 344 C_Clu_AltLStatus 4;
BA_ "GenSigStartValue" SG_ 344 C_Clu_AltLStatus 3;
BA_ "Gatewaysignal" SG_ 344 C_Clu_AltLStatus 4;
BA_ "NmNetworkRequest" SG_ 344 C_Clu_AltLStatus 1;
BA_ "TimeoutValue" SG_ 344 C_Clu_AltLStatus "Old Value";
BA_ "Validity" SG_ 344 C_Clu_AltLStatus 2;
BA_ "GenSigSendType" SG_ 344 CF_Clu_LowfuelWarning 4;
BA_ "GenSigStartValue" SG_ 344 CF_Clu_LowfuelWarning 3;
BA_ "Gatewaysignal" SG_ 344 CF_Clu_LowfuelWarning 4;
BA_ "NmNetworkRequest" SG_ 344 CF_Clu_LowfuelWarning 1;
BA_ "TimeoutValue" SG_ 344 CF_Clu_LowfuelWarning "Old Value";
BA_ "GenSigSendType" SG_ 344 C_InhibitRMT 4;
BA_ "GenSigStartValue" SG_ 344 C_InhibitRMT 3;
BA_ "Gatewaysignal" SG_ 344 C_InhibitRMT 2;
BA_ "NmNetworkRequest" SG_ 344 C_InhibitRMT 1;
BA_ "TimeoutValue" SG_ 344 C_InhibitRMT "Old Value";
BA_ "Validity" SG_ 344 C_InhibitRMT 2;
BA_ "GenSigSendType" SG_ 344 CF_SMKRKECmd 3;
BA_ "Validity" SG_ 344 CF_SMKRKECmd 2;
BA_ "GenSigSendType" SG_ 87 NaviValidity 4;
BA_ "GenSigStartValue" SG_ 87 NaviValidity 3;
BA_ "Gatewaysignal" SG_ 87 NaviValidity 3;
BA_ "NmNetworkRequest" SG_ 87 NaviValidity 1;
BA_ "GenSigSendType" SG_ 343 CF_Lkas_TsrSlifOpt 3;
BA_ "GenSigStartValue" SG_ 343 CF_Lkas_TsrSlifOpt 3;
BA_ "Gatewaysignal" SG_ 343 CF_Lkas_TsrSlifOpt 4;
BA_ "TimeoutValue" SG_ 343 CF_Lkas_TsrSlifOpt "Old Value";
BA_ "Validity" SG_ 343 CF_Lkas_TsrSlifOpt 2;
BA_ "GenSigSendType" SG_ 343 CF_Lkas_TsrStatus 3;
BA_ "GenSigStartValue" SG_ 343 CF_Lkas_TsrStatus 3;
BA_ "Gatewaysignal" SG_ 343 CF_Lkas_TsrStatus 4;
BA_ "TimeoutValue" SG_ 343 CF_Lkas_TsrStatus "0x1";
BA_ "Validity" SG_ 343 CF_Lkas_TsrStatus 2;
BA_ "GenSigSendType" SG_ 343 CF_Lkas_TsrAddinfo_Disp 3;
BA_ "GenSigStartValue" SG_ 343 CF_Lkas_TsrAddinfo_Disp 3;
BA_ "Gatewaysignal" SG_ 343 CF_Lkas_TsrAddinfo_Disp 4;
BA_ "TimeoutValue" SG_ 343 CF_Lkas_TsrAddinfo_Disp "0x3";
BA_ "Validity" SG_ 343 CF_Lkas_TsrAddinfo_Disp 2;
BA_ "GenSigSendType" SG_ 343 CF_Lkas_TsrSpeed_Display 3;
BA_ "GenSigStartValue" SG_ 343 CF_Lkas_TsrSpeed_Display 255;
BA_ "Gatewaysignal" SG_ 343 CF_Lkas_TsrSpeed_Display 4;
BA_ "TimeoutValue" SG_ 343 CF_Lkas_TsrSpeed_Display "0xFF";
BA_ "Validity" SG_ 343 CF_Lkas_TsrSpeed_Display 2;
BA_ "GenSigSendType" SG_ 75 AMP_EngOrderC2GainSet 4;
BA_ "GenSigStartValue" SG_ 75 AMP_EngOrderC2GainSet 255;
BA_ "NmNetworkRequest" SG_ 75 AMP_EngOrderC2GainSet 1;
BA_ "GenSigSendType" SG_ 75 AMP_EngOrderC4GainSet 4;
BA_ "GenSigStartValue" SG_ 75 AMP_EngOrderC4GainSet 255;
BA_ "NmNetworkRequest" SG_ 75 AMP_EngOrderC4GainSet 1;
BA_ "GenSigSendType" SG_ 75 AMP_EngOrderC6GainSet 4;
BA_ "GenSigStartValue" SG_ 75 AMP_EngOrderC6GainSet 255;
BA_ "NmNetworkRequest" SG_ 75 AMP_EngOrderC6GainSet 1;
BA_ "GenSigSendType" SG_ 75 AMP_APSBand0GainSet 4;
BA_ "GenSigStartValue" SG_ 75 AMP_APSBand0GainSet 255;
BA_ "NmNetworkRequest" SG_ 75 AMP_APSBand0GainSet 1;
BA_ "GenSigSendType" SG_ 75 AMP_APSBand1GainSet 4;
BA_ "GenSigStartValue" SG_ 75 AMP_APSBand1GainSet 255;
BA_ "NmNetworkRequest" SG_ 75 AMP_APSBand1GainSet 1;
BA_ "GenSigSendType" SG_ 75 AMP_APSBand2GainSet 4;
BA_ "GenSigStartValue" SG_ 75 AMP_APSBand2GainSet 255;
BA_ "NmNetworkRequest" SG_ 75 AMP_APSBand2GainSet 1;
BA_ "GenSigSendType" SG_ 75 AMP_APSBand3GainSet 4;
BA_ "GenSigStartValue" SG_ 75 AMP_APSBand3GainSet 255;
BA_ "NmNetworkRequest" SG_ 75 AMP_APSBand3GainSet 1;
BA_ "GenSigSendType" SG_ 75 AMP_APSBand4GainSet 4;
BA_ "GenSigStartValue" SG_ 75 AMP_APSBand4GainSet 255;
BA_ "NmNetworkRequest" SG_ 75 AMP_APSBand4GainSet 1;
BA_ "GenSigSendType" SG_ 74 AMP_PESSMode 4;
BA_ "GenSigStartValue" SG_ 74 AMP_PESSMode 3;
BA_ "NmNetworkRequest" SG_ 74 AMP_PESSMode 1;
BA_ "GenSigSendType" SG_ 74 AMP_PESSDesignSet 4;
BA_ "GenSigStartValue" SG_ 74 AMP_PESSDesignSet 7;
BA_ "NmNetworkRequest" SG_ 74 AMP_PESSDesignSet 1;
BA_ "GenSigSendType" SG_ 74 AMP_PESSAPSSet 4;
BA_ "GenSigStartValue" SG_ 74 AMP_PESSAPSSet 7;
BA_ "NmNetworkRequest" SG_ 74 AMP_PESSAPSSet 1;
BA_ "GenSigSendType" SG_ 74 AMP_PESSVolumeSet 4;
BA_ "GenSigStartValue" SG_ 74 AMP_PESSVolumeSet 255;
BA_ "NmNetworkRequest" SG_ 74 AMP_PESSVolumeSet 1;
BA_ "GenSigSendType" SG_ 327 TMU_TbT_TurnIcon 4;
BA_ "NmNetworkRequest" SG_ 327 TMU_TbT_TurnIcon 1;
BA_ "TimeoutValue" SG_ 327 TMU_TbT_TurnIcon "0x00";
BA_ "GenSigSendType" SG_ 327 TMU_TbT_CountDownBar 4;
BA_ "NmNetworkRequest" SG_ 327 TMU_TbT_CountDownBar 1;
BA_ "TimeoutValue" SG_ 327 TMU_TbT_CountDownBar "0x00";
BA_ "GenSigSendType" SG_ 327 TMU_TbT_Distance_Unit 4;
BA_ "NmNetworkRequest" SG_ 327 TMU_TbT_Distance_Unit 1;
BA_ "TimeoutValue" SG_ 327 TMU_TbT_Distance_Unit "0x00";
BA_ "GenSigSendType" SG_ 327 TMU_TbT_DestDistance_Unit 4;
BA_ "NmNetworkRequest" SG_ 327 TMU_TbT_DestDistance_Unit 1;
BA_ "TimeoutValue" SG_ 327 TMU_TbT_DestDistance_Unit "0x00";
BA_ "GenSigSendType" SG_ 327 TMU_TbT_DistanceLo 4;
BA_ "NmNetworkRequest" SG_ 327 TMU_TbT_DistanceLo 1;
BA_ "TimeoutValue" SG_ 327 TMU_TbT_DistanceLo "0x00";
BA_ "GenSigSendType" SG_ 327 TMU_TbT_DistanceHi 4;
BA_ "NmNetworkRequest" SG_ 327 TMU_TbT_DistanceHi 1;
BA_ "TimeoutValue" SG_ 327 TMU_TbT_DistanceHi "0x00";
BA_ "GenSigSendType" SG_ 327 TMU_TbT_DestDistanceLo 4;
BA_ "NmNetworkRequest" SG_ 327 TMU_TbT_DestDistanceLo 1;
BA_ "TimeoutValue" SG_ 327 TMU_TbT_DestDistanceLo "0x00";
BA_ "GenSigSendType" SG_ 327 TMU_TbT_DestDistanceHi 4;
BA_ "NmNetworkRequest" SG_ 327 TMU_TbT_DestDistanceHi 1;
BA_ "TimeoutValue" SG_ 327 TMU_TbT_DestDistanceHi "0x00";
BA_ "GenSigSendType" SG_ 327 TMU_TbT_ExpectRemainHour 4;
BA_ "NmNetworkRequest" SG_ 327 TMU_TbT_ExpectRemainHour 1;
BA_ "TimeoutValue" SG_ 327 TMU_TbT_ExpectRemainHour "0x00";
BA_ "GenSigSendType" SG_ 327 TMU_TbT_ExpectRemainMin 4;
BA_ "NmNetworkRequest" SG_ 327 TMU_TbT_ExpectRemainMin 1;
BA_ "TimeoutValue" SG_ 327 TMU_TbT_ExpectRemainMin "0x00";
BA_ "GenSigSendType" SG_ 326 TMU_CallStatus 4;
BA_ "NmNetworkRequest" SG_ 326 TMU_CallStatus 1;
BA_ "TimeoutValue" SG_ 326 TMU_CallStatus "0x00";
BA_ "GenSigSendType" SG_ 326 TMU_CallType 4;
BA_ "NmNetworkRequest" SG_ 326 TMU_CallType 1;
BA_ "TimeoutValue" SG_ 326 TMU_CallType "0x00";
BA_ "GenSigSendType" SG_ 326 TMU_CDMA_Streng 4;
BA_ "NmNetworkRequest" SG_ 326 TMU_CDMA_Streng 1;
BA_ "TimeoutValue" SG_ 326 TMU_CDMA_Streng "0x00";
BA_ "GenSigSendType" SG_ 326 TMU_PacketStatus 4;
BA_ "NmNetworkRequest" SG_ 326 TMU_PacketStatus 1;
BA_ "TimeoutValue" SG_ 326 TMU_PacketStatus "0x00";
BA_ "GenSigSendType" SG_ 326 TMU_TalkTimeHour 4;
BA_ "NmNetworkRequest" SG_ 326 TMU_TalkTimeHour 1;
BA_ "TimeoutValue" SG_ 326 TMU_TalkTimeHour "0x00";
BA_ "GenSigSendType" SG_ 326 TMU_TalkTimeMinute 4;
BA_ "NmNetworkRequest" SG_ 326 TMU_TalkTimeMinute 1;
BA_ "TimeoutValue" SG_ 326 TMU_TalkTimeMinute "0x00";
BA_ "GenSigSendType" SG_ 326 TMU_TalkTimeSecond 4;
BA_ "NmNetworkRequest" SG_ 326 TMU_TalkTimeSecond 1;
BA_ "TimeoutValue" SG_ 326 TMU_TalkTimeSecond "0x00";
BA_ "GenSigSendType" SG_ 325 TMU_AliveStatus 4;
BA_ "GenSigStartValue" SG_ 325 TMU_AliveStatus 7;
BA_ "NmNetworkRequest" SG_ 325 TMU_AliveStatus 1;
BA_ "TimeoutValue" SG_ 325 TMU_AliveStatus "Invalid";
BA_ "GenSigSendType" SG_ 325 TMU_AudioStatus 4;
BA_ "NmNetworkRequest" SG_ 325 TMU_AudioStatus 1;
BA_ "TimeoutValue" SG_ 325 TMU_AudioStatus "0x00";
BA_ "GenSigSendType" SG_ 325 TMU_UpdateStatus 4;
BA_ "NmNetworkRequest" SG_ 325 TMU_UpdateStatus 1;
BA_ "TimeoutValue" SG_ 325 TMU_UpdateStatus "0x00";
BA_ "GenSigSendType" SG_ 325 TMU_LangStatus 4;
BA_ "NmNetworkRequest" SG_ 325 TMU_LangStatus 1;
BA_ "TimeoutValue" SG_ 325 TMU_LangStatus "0x00";
BA_ "GenSigSendType" SG_ 325 TMU_VoiceRecStatus 4;
BA_ "NmNetworkRequest" SG_ 325 TMU_VoiceRecStatus 1;
BA_ "TimeoutValue" SG_ 325 TMU_VoiceRecStatus "0x00";
BA_ "GenSigSendType" SG_ 325 TMU_MicStatus 4;
BA_ "NmNetworkRequest" SG_ 325 TMU_MicStatus 1;
BA_ "TimeoutValue" SG_ 325 TMU_MicStatus "0x00";
BA_ "GenSigSendType" SG_ 325 TMU_ServCommuStatus 4;
BA_ "NmNetworkRequest" SG_ 325 TMU_ServCommuStatus 1;
BA_ "TimeoutValue" SG_ 325 TMU_ServCommuStatus "0x00";
BA_ "GenSigSendType" SG_ 325 TMU_PowerStatus 4;
BA_ "NmNetworkRequest" SG_ 325 TMU_PowerStatus 1;
BA_ "TimeoutValue" SG_ 325 TMU_PowerStatus "0x00";
BA_ "GenSigSendType" SG_ 325 TMU_EngineStatus 4;
BA_ "NmNetworkRequest" SG_ 325 TMU_EngineStatus 1;
BA_ "TimeoutValue" SG_ 325 TMU_EngineStatus "0x00";
BA_ "GenSigSendType" SG_ 325 TMU_DownProgress 4;
BA_ "GenSigStartValue" SG_ 325 TMU_DownProgress 255;
BA_ "NmNetworkRequest" SG_ 325 TMU_DownProgress 1;
BA_ "TimeoutValue" SG_ 325 TMU_DownProgress "0xFF";
BA_ "GenSigSendType" SG_ 69 TMU_eCall 3;
BA_ "GenSigStartValue" SG_ 69 TMU_eCall 3;
BA_ "GenSigSendType" SG_ 67 C_ReqDrLock 4;
BA_ "NmNetworkRequest" SG_ 67 C_ReqDrLock 1;
BA_ "Validity" SG_ 67 C_ReqDrLock 0;
BA_ "GenSigSendType" SG_ 67 C_ReqDrUnlock 4;
BA_ "NmNetworkRequest" SG_ 67 C_ReqDrUnlock 1;
BA_ "Validity" SG_ 67 C_ReqDrUnlock 0;
BA_ "GenSigSendType" SG_ 67 C_ReqHazard 4;
BA_ "NmNetworkRequest" SG_ 67 C_ReqHazard 1;
BA_ "Validity" SG_ 67 C_ReqHazard 0;
BA_ "GenSigSendType" SG_ 67 C_ReqHorn 4;
BA_ "NmNetworkRequest" SG_ 67 C_ReqHorn 1;
BA_ "Validity" SG_ 67 C_ReqHorn 0;
BA_ "GenSigSendType" SG_ 67 C_ReqEngineOperate 4;
BA_ "NmNetworkRequest" SG_ 67 C_ReqEngineOperate 1;
BA_ "Validity" SG_ 67 C_ReqEngineOperate 0;
BA_ "GenSigSendType" SG_ 66 CDMA_SelfDiag 4;
BA_ "NmNetworkRequest" SG_ 66 CDMA_SelfDiag 1;
BA_ "GenSigSendType" SG_ 66 CDMA_Antena_SelfDiag 4;
BA_ "NmNetworkRequest" SG_ 66 CDMA_Antena_SelfDiag 1;
BA_ "GenSigStartValue" SG_ 1345 TMU_SupVoiceTextService 3;
BA_ "TimeoutValue" SG_ 1345 TMU_SupVoiceTextService "Invalid";
BA_ "GenSigStartValue" SG_ 1345 TMU_SupEcoCoachService 3;
BA_ "TimeoutValue" SG_ 1345 TMU_SupEcoCoachService "Invalid";
BA_ "GenSigStartValue" SG_ 1345 TMU_SupSongTagService 3;
BA_ "TimeoutValue" SG_ 1345 TMU_SupSongTagService "Invalid";
BA_ "GenSigStartValue" SG_ 1345 TMU_SupContentService 3;
BA_ "TimeoutValue" SG_ 1345 TMU_SupContentService "Invalid";
BA_ "GenSigStartValue" SG_ 1345 TMU_MajorVersion 255;
BA_ "TimeoutValue" SG_ 1345 TMU_MajorVersion "Invalid";
BA_ "GenSigStartValue" SG_ 1345 TMU_MinorVersion 255;
BA_ "TimeoutValue" SG_ 1345 TMU_MinorVersion "Invalid";
BA_ "GenSigStartValue" SG_ 1345 TMU_DistributeInfo 15;
BA_ "TimeoutValue" SG_ 1345 TMU_DistributeInfo "Invalid";
BA_ "GenSigSendType" SG_ 65 TMU_BarLevel1 4;
BA_ "NmNetworkRequest" SG_ 65 TMU_BarLevel1 1;
BA_ "GenSigSendType" SG_ 65 TMU_BarLevel2 4;
BA_ "NmNetworkRequest" SG_ 65 TMU_BarLevel2 1;
BA_ "GenSigSendType" SG_ 65 TMU_BarLevel4 4;
BA_ "NmNetworkRequest" SG_ 65 TMU_BarLevel4 1;
BA_ "GenSigSendType" SG_ 65 TMU_BarLevel3 4;
BA_ "NmNetworkRequest" SG_ 65 TMU_BarLevel3 1;
BA_ "GenSigSendType" SG_ 65 TMU_BarLevel5 4;
BA_ "NmNetworkRequest" SG_ 65 TMU_BarLevel5 1;
BA_ "GenSigSendType" SG_ 65 TMU_BarLevel6 4;
BA_ "NmNetworkRequest" SG_ 65 TMU_BarLevel6 1;
BA_ "GenSigSendType" SG_ 65 TMU_BarLevel8 4;
BA_ "NmNetworkRequest" SG_ 65 TMU_BarLevel8 1;
BA_ "GenSigSendType" SG_ 65 TMU_BarLevel7 4;
BA_ "NmNetworkRequest" SG_ 65 TMU_BarLevel7 1;
BA_ "GenSigSendType" SG_ 65 TMU_BarLevel9 4;
BA_ "NmNetworkRequest" SG_ 65 TMU_BarLevel9 1;
BA_ "GenSigSendType" SG_ 65 TMU_BarLevel10 4;
BA_ "NmNetworkRequest" SG_ 65 TMU_BarLevel10 1;
BA_ "GenSigStartValue" SG_ 1344 TMU_Arrow 3;
BA_ "TimeoutValue" SG_ 1344 TMU_Arrow "Invalid";
BA_ "TimeoutValue" SG_ 1344 TMU_ReFill_Info "0x00";
BA_ "TimeoutValue" SG_ 1344 TMU_AverageMPG "0x00";
BA_ "TimeoutValue" SG_ 1344 TMU_TotalMPG "0x00";
BA_ "TimeoutValue" SG_ 1344 TMU_RewardStar "0x00";
BA_ "GenSigSendType" SG_ 64 TMU_DisMode 4;
BA_ "NmNetworkRequest" SG_ 64 TMU_DisMode 1;
BA_ "GenSigSendType" SG_ 64 TMU_AudSrcType 4;
BA_ "NmNetworkRequest" SG_ 64 TMU_AudSrcType 1;
BA_ "GenSigSendType" SG_ 64 TMU_AudReqCmd 4;
BA_ "NmNetworkRequest" SG_ 64 TMU_AudReqCmd 1;
BA_ "GenSigSendType" SG_ 64 TMU_LangCmd 4;
BA_ "NmNetworkRequest" SG_ 64 TMU_LangCmd 1;
BA_ "GenSigSendType" SG_ 64 TMU_ServReq 4;
BA_ "NmNetworkRequest" SG_ 64 TMU_ServReq 1;
BA_ "GenSigSendType" SG_ 64 TMU_ErrorEvent 4;
BA_ "NmNetworkRequest" SG_ 64 TMU_ErrorEvent 1;
BA_ "GenSigSendType" SG_ 64 TMU_BeepCmd 4;
BA_ "NmNetworkRequest" SG_ 64 TMU_BeepCmd 1;
BA_ "GenSigSendType" SG_ 64 TMU_eCall 4;
BA_ "GenSigStartValue" SG_ 64 TMU_eCall 3;
BA_ "NmNetworkRequest" SG_ 64 TMU_eCall 1;
BA_REL_ "GenSigTimeoutTime" BU_SG_REL_ H_U SG_ 139 AMP_Beep2VolumeState 0;
BA_REL_ "GenSigTimeoutTime" BU_SG_REL_ H_U SG_ 139 AMP_Beep2FrequencyState 0;
BA_REL_ "GenSigTimeoutTime" BU_SG_REL_ H_U SG_ 139 AMP_Beep2OutputMaskState 0;
BA_REL_ "GenSigTimeoutTime" BU_SG_REL_ H_U SG_ 139 AMP_Beep2DOnState 0;
BA_REL_ "GenSigTimeoutTime" BU_SG_REL_ H_U SG_ 139 AMP_Beep2DOffState 0;
BA_REL_ "GenSigTimeoutTime" BU_SG_REL_ H_U SG_ 139 AMP_Beep2NOfCycleState 0;
BA_REL_ "GenSigTimeoutTime" BU_SG_REL_ H_U SG_ 138 AMP_Beep1VolumeState 0;
BA_REL_ "GenSigTimeoutTime" BU_SG_REL_ H_U SG_ 138 AMP_Beep1FrequencyState 0;
BA_REL_ "GenSigTimeoutTime" BU_SG_REL_ H_U SG_ 138 AMP_Beep1OutputMaskState 0;
BA_REL_ "GenSigTimeoutTime" BU_SG_REL_ H_U SG_ 138 AMP_Beep1DOnState 0;
BA_REL_ "GenSigTimeoutTime" BU_SG_REL_ H_U SG_ 138 AMP_Beep1DOffState 0;
BA_REL_ "GenSigTimeoutTime" BU_SG_REL_ H_U SG_ 138 AMP_Beep1NOfCycleState 0;
BA_REL_ "GenSigTimeoutTime" BU_SG_REL_ H_U SG_ 137 AMP_MTSOutputMaskSupport 0;
BA_REL_ "GenSigTimeoutTime" BU_SG_REL_ H_U SG_ 137 AMP_MTSMuteMaskSupport 0;
BA_REL_ "GenSigTimeoutTime" BU_SG_REL_ H_U SG_ 137 AMP_HFOutputMaskSupport 0;
BA_REL_ "GenSigTimeoutTime" BU_SG_REL_ H_U SG_ 137 AMP_HFMuteMaskSupport 0;
BA_REL_ "GenSigTimeoutTime" BU_SG_REL_ H_U SG_ 137 AMP_NaviOutputMaskSupport 0;
BA_REL_ "GenSigTimeoutTime" BU_SG_REL_ H_U SG_ 137 AMP_NaviMuteMaskSupport 0;
BA_REL_ "GenSigTimeoutTime" BU_SG_REL_ EDT SG_ 1928 Byte0_TCP_788 0;
BA_REL_ "GenSigTimeoutTime" BU_SG_REL_ EDT SG_ 1928 Byte1_Data_788 0;
BA_REL_ "GenSigTimeoutTime" BU_SG_REL_ EDT SG_ 1928 Byte2_Data_788 0;
BA_REL_ "GenSigTimeoutTime" BU_SG_REL_ EDT SG_ 1928 Byte3_Data_788 0;
BA_REL_ "GenSigTimeoutTime" BU_SG_REL_ EDT SG_ 1928 Byte4_Data_788 0;
BA_REL_ "GenSigTimeoutTime" BU_SG_REL_ EDT SG_ 1928 Byte5_Data_788 0;
BA_REL_ "GenSigTimeoutTime" BU_SG_REL_ EDT SG_ 1928 Byte6_Data_788 0;
BA_REL_ "GenSigTimeoutTime" BU_SG_REL_ EDT SG_ 1928 Byte7_Data_788 0;
BA_REL_ "GenSigTimeoutTime" BU_SG_REL_ H_U SG_ 136 AMP_MaxBeep2VolumeState 0;
BA_REL_ "GenSigTimeoutTime" BU_SG_REL_ H_U SG_ 136 AMP_MaxBeep2Freq_State 0;
BA_REL_ "GenSigTimeoutTime" BU_SG_REL_ H_U SG_ 136 AMP_Beep2OutputMaskSup 0;
BA_REL_ "GenSigTimeoutTime" BU_SG_REL_ H_U SG_ 136 AMP_MaxBeep2DOnState 0;
BA_REL_ "GenSigTimeoutTime" BU_SG_REL_ H_U SG_ 136 AMP_MaxBeep2DOffState 0;
BA_REL_ "GenSigTimeoutTime" BU_SG_REL_ H_U SG_ 136 AMP_MaxBeep2NOfCycleState 0;
BA_REL_ "GenSigTimeoutTime" BU_SG_REL_ H_U SG_ 135 AMP_MaxBeep1VolumeState 0;
BA_REL_ "GenSigTimeoutTime" BU_SG_REL_ H_U SG_ 135 AMP_MaxBeep1Freq_State 0;
BA_REL_ "GenSigTimeoutTime" BU_SG_REL_ H_U SG_ 135 AMP_Beep1OutputMaskSup 0;
BA_REL_ "GenSigTimeoutTime" BU_SG_REL_ H_U SG_ 135 AMP_MaxBeep1DOnState 0;
BA_REL_ "GenSigTimeoutTime" BU_SG_REL_ H_U SG_ 135 AMP_MaxBeep1DOffState 0;
BA_REL_ "GenSigTimeoutTime" BU_SG_REL_ H_U SG_ 135 AMP_MaxBeep1NOfCycleState 0;
BA_REL_ "GenSigTimeoutTime" BU_SG_REL_ H_U SG_ 134 ASD_SetValue 0;
BA_REL_ "GenSigTimeoutTime" BU_SG_REL_ IBOX SG_ 134 ASD_SetValue 0;
BA_REL_ "GenSigTimeoutTime" BU_SG_REL_ H_U SG_ 134 ASD_Version 0;
BA_REL_ "GenSigTimeoutTime" BU_SG_REL_ IBOX SG_ 134 ASD_Version 0;
BA_REL_ "GenSigTimeoutTime" BU_SG_REL_ CLU SG_ 1157 Byte0_TCP_485 0;
BA_REL_ "GenSigTimeoutTime" BU_SG_REL_ CLU SG_ 1157 Byte1_Data_485 0;
BA_REL_ "GenSigTimeoutTime" BU_SG_REL_ CLU SG_ 1157 Byte2_Data_485 0;
BA_REL_ "GenSigTimeoutTime" BU_SG_REL_ CLU SG_ 1157 Byte3_Data_485 0;
BA_REL_ "GenSigTimeoutTime" BU_SG_REL_ CLU SG_ 1157 Byte4_Data_485 0;
BA_REL_ "GenSigTimeoutTime" BU_SG_REL_ CLU SG_ 1157 Byte5_Data_485 0;
BA_REL_ "GenSigTimeoutTime" BU_SG_REL_ CLU SG_ 1157 Byte6_Data_485 0;
BA_REL_ "GenSigTimeoutTime" BU_SG_REL_ CLU SG_ 1157 Byte7_Data_485 0;
BA_REL_ "GenSigTimeoutTime" BU_SG_REL_ H_U SG_ 133 AMP_MaxVolumeStep 0;
BA_REL_ "GenSigTimeoutTime" BU_SG_REL_ H_U SG_ 133 AMP_MaxBalanceStep 0;
BA_REL_ "GenSigTimeoutTime" BU_SG_REL_ H_U SG_ 133 AMP_MaxFadeStep 0;
BA_REL_ "GenSigTimeoutTime" BU_SG_REL_ H_U SG_ 133 AMP_MaxBassStep 0;
BA_REL_ "GenSigTimeoutTime" BU_SG_REL_ H_U SG_ 133 AMP_MaxMidStep 0;
BA_REL_ "GenSigTimeoutTime" BU_SG_REL_ H_U SG_ 133 AMP_MaxTrebleStep 0;
BA_REL_ "GenSigTimeoutTime" BU_SG_REL_ H_U SG_ 133 AMP_ASDMajorVer 0;
BA_REL_ "GenSigTimeoutTime" BU_SG_REL_ H_U SG_ 133 AMP_ASDMinorVer 0;
BA_REL_ "GenSigTimeoutTime" BU_SG_REL_ H_U SG_ 389 AMP_EngOrderC2Setting 7000;
BA_REL_ "GenSigTimeoutTime" BU_SG_REL_ H_U SG_ 389 AMP_EngOrderC4Setting 7000;
BA_REL_ "GenSigTimeoutTime" BU_SG_REL_ H_U SG_ 389 AMP_EngOrderC6Setting 7000;
BA_REL_ "GenSigTimeoutTime" BU_SG_REL_ H_U SG_ 389 AMP_APSBand0Setting 7000;
BA_REL_ "GenSigTimeoutTime" BU_SG_REL_ H_U SG_ 389 AMP_APSBand1Setting 7000;
BA_REL_ "GenSigTimeoutTime" BU_SG_REL_ H_U SG_ 389 AMP_APSBand2Setting 7000;
BA_REL_ "GenSigTimeoutTime" BU_SG_REL_ H_U SG_ 389 AMP_APSBand3Setting 7000;
BA_REL_ "GenSigTimeoutTime" BU_SG_REL_ H_U SG_ 389 AMP_APSBand4Setting 7000;
BA_REL_ "GenSigTimeoutTime" BU_SG_REL_ H_U SG_ 132 AMP_HFVolumeState 0;
BA_REL_ "GenSigTimeoutTime" BU_SG_REL_ H_U SG_ 132 AMP_HFAudioCutState 0;
BA_REL_ "GenSigTimeoutTime" BU_SG_REL_ H_U SG_ 132 AMP_HFOutputMaskState 0;
BA_REL_ "GenSigTimeoutTime" BU_SG_REL_ H_U SG_ 132 AMP_HFMuteMaskState 0;
BA_REL_ "GenSigTimeoutTime" BU_SG_REL_ H_U SG_ 132 AMP_MaxHFVolumeState 0;
BA_REL_ "GenSigTimeoutTime" BU_SG_REL_ H_U SG_ 132 AMP_MaxHFAudioCutState 0;
BA_REL_ "GenSigTimeoutTime" BU_SG_REL_ H_U SG_ 388 AMP_PESSModeState 7000;
BA_REL_ "GenSigTimeoutTime" BU_SG_REL_ H_U SG_ 388 AMP_PESSDesignSetting 7000;
BA_REL_ "GenSigTimeoutTime" BU_SG_REL_ H_U SG_ 388 AMP_PESSAPSSetting 7000;
BA_REL_ "GenSigTimeoutTime" BU_SG_REL_ H_U SG_ 388 AMP_PESSVolumeSetting 7000;
BA_REL_ "GenSigTimeoutTime" BU_SG_REL_ H_U SG_ 1156 Byte0_TCP_484 0;
BA_REL_ "GenSigTimeoutTime" BU_SG_REL_ H_U SG_ 1156 Byte1_Data_484 0;
BA_REL_ "GenSigTimeoutTime" BU_SG_REL_ H_U SG_ 1156 Byte2_Data_484 0;
BA_REL_ "GenSigTimeoutTime" BU_SG_REL_ H_U SG_ 1156 Byte3_Data_484 0;
BA_REL_ "GenSigTimeoutTime" BU_SG_REL_ H_U SG_ 1156 Byte4_Data_484 0;
BA_REL_ "GenSigTimeoutTime" BU_SG_REL_ H_U SG_ 1156 Byte5_Data_484 0;
BA_REL_ "GenSigTimeoutTime" BU_SG_REL_ H_U SG_ 1156 Byte6_Data_484 0;
BA_REL_ "GenSigTimeoutTime" BU_SG_REL_ H_U SG_ 1156 Byte7_Data_484 0;
BA_REL_ "GenSigTimeoutTime" BU_SG_REL_ H_U SG_ 131 AMP_MTSVolumeState 0;
BA_REL_ "GenSigTimeoutTime" BU_SG_REL_ H_U SG_ 131 AMP_MTSAudioCutState 0;
BA_REL_ "GenSigTimeoutTime" BU_SG_REL_ H_U SG_ 131 AMP_MTSOutputMaskState 0;
BA_REL_ "GenSigTimeoutTime" BU_SG_REL_ H_U SG_ 131 AMP_MTSMuteMaskState 0;
BA_REL_ "GenSigTimeoutTime" BU_SG_REL_ H_U SG_ 131 AMP_MaxMTSVolumeState 0;
BA_REL_ "GenSigTimeoutTime" BU_SG_REL_ H_U SG_ 131 AMP_MaxMTSAudioCutState 0;
BA_REL_ "GenSigTimeoutTime" BU_SG_REL_ H_U SG_ 387 AMP_MainVolumeSetting 7000;
BA_REL_ "GenSigTimeoutTime" BU_SG_REL_ H_U SG_ 387 AMP_BalanceSetting 7000;
BA_REL_ "GenSigTimeoutTime" BU_SG_REL_ H_U SG_ 387 AMP_FadeSetting 7000;
BA_REL_ "GenSigTimeoutTime" BU_SG_REL_ H_U SG_ 387 AMP_BassSetting 7000;
BA_REL_ "GenSigTimeoutTime" BU_SG_REL_ H_U SG_ 387 AMP_MidSetting 7000;
BA_REL_ "GenSigTimeoutTime" BU_SG_REL_ H_U SG_ 387 AMP_TrebleSetting 7000;
BA_REL_ "GenSigTimeoutTime" BU_SG_REL_ H_U SG_ 387 AMP_VehicleSpeedamp 7000;
BA_REL_ "GenSigTimeoutTime" BU_SG_REL_ H_U SG_ 130 AMP_NaviVolumeState 0;
BA_REL_ "GenSigTimeoutTime" BU_SG_REL_ H_U SG_ 130 AMP_NaviAudioCutState 0;
BA_REL_ "GenSigTimeoutTime" BU_SG_REL_ H_U SG_ 130 AMP_NaviOutputMaskState 0;
BA_REL_ "GenSigTimeoutTime" BU_SG_REL_ H_U SG_ 130 AMP_NaviMuteMaskState 0;
BA_REL_ "GenSigTimeoutTime" BU_SG_REL_ H_U SG_ 130 AMP_MaxNaviVolumeState 0;
BA_REL_ "GenSigTimeoutTime" BU_SG_REL_ H_U SG_ 130 AMP_MaxNaviAudioCutState 0;
BA_REL_ "GenSigTimeoutTime" BU_SG_REL_ H_U SG_ 129 AMP_DriveState 0;
BA_REL_ "GenSigTimeoutTime" BU_SG_REL_ H_U SG_ 129 AMP_ConvertibleTopState 0;
BA_REL_ "GenSigTimeoutTime" BU_SG_REL_ H_U SG_ 385 AMP_MuteState 3500;
BA_REL_ "GenSigTimeoutTime" BU_SG_REL_ H_U SG_ 385 AMP_RearSpMuteState 3500;
BA_REL_ "GenSigTimeoutTime" BU_SG_REL_ H_U SG_ 385 AMP_SurroundModeState 3500;
BA_REL_ "GenSigTimeoutTime" BU_SG_REL_ H_U SG_ 385 AMP_EQState 3500;
BA_REL_ "GenSigTimeoutTime" BU_SG_REL_ H_U SG_ 385 AMP_SPDIFMuteSt 3500;
BA_REL_ "GenSigTimeoutTime" BU_SG_REL_ H_U SG_ 385 AMP_BeatsModeState 3500;
BA_REL_ "GenSigTimeoutTime" BU_SG_REL_ H_U SG_ 385 AMP_DefaultBeep1St 3500;
BA_REL_ "GenSigTimeoutTime" BU_SG_REL_ H_U SG_ 385 AMP_DefaultBeep2St 3500;
BA_REL_ "GenSigTimeoutTime" BU_SG_REL_ H_U SG_ 385 AMP_AudioSource 3500;
BA_REL_ "GenSigTimeoutTime" BU_SG_REL_ H_U SG_ 385 AMP_VIPModeState 3500;
BA_REL_ "GenSigTimeoutTime" BU_SG_REL_ H_U SG_ 385 AMP_QLSModeState 3500;
BA_REL_ "GenSigTimeoutTime" BU_SG_REL_ H_U SG_ 128 AMP_CurrentVehicleID 0;
BA_REL_ "GenSigTimeoutTime" BU_SG_REL_ H_U SG_ 128 AMP_SPDIFModeState 0;
BA_REL_ "GenSigTimeoutTime" BU_SG_REL_ H_U SG_ 128 AMP_MajorVer 0;
BA_REL_ "GenSigTimeoutTime" BU_SG_REL_ MON SG_ 128 AMP_MajorVer 0;
BA_REL_ "GenSigTimeoutTime" BU_SG_REL_ H_U SG_ 128 AMP_MinorVer 0;
BA_REL_ "GenSigTimeoutTime" BU_SG_REL_ MON SG_ 128 AMP_MinorVer 0;
BA_REL_ "GenSigTimeoutTime" BU_SG_REL_ H_U SG_ 128 AMP_UpdateStartResp 0;
BA_REL_ "GenSigTimeoutTime" BU_SG_REL_ H_U SG_ 128 AMP_UpdateEndResp 0;
BA_REL_ "GenSigTimeoutTime" BU_SG_REL_ H_U SG_ 128 AMP_TuningMajorVer 0;
BA_REL_ "GenSigTimeoutTime" BU_SG_REL_ H_U SG_ 128 AMP_TuningMinorVer 0;
BA_REL_ "GenSigTimeoutTime" BU_SG_REL_ CLU SG_ 384 AMP_HFModeState 3500;
BA_REL_ "GenSigTimeoutTime" BU_SG_REL_ H_U SG_ 384 AMP_HFModeState 3500;
BA_REL_ "GenSigTimeoutTime" BU_SG_REL_ CLU SG_ 384 HU_InitInfo 3500;
BA_REL_ "GenSigTimeoutTime" BU_SG_REL_ H_U SG_ 384 HU_InitInfo 3500;
BA_REL_ "GenSigTimeoutTime" BU_SG_REL_ CLU SG_ 384 AMP_ASDModeState 3500;
BA_REL_ "GenSigTimeoutTime" BU_SG_REL_ H_U SG_ 384 AMP_ASDModeState 3500;
BA_REL_ "GenSigTimeoutTime" BU_SG_REL_ CLU SG_ 384 AMP_NaviModeState 3500;
BA_REL_ "GenSigTimeoutTime" BU_SG_REL_ H_U SG_ 384 AMP_NaviModeState 3500;
BA_REL_ "GenSigTimeoutTime" BU_SG_REL_ CLU SG_ 384 AMP_SPDIFInfo 3500;
BA_REL_ "GenSigTimeoutTime" BU_SG_REL_ H_U SG_ 384 AMP_SPDIFInfo 3500;
BA_REL_ "GenSigTimeoutTime" BU_SG_REL_ CLU SG_ 384 AMP_MTSModeState 3500;
BA_REL_ "GenSigTimeoutTime" BU_SG_REL_ H_U SG_ 384 AMP_MTSModeState 3500;
BA_REL_ "GenSigTimeoutTime" BU_SG_REL_ CLU SG_ 384 AMP_VSCModeState 3500;
BA_REL_ "GenSigTimeoutTime" BU_SG_REL_ H_U SG_ 384 AMP_VSCModeState 3500;
BA_REL_ "GenSigTimeoutTime" BU_SG_REL_ CLU SG_ 384 AMP_SDVCStepState 3500;
BA_REL_ "GenSigTimeoutTime" BU_SG_REL_ H_U SG_ 384 AMP_SDVCStepState 3500;
BA_REL_ "GenSigTimeoutTime" BU_SG_REL_ CLU SG_ 384 AMP_Beep1ModeState 3500;
BA_REL_ "GenSigTimeoutTime" BU_SG_REL_ H_U SG_ 384 AMP_Beep1ModeState 3500;
BA_REL_ "GenSigTimeoutTime" BU_SG_REL_ CLU SG_ 384 AMP_Beep2ModeState 3500;
BA_REL_ "GenSigTimeoutTime" BU_SG_REL_ H_U SG_ 384 AMP_Beep2ModeState 3500;
BA_REL_ "GenSigTimeoutTime" BU_SG_REL_ CLU SG_ 384 AMP_DistrInfoState 3500;
BA_REL_ "GenSigTimeoutTime" BU_SG_REL_ H_U SG_ 384 AMP_DistrInfoState 3500;
BA_REL_ "GenSigTimeoutTime" BU_SG_REL_ CGW SG_ 384 AMP_INFORM_TO_IPM 3500;
BA_REL_ "GenSigTimeoutTime" BU_SG_REL_ CLU SG_ 384 AMP_INFORM_TO_IPM 3500;
BA_REL_ "GenSigTimeoutTime" BU_SG_REL_ DATC SG_ 384 AMP_INFORM_TO_IPM 3500;
BA_REL_ "GenSigTimeoutTime" BU_SG_REL_ H_U SG_ 384 AMP_INFORM_TO_IPM 3500;
BA_REL_ "GenSigTimeoutTime" BU_SG_REL_ IPM SG_ 384 AMP_INFORM_TO_IPM 3500;
BA_REL_ "GenSigTimeoutTime" BU_SG_REL_ H_U SG_ 384 AMP_SignalDoctorState 3500;
BA_REL_ "GenSigTimeoutTime" BU_SG_REL_ H_U SG_ 384 AMP_AutoVolumeState 3500;
BA_REL_ "GenSigTimeoutTime" BU_SG_REL_ H_U SG_ 1920 Byte0_TCP_780 0;
BA_REL_ "GenSigTimeoutTime" BU_SG_REL_ H_U SG_ 1920 Byte1_Data_780 0;
BA_REL_ "GenSigTimeoutTime" BU_SG_REL_ H_U SG_ 1920 Byte2_Data_780 0;
BA_REL_ "GenSigTimeoutTime" BU_SG_REL_ H_U SG_ 1920 Byte3_Data_780 0;
BA_REL_ "GenSigTimeoutTime" BU_SG_REL_ H_U SG_ 1920 Byte4_Data_780 0;
BA_REL_ "GenSigTimeoutTime" BU_SG_REL_ H_U SG_ 1920 Byte5_Data_780 0;
BA_REL_ "GenSigTimeoutTime" BU_SG_REL_ H_U SG_ 1920 Byte6_Data_780 0;
BA_REL_ "GenSigTimeoutTime" BU_SG_REL_ H_U SG_ 1920 Byte7_Data_780 0;
BA_REL_ "GenSigTimeoutTime" BU_SG_REL_ TMU SG_ 1392 HU_GPS_Signal 3500;
BA_REL_ "GenSigTimeoutTime" BU_SG_REL_ AMP SG_ 112 AMP_Beep1VolumeStep 0;
BA_REL_ "GenSigTimeoutTime" BU_SG_REL_ AMP SG_ 112 AMP_Beep1Frequency 0;
BA_REL_ "GenSigTimeoutTime" BU_SG_REL_ AMP SG_ 112 AMP_Beep1Ch_OutputMask 0;
BA_REL_ "GenSigTimeoutTime" BU_SG_REL_ AMP SG_ 112 AMP_Beep1DurationOn 0;
BA_REL_ "GenSigTimeoutTime" BU_SG_REL_ AMP SG_ 112 AMP_Beep1DurationOff 0;
BA_REL_ "GenSigTimeoutTime" BU_SG_REL_ AMP SG_ 112 AMP_Beep1NumberOfCycles 0;
BA_REL_ "GenSigTimeoutTime" BU_SG_REL_ H_U SG_ 362 Lca_IndLeft 3500;
BA_REL_ "GenSigTimeoutTime" BU_SG_REL_ AMP SG_ 362 FL_SndWarn 3500;
BA_REL_ "GenSigTimeoutTime" BU_SG_REL_ AMP SG_ 362 FR_SndWarn 3500;
BA_REL_ "GenSigTimeoutTime" BU_SG_REL_ H_U SG_ 362 Lca_IndRight 3500;
BA_REL_ "GenSigTimeoutTime" BU_SG_REL_ H_U SG_ 362 RCTA_IndLeft 3500;
BA_REL_ "GenSigTimeoutTime" BU_SG_REL_ AMP SG_ 362 RL_SndWarn 3500;
BA_REL_ "GenSigTimeoutTime" BU_SG_REL_ AMP SG_ 362 RR_SndWarn 3500;
BA_REL_ "GenSigTimeoutTime" BU_SG_REL_ H_U SG_ 362 RCTA_IndRight 3500;
BA_REL_ "GenSigTimeoutTime" BU_SG_REL_ AMP SG_ 359 Spas_BEEP_Alarm 3500;
BA_REL_ "GenSigTimeoutTime" BU_SG_REL_ AMP SG_ 359 Spas_Audio_VolumeDown 3500;
BA_REL_ "GenSigTimeoutTime" BU_SG_REL_ AMP SG_ 359 Spas_Spkr_Flh_Alarm 3500;
BA_REL_ "GenSigTimeoutTime" BU_SG_REL_ H_U SG_ 359 Spas_Spkr_Flh_Alarm 3500;
BA_REL_ "GenSigTimeoutTime" BU_SG_REL_ AMP SG_ 359 Spas_Spkr_Fcnt_Alarm 3500;
BA_REL_ "GenSigTimeoutTime" BU_SG_REL_ H_U SG_ 359 Spas_Spkr_Fcnt_Alarm 3500;
BA_REL_ "GenSigTimeoutTime" BU_SG_REL_ AMP SG_ 359 Spas_Spkr_Frh_Alarm 3500;
BA_REL_ "GenSigTimeoutTime" BU_SG_REL_ H_U SG_ 359 Spas_Spkr_Frh_Alarm 3500;
BA_REL_ "GenSigTimeoutTime" BU_SG_REL_ AMP SG_ 359 Spas_Spkr_Rlh_Alarm 3500;
BA_REL_ "GenSigTimeoutTime" BU_SG_REL_ H_U SG_ 359 Spas_Spkr_Rlh_Alarm 3500;
BA_REL_ "GenSigTimeoutTime" BU_SG_REL_ AMP SG_ 359 Spas_Spkr_Rcnt_Alarm 3500;
BA_REL_ "GenSigTimeoutTime" BU_SG_REL_ H_U SG_ 359 Spas_Spkr_Rcnt_Alarm 3500;
BA_REL_ "GenSigTimeoutTime" BU_SG_REL_ AMP SG_ 359 Spas_Spkr_Rrh_Alarm 3500;
BA_REL_ "GenSigTimeoutTime" BU_SG_REL_ H_U SG_ 359 Spas_Spkr_Rrh_Alarm 3500;
BA_REL_ "GenSigTimeoutTime" BU_SG_REL_ AMP SG_ 359 Lkas_SysStatus 3500;
BA_REL_ "GenSigTimeoutTime" BU_SG_REL_ H_U SG_ 359 Lkas_SysStatus 3500;
BA_REL_ "GenSigTimeoutTime" BU_SG_REL_ AMP SG_ 359 Lkas_LH_Warning 3500;
BA_REL_ "GenSigTimeoutTime" BU_SG_REL_ H_U SG_ 359 Lkas_LH_Warning 3500;
BA_REL_ "GenSigTimeoutTime" BU_SG_REL_ AMP SG_ 359 Lkas_RH_Warning 3500;
BA_REL_ "GenSigTimeoutTime" BU_SG_REL_ H_U SG_ 359 Lkas_RH_Warning 3500;
BA_REL_ "GenSigTimeoutTime" BU_SG_REL_ AMP SG_ 359 Spas_Spkr_Level 3500;
BA_REL_ "GenSigTimeoutTime" BU_SG_REL_ AMP SG_ 359 Lkas_Audio_VolumeDown 3500;
BA_REL_ "GenSigTimeoutTime" BU_SG_REL_ H_U SG_ 359 Lkas_Audio_VolumeDown 3500;
BA_REL_ "GenSigTimeoutTime" BU_SG_REL_ AMP SG_ 359 Audio_VolumeDown 3500;
BA_REL_ "GenSigTimeoutTime" BU_SG_REL_ H_U SG_ 359 Audio_VolumeDown 3500;
BA_REL_ "GenSigTimeoutTime" BU_SG_REL_ AMP SG_ 359 Pas_BEEP_Alarm 3500;
BA_REL_ "GenSigTimeoutTime" BU_SG_REL_ AMP SG_ 359 Pas_Audio_VolumeDown 3500;
BA_REL_ "GenSigTimeoutTime" BU_SG_REL_ H_U SG_ 359 Pas_Audio_VolumeDown 3500;
BA_REL_ "GenSigTimeoutTime" BU_SG_REL_ AMP SG_ 359 Pas_Spkr_Level 3500;
BA_REL_ "GenSigTimeoutTime" BU_SG_REL_ AMP SG_ 359 Pas_Spkr_Flh_Alarm 3500;
BA_REL_ "GenSigTimeoutTime" BU_SG_REL_ H_U SG_ 359 Pas_Spkr_Flh_Alarm 3500;
BA_REL_ "GenSigTimeoutTime" BU_SG_REL_ AMP SG_ 359 Pas_Spkr_Fcnt_Alarm 3500;
BA_REL_ "GenSigTimeoutTime" BU_SG_REL_ H_U SG_ 359 Pas_Spkr_Fcnt_Alarm 3500;
BA_REL_ "GenSigTimeoutTime" BU_SG_REL_ AMP SG_ 359 Pas_Spkr_Frh_Alarm 3500;
BA_REL_ "GenSigTimeoutTime" BU_SG_REL_ H_U SG_ 359 Pas_Spkr_Frh_Alarm 3500;
BA_REL_ "GenSigTimeoutTime" BU_SG_REL_ AMP SG_ 359 Pas_Spkr_Rlh_Alarm 3500;
BA_REL_ "GenSigTimeoutTime" BU_SG_REL_ H_U SG_ 359 Pas_Spkr_Rlh_Alarm 3500;
BA_REL_ "GenSigTimeoutTime" BU_SG_REL_ AMP SG_ 359 Pas_Spkr_Rcnt_Alarm 3500;
BA_REL_ "GenSigTimeoutTime" BU_SG_REL_ H_U SG_ 359 Pas_Spkr_Rcnt_Alarm 3500;
BA_REL_ "GenSigTimeoutTime" BU_SG_REL_ AMP SG_ 359 Pas_Spkr_Rrh_Alarm 3500;
BA_REL_ "GenSigTimeoutTime" BU_SG_REL_ H_U SG_ 359 Pas_Spkr_Rrh_Alarm 3500;
BA_REL_ "GenSigTimeoutTime" BU_SG_REL_ TMU SG_ 1376 HU_GPS_Signal2 3500;
BA_REL_ "GenSigTimeoutTime" BU_SG_REL_ TMU SG_ 1376 HU_GPS_Signal3 3500;
BA_REL_ "GenSigTimeoutTime" BU_SG_REL_ TMU SG_ 1376 HU_GPS_Signal4 3500;
BA_REL_ "GenSigTimeoutTime" BU_SG_REL_ H_U SG_ 93 DATC_SWVerMajor 0;
BA_REL_ "GenSigTimeoutTime" BU_SG_REL_ H_U SG_ 93 DATC_SWVerMinor 0;
BA_REL_ "GenSigTimeoutTime" BU_SG_REL_ H_U SG_ 93 DATC_CANVerMajor 0;
BA_REL_ "GenSigTimeoutTime" BU_SG_REL_ H_U SG_ 93 DATC_CANVerMinor 0;
BA_REL_ "GenSigTimeoutTime" BU_SG_REL_ H_U SG_ 344 CF_SMKRKECmd 1000;
BA_REL_ "GenSigTimeoutTime" BU_SG_REL_ CGW SG_ 87 NaviValidity 0;
BA_REL_ "GenSigTimeoutTime" BU_SG_REL_ CLU SG_ 87 NaviValidity 0;
BA_REL_ "GenSigTimeoutTime" BU_SG_REL_ H_U SG_ 343 CF_Lkas_TsrSlifOpt 500;
BA_REL_ "GenSigTimeoutTime" BU_SG_REL_ H_U SG_ 343 CF_Lkas_TsrStatus 500;
BA_REL_ "GenSigTimeoutTime" BU_SG_REL_ H_U SG_ 343 CF_Lkas_TsrAddinfo_Disp 500;
BA_REL_ "GenSigTimeoutTime" BU_SG_REL_ H_U SG_ 343 CF_Lkas_TsrSpeed_Display 500;
BA_REL_ "GenSigTimeoutTime" BU_SG_REL_ AMP SG_ 75 AMP_EngOrderC2GainSet 0;
BA_REL_ "GenSigTimeoutTime" BU_SG_REL_ AMP SG_ 75 AMP_EngOrderC4GainSet 0;
BA_REL_ "GenSigTimeoutTime" BU_SG_REL_ AMP SG_ 75 AMP_EngOrderC6GainSet 0;
BA_REL_ "GenSigTimeoutTime" BU_SG_REL_ AMP SG_ 75 AMP_APSBand0GainSet 0;
BA_REL_ "GenSigTimeoutTime" BU_SG_REL_ AMP SG_ 75 AMP_APSBand1GainSet 0;
BA_REL_ "GenSigTimeoutTime" BU_SG_REL_ AMP SG_ 75 AMP_APSBand2GainSet 0;
BA_REL_ "GenSigTimeoutTime" BU_SG_REL_ AMP SG_ 75 AMP_APSBand3GainSet 0;
BA_REL_ "GenSigTimeoutTime" BU_SG_REL_ AMP SG_ 75 AMP_APSBand4GainSet 0;
BA_REL_ "GenSigTimeoutTime" BU_SG_REL_ AMP SG_ 74 AMP_PESSMode 0;
BA_REL_ "GenSigTimeoutTime" BU_SG_REL_ AMP SG_ 74 AMP_PESSDesignSet 0;
BA_REL_ "GenSigTimeoutTime" BU_SG_REL_ AMP SG_ 74 AMP_PESSAPSSet 0;
BA_REL_ "GenSigTimeoutTime" BU_SG_REL_ AMP SG_ 74 AMP_PESSVolumeSet 0;
BA_REL_ "GenSigTimeoutTime" BU_SG_REL_ EDT SG_ 1864 Byte0_TCP_748 0;
BA_REL_ "GenSigTimeoutTime" BU_SG_REL_ EDT SG_ 1864 Byte1_Data_748 0;
BA_REL_ "GenSigTimeoutTime" BU_SG_REL_ EDT SG_ 1864 Byte2_Data_748 0;
BA_REL_ "GenSigTimeoutTime" BU_SG_REL_ EDT SG_ 1864 Byte3_Data_748 0;
BA_REL_ "GenSigTimeoutTime" BU_SG_REL_ EDT SG_ 1864 Byte4_Data_748 0;
BA_REL_ "GenSigTimeoutTime" BU_SG_REL_ EDT SG_ 1864 Byte5_Data_748 0;
BA_REL_ "GenSigTimeoutTime" BU_SG_REL_ EDT SG_ 1864 Byte6_Data_748 0;
BA_REL_ "GenSigTimeoutTime" BU_SG_REL_ EDT SG_ 1864 Byte7_Data_748 0;
BA_REL_ "GenSigTimeoutTime" BU_SG_REL_ H_U SG_ 326 TMU_CallStatus 3500;
BA_REL_ "GenSigTimeoutTime" BU_SG_REL_ H_U SG_ 326 TMU_CallType 3500;
BA_REL_ "GenSigTimeoutTime" BU_SG_REL_ H_U SG_ 326 TMU_CDMA_Streng 3500;
BA_REL_ "GenSigTimeoutTime" BU_SG_REL_ H_U SG_ 326 TMU_PacketStatus 3500;
BA_REL_ "GenSigTimeoutTime" BU_SG_REL_ H_U SG_ 326 TMU_TalkTimeHour 3500;
BA_REL_ "GenSigTimeoutTime" BU_SG_REL_ H_U SG_ 326 TMU_TalkTimeMinute 3500;
BA_REL_ "GenSigTimeoutTime" BU_SG_REL_ H_U SG_ 326 TMU_TalkTimeSecond 3500;
BA_REL_ "GenSigTimeoutTime" BU_SG_REL_ H_U SG_ 69 TMU_eCall 0;
BA_REL_ "GenSigTimeoutTime" BU_SG_REL_ CGW SG_ 67 C_ReqDrLock 0;
BA_REL_ "GenSigTimeoutTime" BU_SG_REL_ CLU SG_ 67 C_ReqDrLock 0;
BA_REL_ "GenSigTimeoutTime" BU_SG_REL_ DATC SG_ 67 C_ReqDrLock 0;
BA_REL_ "GenSigTimeoutTime" BU_SG_REL_ IPM SG_ 67 C_ReqDrLock 0;
BA_REL_ "GenSigTimeoutTime" BU_SG_REL_ CGW SG_ 67 C_ReqDrUnlock 0;
BA_REL_ "GenSigTimeoutTime" BU_SG_REL_ CLU SG_ 67 C_ReqDrUnlock 0;
BA_REL_ "GenSigTimeoutTime" BU_SG_REL_ DATC SG_ 67 C_ReqDrUnlock 0;
BA_REL_ "GenSigTimeoutTime" BU_SG_REL_ IPM SG_ 67 C_ReqDrUnlock 0;
BA_REL_ "GenSigTimeoutTime" BU_SG_REL_ CGW SG_ 67 C_ReqHazard 0;
BA_REL_ "GenSigTimeoutTime" BU_SG_REL_ CLU SG_ 67 C_ReqHazard 0;
BA_REL_ "GenSigTimeoutTime" BU_SG_REL_ DATC SG_ 67 C_ReqHazard 0;
BA_REL_ "GenSigTimeoutTime" BU_SG_REL_ IPM SG_ 67 C_ReqHazard 0;
BA_REL_ "GenSigTimeoutTime" BU_SG_REL_ CGW SG_ 67 C_ReqHorn 0;
BA_REL_ "GenSigTimeoutTime" BU_SG_REL_ CLU SG_ 67 C_ReqHorn 0;
BA_REL_ "GenSigTimeoutTime" BU_SG_REL_ DATC SG_ 67 C_ReqHorn 0;
BA_REL_ "GenSigTimeoutTime" BU_SG_REL_ IPM SG_ 67 C_ReqHorn 0;
BA_REL_ "GenSigTimeoutTime" BU_SG_REL_ CGW SG_ 67 C_ReqEngineOperate 0;
BA_REL_ "GenSigTimeoutTime" BU_SG_REL_ CLU SG_ 67 C_ReqEngineOperate 0;
BA_REL_ "GenSigTimeoutTime" BU_SG_REL_ DATC SG_ 67 C_ReqEngineOperate 0;
BA_REL_ "GenSigTimeoutTime" BU_SG_REL_ IPM SG_ 67 C_ReqEngineOperate 0;
BA_REL_ "GenSigTimeoutTime" BU_SG_REL_ H_U SG_ 66 CDMA_SelfDiag 0;
BA_REL_ "GenSigTimeoutTime" BU_SG_REL_ H_U SG_ 66 CDMA_Antena_SelfDiag 0;
BA_REL_ "GenSigTimeoutTime" BU_SG_REL_ H_U SG_ 1345 TMU_SupVoiceTextService 3500;
BA_REL_ "GenSigTimeoutTime" BU_SG_REL_ H_U SG_ 1345 TMU_SupEcoCoachService 3500;
BA_REL_ "GenSigTimeoutTime" BU_SG_REL_ H_U SG_ 1345 TMU_SupSongTagService 3500;
BA_REL_ "GenSigTimeoutTime" BU_SG_REL_ H_U SG_ 1345 TMU_SupContentService 3500;
BA_REL_ "GenSigTimeoutTime" BU_SG_REL_ H_U SG_ 1345 TMU_MajorVersion 3500;
BA_REL_ "GenSigTimeoutTime" BU_SG_REL_ H_U SG_ 1345 TMU_MinorVersion 3500;
BA_REL_ "GenSigTimeoutTime" BU_SG_REL_ H_U SG_ 1345 TMU_DistributeInfo 3500;
BA_REL_ "GenSigTimeoutTime" BU_SG_REL_ H_U SG_ 65 TMU_BarLevel1 0;
BA_REL_ "GenSigTimeoutTime" BU_SG_REL_ H_U SG_ 65 TMU_BarLevel2 0;
BA_REL_ "GenSigTimeoutTime" BU_SG_REL_ H_U SG_ 65 TMU_BarLevel4 0;
BA_REL_ "GenSigTimeoutTime" BU_SG_REL_ H_U SG_ 65 TMU_BarLevel3 0;
BA_REL_ "GenSigTimeoutTime" BU_SG_REL_ H_U SG_ 65 TMU_BarLevel5 0;
BA_REL_ "GenSigTimeoutTime" BU_SG_REL_ H_U SG_ 65 TMU_BarLevel6 0;
BA_REL_ "GenSigTimeoutTime" BU_SG_REL_ H_U SG_ 65 TMU_BarLevel8 0;
BA_REL_ "GenSigTimeoutTime" BU_SG_REL_ H_U SG_ 65 TMU_BarLevel7 0;
BA_REL_ "GenSigTimeoutTime" BU_SG_REL_ H_U SG_ 65 TMU_BarLevel9 0;
BA_REL_ "GenSigTimeoutTime" BU_SG_REL_ H_U SG_ 65 TMU_BarLevel10 0;
BA_REL_ "GenSigTimeoutTime" BU_SG_REL_ H_U SG_ 1344 TMU_Arrow 3500;
BA_REL_ "GenSigTimeoutTime" BU_SG_REL_ H_U SG_ 1344 TMU_ReFill_Info 3500;
BA_REL_ "GenSigTimeoutTime" BU_SG_REL_ H_U SG_ 1344 TMU_AverageMPG 3500;
BA_REL_ "GenSigTimeoutTime" BU_SG_REL_ H_U SG_ 1344 TMU_TotalMPG 3500;
BA_REL_ "GenSigTimeoutTime" BU_SG_REL_ H_U SG_ 1344 TMU_RewardStar 3500;
BA_REL_ "GenSigTimeoutTime" BU_SG_REL_ H_U SG_ 64 TMU_DisMode 0;
BA_REL_ "GenSigTimeoutTime" BU_SG_REL_ CLU SG_ 64 TMU_AudSrcType 0;
BA_REL_ "GenSigTimeoutTime" BU_SG_REL_ DATC SG_ 64 TMU_AudSrcType 0;
BA_REL_ "GenSigTimeoutTime" BU_SG_REL_ H_U SG_ 64 TMU_AudSrcType 0;
BA_REL_ "GenSigTimeoutTime" BU_SG_REL_ H_U SG_ 64 TMU_AudReqCmd 0;
BA_REL_ "GenSigTimeoutTime" BU_SG_REL_ H_U SG_ 64 TMU_LangCmd 0;
BA_REL_ "GenSigTimeoutTime" BU_SG_REL_ H_U SG_ 64 TMU_ServReq 0;
BA_REL_ "GenSigTimeoutTime" BU_SG_REL_ H_U SG_ 64 TMU_ErrorEvent 0;
BA_REL_ "GenSigTimeoutTime" BU_SG_REL_ H_U SG_ 64 TMU_BeepCmd 0;
BA_REL_ "GenSigTimeoutTime" BU_SG_REL_ H_U SG_ 64 TMU_eCall 0;
VAL_ 139 AMP_Beep2VolumeState 254 "Invalid" 255 "Invalid" ;
VAL_ 139 AMP_Beep2FrequencyState 65535 "Invalid" ;
VAL_ 139 AMP_Beep2OutputMaskState 65535 "Invalid" ;
VAL_ 139 AMP_Beep2DOnState 255 "Invalid" ;
VAL_ 139 AMP_Beep2DOffState 255 "Invalid" ;
VAL_ 139 AMP_Beep2NOfCycleState 255 "Invalid" ;
VAL_ 138 AMP_Beep1VolumeState 254 "Invalid" 255 "Invalid" ;
VAL_ 138 AMP_Beep1FrequencyState 65535 "Invalid" ;
VAL_ 138 AMP_Beep1OutputMaskState 65535 "Invalid" ;
VAL_ 138 AMP_Beep1DOnState 255 "Invalid" ;
VAL_ 138 AMP_Beep1DOffState 255 "Invalid" ;
VAL_ 138 AMP_Beep1NOfCycleState 255 "Invalid" ;
VAL_ 137 AMP_MTSOutputMaskSupport 0 "Null" 1 "False" 2 "True" 3 "Invalid" ;
VAL_ 137 AMP_MTSMuteMaskSupport 0 "Null" 1 "False" 2 "True" 3 "Invalid" ;
VAL_ 137 AMP_HFOutputMaskSupport 0 "Null" 1 "False" 2 "True" 3 "Invalid" ;
VAL_ 137 AMP_HFMuteMaskSupport 0 "Null" 1 "False" 2 "True" 3 "Invalid" ;
VAL_ 137 AMP_NaviOutputMaskSupport 0 "Null" 1 "False" 2 "True" 3 "Invalid" ;
VAL_ 137 AMP_NaviMuteMaskSupport 0 "Null" 1 "False" 2 "True" 3 "Invalid" ;
VAL_ 136 AMP_MaxBeep2VolumeState 255 "Invalid" ;
VAL_ 136 AMP_MaxBeep2Freq_State 65535 "Invalid" ;
VAL_ 136 AMP_Beep2OutputMaskSup 0 "Null" 1 "False" 2 "True" 3 "Invalid" ;
VAL_ 136 AMP_MaxBeep2DOnState 255 "Invalid" ;
VAL_ 136 AMP_MaxBeep2DOffState 255 "Invalid" ;
VAL_ 136 AMP_MaxBeep2NOfCycleState 255 "invalid" ;
VAL_ 135 AMP_MaxBeep1VolumeState 255 "Invalid" ;
VAL_ 135 AMP_MaxBeep1Freq_State 65535 "Invalid" ;
VAL_ 135 AMP_Beep1OutputMaskSup 0 "Null" 1 "False" 2 "True" 3 "Invalid" ;
VAL_ 135 AMP_MaxBeep1DOnState 255 "Invalid" ;
VAL_ 135 AMP_MaxBeep1DOffState 255 "invalid" ;
VAL_ 135 AMP_MaxBeep1NOfCycleState 255 "invalid" ;
VAL_ 134 ASD_SetValue 0 "Not Used" 1 "Off" 2 "Quite" 3 "Sport" 4 "reserved" 5 "reserved" 6 "reserved" 7 "Invalid" ;
VAL_ 134 ASD_Version 255 "Invalid" ;
VAL_ 133 AMP_MaxVolumeStep 254 "Invalid" 255 "Invalid" ;
VAL_ 133 AMP_MaxBalanceStep 254 "Invalid" 255 "Invalid" ;
VAL_ 133 AMP_MaxFadeStep 254 "Invalid" 255 "Invalid" ;
VAL_ 133 AMP_MaxBassStep 254 "Invalid" 255 "Invalid" ;
VAL_ 133 AMP_MaxMidStep 254 "Invalid" 255 "Invalid" ;
VAL_ 133 AMP_MaxTrebleStep 254 "Invalid" 255 "Invalid" ;
VAL_ 133 AMP_ASDMajorVer 255 "Invalid" ;
VAL_ 133 AMP_ASDMinorVer 255 "Invalid" ;
VAL_ 389 AMP_EngOrderC2Setting 0 "Min Value" 1 "Values" 2 "Values" 3 "Values" 4 "Values" 5 "Values" 6 "Values" 7 "Values" 8 "Values" 9 "Values" 10 "Values" 11 "Values" 12 "Values" 13 "Values" 14 "Values" 15 "Values" 16 "Values" 17 "Values" 18 "Values" 19 "Values" 20 "Values" 21 "Values" 22 "Values" 23 "Values" 24 "Max Value" 255 "Invalid" ;
VAL_ 389 AMP_EngOrderC4Setting 0 "Min Value" 1 "Values" 2 "Values" 3 "Values" 4 "Values" 5 "Values" 6 "Values" 7 "Values" 8 "Values" 9 "Values" 10 "Values" 11 "Values" 12 "Values" 13 "Values" 14 "Values" 15 "Values" 16 "Values" 17 "Values" 18 "Values" 19 "Values" 20 "Values" 21 "Values" 22 "Values" 23 "Values" 24 "Max Value" 255 "Invalid" ;
VAL_ 389 AMP_EngOrderC6Setting 0 "Min Value" 1 "Values" 2 "Values" 3 "Values" 4 "Values" 5 "Values" 6 "Values" 7 "Values" 8 "Values" 9 "Values" 10 "Values" 11 "Values" 12 "Values" 13 "Values" 14 "Values" 15 "Values" 16 "Values" 17 "Values" 18 "Values" 19 "Values" 20 "Values" 21 "Values" 22 "Values" 23 "Values" 24 "Max Value" 255 "Invalid" ;
VAL_ 389 AMP_APSBand0Setting 0 "Min Value" 1 "Values" 2 "Values" 3 "Values" 4 "Values" 5 "Values" 6 "Values" 7 "Values" 8 "Values" 9 "Values" 10 "Values" 11 "Values" 12 "Values" 13 "Values" 14 "Values" 15 "Values" 16 "Values" 17 "Values" 18 "Values" 19 "Values" 20 "Values" 21 "Values" 22 "Values" 23 "Values" 24 "Max Value" 255 "Invalid" ;
VAL_ 389 AMP_APSBand1Setting 0 "Min Value" 1 "Values" 2 "Values" 3 "Values" 4 "Values" 5 "Values" 6 "Values" 7 "Values" 8 "Values" 9 "Values" 10 "Values" 11 "Values" 12 "Values" 13 "Values" 14 "Values" 15 "Values" 16 "Values" 17 "Values" 18 "Values" 19 "Values" 20 "Values" 21 "Values" 22 "Values" 23 "Values" 24 "Max Value" 255 "Invalid" ;
VAL_ 389 AMP_APSBand2Setting 0 "Min Value" 1 "Values" 2 "Values" 3 "Values" 4 "Values" 5 "Values" 6 "Values" 7 "Values" 8 "Values" 9 "Values" 10 "Values" 11 "Values" 12 "Values" 13 "Values" 14 "Values" 15 "Values" 16 "Values" 17 "Values" 18 "Values" 19 "Values" 20 "Values" 21 "Values" 22 "Values" 23 "Values" 24 "Max Value" 255 "Invalid" ;
VAL_ 389 AMP_APSBand3Setting 0 "Min Value" 1 "Values" 2 "Values" 3 "Values" 4 "Values" 5 "Values" 6 "Values" 7 "Values" 8 "Values" 9 "Values" 10 "Values" 11 "Values" 12 "Values" 13 "Values" 14 "Values" 15 "Values" 16 "Values" 17 "Values" 18 "Values" 19 "Values" 20 "Values" 21 "Values" 22 "Values" 23 "Values" 24 "Max Value" 255 "Invalid" ;
VAL_ 389 AMP_APSBand4Setting 0 "Min Value" 1 "Values" 2 "Values" 3 "Values" 4 "Values" 5 "Values" 6 "Values" 7 "Values" 8 "Values" 9 "Values" 10 "Values" 11 "Values" 12 "Values" 13 "Values" 14 "Values" 15 "Values" 16 "Values" 17 "Values" 18 "Values" 19 "Values" 20 "Values" 21 "Values" 22 "Values" 23 "Values" 24 "Max Value" 255 "Invalid" ;
VAL_ 132 AMP_HFVolumeState 254 "Invalid" 255 "Invalid" ;
VAL_ 132 AMP_HFAudioCutState 254 "Invalid" 255 "Invalid" ;
VAL_ 132 AMP_HFOutputMaskState 65535 "Invalid" ;
VAL_ 132 AMP_HFMuteMaskState 65535 "Invalid" ;
VAL_ 132 AMP_MaxHFVolumeState 254 "Invalid" 255 "Invalid" ;
VAL_ 132 AMP_MaxHFAudioCutState 254 "Invalid" 255 "Invalid" ;
VAL_ 388 AMP_PESSModeState 0 "PESS Off" 1 "PESS On (Default)" 2 "Reserved" 3 "Invalid" ;
VAL_ 388 AMP_PESSDesignSetting 0 "Type 0 (Default)" 1 "Type 1" 2 "Type 2" 3 "Reserved" 4 "Reserved" 5 "Reserved" 6 "Reserved" 7 "Invalid" ;
VAL_ 388 AMP_PESSAPSSetting 0 "Type 0" 1 "Type 1" 2 "Type 2 (Default)" 3 "Type 3" 4 "Type 4" 5 "Reserved" 6 "Reserved" 7 "Invalid" ;
VAL_ 388 AMP_PESSVolumeSetting 0 "Min Value" 1 "values" 2 "values" 3 "values" 4 "values" 5 "values" 6 "values" 7 "values" 8 "values" 9 "values" 10 "values" 11 "values" 12 "values" 13 "values" 14 "values" 15 "values" 16 "values" 17 "values" 18 "values" 19 "values" 20 "values" 21 "Max Value" 255 "Invalid" ;
VAL_ 131 AMP_MTSVolumeState 254 "Invalid" 255 "Invalid" ;
VAL_ 131 AMP_MTSAudioCutState 254 "Invalid" 255 "Invalid" ;
VAL_ 131 AMP_MTSOutputMaskState 65535 "Invalid" ;
VAL_ 131 AMP_MTSMuteMaskState 65535 "Invalid" ;
VAL_ 131 AMP_MaxMTSVolumeState 254 "Invalid" 255 "Invalid" ;
VAL_ 131 AMP_MaxMTSAudioCutState 254 "Invalid" 255 "Invalid" ;
VAL_ 387 AMP_MainVolumeSetting 254 "Invalid" 255 "Invalid" ;
VAL_ 387 AMP_BalanceSetting 255 "Invalid" ;
VAL_ 387 AMP_FadeSetting 255 "Invalid" ;
VAL_ 387 AMP_BassSetting 255 "Invalid" ;
VAL_ 387 AMP_MidSetting 255 "Invalid" ;
VAL_ 387 AMP_TrebleSetting 255 "Invalid" ;
VAL_ 387 AMP_VehicleSpeedamp 255 "Invalid" ;
VAL_ 130 AMP_NaviVolumeState 254 "Invalid" 255 "Invalid" ;
VAL_ 130 AMP_NaviAudioCutState 254 "Invalid" 255 "Invalid" ;
VAL_ 130 AMP_NaviOutputMaskState 65535 "Invalid" ;
VAL_ 130 AMP_NaviMuteMaskState 65535 "Invalid" ;
VAL_ 130 AMP_MaxNaviVolumeState 254 "Invalid" 255 "Invalid" ;
VAL_ 130 AMP_MaxNaviAudioCutState 254 "Invalid" 255 "Invalid" ;
VAL_ 129 AMP_DriveState 0 "Null" 1 "LHD" 2 "RHD" 3 "Invalid" ;
VAL_ 129 AMP_ConvertibleTopState 0 "Null" 1 "UP" 2 "down" 3 "Invalid" ;
VAL_ 385 AMP_MuteState 0 "Not mute" 1 "mute" 2 "Unsed" 3 "Invalid" ;
VAL_ 385 AMP_RearSpMuteState 0 "Not mute" 1 "mute" 2 "Unsed" 3 "Invalid" ;
VAL_ 385 AMP_SurroundModeState 0 "Surround mode off" 1 "Surround mode On" 2 "Unused" 3 "Invalid" ;
VAL_ 385 AMP_EQState 0 "null" 1 "EQ Active" 2 "EQ loading" 3 "invalid" ;
VAL_ 385 AMP_SPDIFMuteSt 0 "SPDIF Un- Mutef" 1 "SPDIF Mute On" 2 "Unused" 3 "Invalid" ;
VAL_ 385 AMP_BeatsModeState 0 "Beats Off" 1 "Beats On" 2 "Reserved" 3 "Invalid" ;
VAL_ 385 AMP_DefaultBeep1St 0 "Default beep1 off" 1 "default beep1 on" 2 "double beePon" 3 "invalid" ;
VAL_ 385 AMP_DefaultBeep2St 0 "Default beep1 off" 1 "default beep1 on" 2 "unused" 3 "invalid" ;
VAL_ 385 AMP_AudioSource 0 "Off" 1 "AM" 2 "FM" 3 "Reserved" 4 "XM_SIRIUS" 5 "DMB(South Korea Only)" 6 "Reserved" 7 "Reserved" 8 "Reserved" 9 "Reserved" 10 "Reserved" 11 "Reserved" 12 "Reserved" 13 "Reserved" 14 "Reserved" 15 "Reserved" 16 "CD(CDDA_MP3)" 17 "DVD DD" 18 "DVD DTS" 19 "RSE CD_MP3_VCD" 20 "RSE DD" 21 "RSE DTS" 22 "Reserved" 23 "Reserved" 24 "Reserved" 25 "Reserved" 26 "Reserved" 27 "Reserved" 28 "Reserved" 29 "Reserved" 30 "Reserved" 31 "Reserved" 32 "USB MP3" 33 "BT MP3" 34 "iPod" 35 "AUX" 36 "RSE AUX" 37 "HF(SPDIF)" 38 "MTS(SPDIF)" 39 "MTS(analog)" 40 "ZUNE" 255 "Invalid" ;
VAL_ 385 AMP_VIPModeState 0 "VIP mode OFF" 1 "VIP mode ON" 2 "Reserved" 3 "Invalid" ;
VAL_ 385 AMP_QLSModeState 0 "QLS OFF" 1 "On Stage" 2 "Audience" 3 "Invalid" ;
VAL_ 128 AMP_CurrentVehicleID 255 "Invalid" ;
VAL_ 128 AMP_SPDIFModeState 0 "SPDIF Loading" 1 "Two Channel Audio" 2 "Four Channel Audio" 3 "DD" 4 "DTS" 5 "Unused" 6 "Unused" 7 "Unused" 8 "Unused" 9 "Unused" 10 "Unused" 11 "Unused" 12 "Unused" 13 "Unused" 14 "Unused" 15 "Invalid" ;
VAL_ 128 AMP_MajorVer 255 "Invalid" ;
VAL_ 128 AMP_MinorVer 255 "Invalid" ;
VAL_ 128 AMP_UpdateStartResp 0 "No update start" 1 "Update start" 2 "Unused" 3 "Invalid" ;
VAL_ 128 AMP_UpdateEndResp 0 "No update  end" 1 "Update end" 2 "Unused" 3 "Invalid" ;
VAL_ 128 AMP_TuningMajorVer 255 "Invalid" ;
VAL_ 128 AMP_TuningMinorVer 255 "Invalid" ;
VAL_ 384 AMP_HFModeState 0 "Phone Off" 1 "Phone ON" 2 "Unused" 3 "Invalid" ;
VAL_ 384 HU_InitInfo 0 "Not used" 1 "Init_request" 2 "Init_completed" 3 "Invalid" ;
VAL_ 384 AMP_ASDModeState 0 "Not use" 1 "Off" 2 "Quite" 3 "Sport" 4 "Reserved" 5 "Reserved" 6 "Reserved" 7 "Invalid" ;
VAL_ 384 AMP_NaviModeState 0 "Navi Off" 1 "Navi ON" 2 "Unused" 3 "Invalid" ;
VAL_ 384 AMP_SPDIFInfo 0 "Not used" 1 "Unlock" 2 "Null" 3 "PCM" 4 "Compressed" 5 "Reserved" 6 "Reserved" 7 "Invalid" ;
VAL_ 384 AMP_MTSModeState 0 "MTS Off" 1 "MTS ON" 2 "Unused" 3 "InValid" ;
VAL_ 384 AMP_VSCModeState 0 "Speed gain mode Off" 1 "Speed gain mode On" 2 "state of SDVC 4 StePControl" 3 "Invalid" ;
VAL_ 384 AMP_SDVCStepState 0 "off" 1 "low" 2 "mid" 3 "high" 7 "Invalid" ;
VAL_ 384 AMP_Beep1ModeState 0 "Beep1 mode off" 1 "Beep1 mode On" 2 "Unsed" 3 "InValid" ;
VAL_ 384 AMP_Beep2ModeState 0 "BeeP2 mode off" 1 "BeeP2 mode On" 2 "Unsed" 3 "Invalid" ;
VAL_ 384 AMP_DistrInfoState 255 "Invalid" ;
VAL_ 384 AMP_INFORM_TO_IPM 0 "off" 1 "AMP_INFORM" 2 "Reserved" 3 "Invalid" ;
VAL_ 384 AMP_SignalDoctorState 0 "SignalDoctor OFF" 1 "SignalDoctor ON" 2 "Unused" 3 "Invalid" ;
VAL_ 384 AMP_AutoVolumeState 0 "AutoVolume OFF" 1 "AutoVolume ON" 2 "Unused" 3 "Invalid" ;
VAL_ 1408 AMP_SupportMute 0 "Null" 1 "False" 2 "True" 3 "Invalid" ;
VAL_ 1408 AMP_SupportHFMode 0 "Null" 1 "False" 2 "True" 3 "Invalid" ;
VAL_ 1408 AMP_SupportCfgBeep1 0 "Null" 1 "False" 2 "True" 3 "Invalid" ;
VAL_ 1408 AMP_SupportCfgBeep2 0 "Null" 1 "False" 2 "True" 3 "Invalid" ;
VAL_ 1408 AMP_SupportSpeedAdjust 0 "Null" 1 "False" 2 "True" 3 "Invalid" ;
VAL_ 1408 AMP_SupportSurroundMode 0 "Null" 1 "False" 2 "True" 3 "Invalid" ;
VAL_ 1408 AMP_SupportNaviMode 0 "Null" 1 "False" 2 "True" 3 "Invalid" ;
VAL_ 1408 AMP_SupportMTSMode 0 "Null" 1 "False" 2 "True" 3 "Invalid" ;
VAL_ 1408 AMP_SupportTopState 0 "Null" 1 "False" 2 "True" 3 "Invalid" ;
VAL_ 1408 AMP_SupportBothLHDandRHD 0 "Null" 1 "False" 2 "True" 3 "Invalid" ;
VAL_ 1408 AMP_SupportEQState 0 "Null" 1 "False" 2 "True" 3 "Invalid" ;
VAL_ 1408 AMP_SupportVehicleID 0 "Null" 1 "False" 2 "True" 3 "Invalid" ;
VAL_ 1408 AMP_SupportAudioSource 0 "Null" 1 "False" 2 "True" 3 "Invalid" ;
VAL_ 1408 AMP_SupportSPDIFModeState 0 "Null" 1 "False" 2 "True" 3 "Invalid" ;
VAL_ 1408 AMP_SupportRearSpMute 0 "Null" 1 "False" 2 "True" 3 "Invalid" ;
VAL_ 1408 AMP_SupportVEQMode 0 "Null" 1 "False" 2 "True" 3 "Invalid" ;
VAL_ 1408 AMP_MakerID 0 "Initial Value" 171 "Harman_Becker" 250 "MOBIS" 251 "Beats by Dr.Dre" 255 "Invalid" 1 "Mobis" 2 "Beats by Dr.Dre" 3 "Harman_Becker" ;
VAL_ 1408 AMP_SupportASDMode 0 "Null" 1 "False" 2 "True" 3 "Invalid" ;
VAL_ 1408 AMP_SupportBeatsMode 0 "Null" 1 "False" 2 "True" 3 "Invalid" ;
VAL_ 1408 AMP_SupportVIPMode 0 "Null" 1 "False" 2 "True" 3 "Invalid" ;
VAL_ 1408 AMP_SupportQLS 0 "Null" 1 "False" 2 "True" 3 "Invalid" ;
VAL_ 1408 AMP_SupportSignalDoctor 0 "Null" 1 "False" 2 "True" 3 "Invalid" ;
VAL_ 1408 AMP_SupportAutoVolume 0 "Null" 1 "False" 2 "True" 3 "Invalid" ;
VAL_ 1408 AMP_SupportPESSMode 0 "Null" 1 "False(default)" 2 "True" 3 "Invalid" ;
VAL_ 371 HU_AliveStatus 0 "Not Ready" 1 "On Mode" 2 "Head Unit Update Mode" 3 "Invalid" ;
VAL_ 371 HU_DeviceType 0 "Audio Head Unit(A-Type)" 1 "Audio Head Unit(B-Type)" 2 "Audio Head Unit(C-Type)" 3 "AV Head Unit" 4 "AVN" 5 "AVN 3.0" 6 "Reserved" 7 "Reserved" 8 "Reserved" 9 "Reserved" 10 "Reserved" 11 "Reserved" 12 "Reserved" 13 "Reserved" 14 "Reserved" 15 "Invalid" ;
VAL_ 371 HU_DistanceUnit 0 "Km" 1 "Mile" 2 "Reserved" 3 "Invalid" ;
VAL_ 371 HU_AudAllocStatus 0 "TMU Audio is not allocated" 1 "TMU Audio is allocated" 2 "Reject (Audio Only)" 3 "Invalid" ;
VAL_ 371 HU_PowerStatus 0 "Power Off, Display Off" 1 "Power Off, Display On" 2 "Power On, Display Off" 3 "Power On, Display On" 4 "Reserved" 5 "Reserved" 6 "Reserved" 7 "Invalid" ;
VAL_ 371 HU_BTCallStatus 0 "Not Used or call is disconnected" 1 "Incoming BT Phone Call" 2 "Outgoing BT Phone Call" 3 "Active BT Call" 4 "Reserved" 5 "Reserved" 6 "Reserved" 7 "Invalid" ;
VAL_ 371 HU_VoiceRecStatus 0 "No VR" 1 "VR is listening" 2 "VR is speaking" 3 "Invalid" ;
VAL_ 371 HU_LangStatus 0 "No Action" 1 "English" 2 "French" 3 "Spanish" 4 "Reserved" 5 "Reserved" 6 "Reserved" 7 "Invalid" ;
VAL_ 369 HU_VehiclePwr 0 "Key out or Audio OFF" 1 "Not used" 2 "ACC or Audio ON" 3 "Not used" 4 "Not used" 5 "Not used" 6 "Not used" 7 "Not used" 8 "Not used" 9 "Not used" 10 "Not used" 11 "Not used" 12 "Not used" 13 "Not used" 14 "Not used" 15 "Invalid" ;
VAL_ 112 AMP_Beep1VolumeStep 254 "Req.amp. Beep1 settings" 255 "Invalid" ;
VAL_ 112 AMP_Beep1Frequency 65535 "Invalid" ;
VAL_ 112 AMP_Beep1Ch_OutputMask 65535 "Invalid" ;
VAL_ 112 AMP_Beep1DurationOn 255 "Invalid" ;
VAL_ 112 AMP_Beep1DurationOff 255 "Invalid" ;
VAL_ 112 AMP_Beep1NumberOfCycles 255 "Invalid" ;
VAL_ 1390 C_VehicleSpeed 255 "Invalid" ;
VAL_ 1390 C_Odometer 16777215 "Invalid" ;
VAL_ 363 C_DRVUnlockState 0 "Lock" 1 "Unlock" 2 "Reserved" 3 "invalid" ;
VAL_ 363 C_ASTUnlockState 0 "Lock" 1 "Unlock" 2 "Reserved" 3 "invalid" ;
VAL_ 363 C_RLUnlockstate 0 "Lock" 1 "Unlock" 2 "Reserved" 3 "invalid" ;
VAL_ 363 C_RRUnlockState 0 "Lock" 1 "Unlock" 2 "Reserved" 3 "invalid" ;
VAL_ 363 C_VehicleInfoTMU 0 "Off" 1 "Alarm" 2 "Unlock" 3 "Panic" ;
VAL_ 363 C_Engine_Status 0 "Default" 1 "Cranking" 2 "stop" 3 "Invalid" ;
VAL_ 363 C_TMULockFeedBack 0 "Default" 1 "Any Door Unlock or Any Door Open" 2 "All Door Lock and All Door Close" 3 "Invalid" ;
VAL_ 362 C_AV_Tail 0 "Default" 1 "Deactived" 2 "Actived" 3 "Invalid" ;
VAL_ 362 C_ParkingBrakeSW 0 "Off" 1 "On" 2 "not used" 3 "Invalid" ;
VAL_ 362 C_RKECMD 0 "None" 1 "Lock_No1" 2 "Unlock_ No1" 3 "Lock_No2" 4 "Unlock_ No2" 5 "Lock_ No3" 6 "Unlock_No3" 7 "Lock_ No4" 8 "Unlock_No4" 9 "Lock" 10 "Unlock" 15 "invalid" ;
VAL_ 362 C_BAState 0 "Default" 1 "Deactived" 2 "Actived" 3 "Invalid" ;
VAL_ 362 C_IGNSW 0 "KeyOff" 1 "KeyIn" 2 "ACC" 3 "IGN" 4 "Start" 7 "Invalid" ;
VAL_ 362 C_CountryCfg 0 "DOM" 1 "NA" 2 "EU" 3 "AUS" 4 "CHINA" 5 "GEN, MES" ;
VAL_ 362 C_AltL 0 "Off" 1 "On" 2 "Not used" 3 "Invalid" ;
VAL_ 362 C_TailLampActivity 0 "Default" 1 "OFF" 2 "ON" 3 "Invalid" ;
VAL_ 362 RearSW_RSELockOnOff 0 "Off" 1 "LockOn" 2 "reserved" 3 "Invalid" ;
VAL_ 362 C_TMULockFeedBack 0 "Default" 1 "Any Door Unlock and Any Door Open" 2 "All Door Lock and All Door Close" 3 "Invalid" ;
VAL_ 362 C_SMKTeleCrankingState 0 "Default" 1 "Off" 2 "On" 3 "Invalid" ;
VAL_ 362 C_SMKTeleCrankingFailRes 3 "Invalid" ;
VAL_ 362 C_RKECMD_GEN2 0 "None" 1 "Lock" 2 "Unlock" 3 "Panic" 4 "Panic Stop" 5 "Trunk(Or Tail Gate)" 6 "Reserved" 7 "Invalid" ;
VAL_ 362 C_Acu_CshAct 0 "Crash Inactive" 1 "Crash Detected" 2 "reserved" 3 "invalid" ;
VAL_ 362 C_IntTailAct 0 "OFF" 1 "ON" 2 "reserved" 3 "Invalid" ;
VAL_ 362 C_PassiveAccessUnlock 0 "None" 1 "UnLock" 2 "Unlock only DRV Door" 3 "PIC_Key_Reminder" 4 "Reserved" 5 "Reserved" 6 "Reserved" 7 "Invalid" ;
VAL_ 362 Lca_IndLeft 0 "No warning alarm" 1 "reserved" 2 "2nd warning alarm" 3 "Invalid" ;
VAL_ 362 FL_SndWarn 0 "No warning alarm" 1 "reserved" 2 "2nd warning alarm" 3 "Invalid" ;
VAL_ 362 FR_SndWarn 0 "No warning alarm" 1 "reserved" 2 "2nd warning alarm" 3 "Invalid" ;
VAL_ 362 Lca_IndRight 0 "No warning alarm" 1 "reserved" 2 "2nd warning alarm" 3 "Invalid" ;
VAL_ 362 RCTA_IndLeft 0 "No Warning alarm" 1 "reserved" 2 "warning alarm" 3 "Invalid" ;
VAL_ 362 RL_SndWarn 0 "No warning alarm" 1 "reserved" 2 "warning alarm" 3 "Invalid" ;
VAL_ 362 RR_SndWarn 0 "No warning alarm" 1 "reserved" 2 "warning alarm" 3 "Invalid" ;
VAL_ 362 RCTA_IndRight 0 "No warning alarm" 1 "reserved" 2 "warning alarm" 3 "Invalid" ;
VAL_ 361 C_Inhibit_State 0 "P" 1 "L" 2 "2" 3 "3" 4 "DS Mode" 5 "D" 6 "N" 7 "R" 8 "SportsMode_ManualShift" 9 "NotDisplayAtCluster" 10 "Sub-RomCommunication" 11 "Sub-RomCommunicationError" 12 "PaddleShift(D-position)" 13 "None-EOL Data" 14 "IntermediatePosition" 15 "fault" ;
VAL_ 361 C_P_BrakeStatus 0 "Null" 1 "off" 2 "ON" 3 "Invalid" ;
VAL_ 361 C_Clu_AltLStatus 0 "Off" 1 "On" 2 "not used" 3 "Invalid" ;
VAL_ 359 Spas_BEEP_Alarm 0 "off" 1 "SPAS_PAS Failure alarm" 2 "Reserved" 3 "TGS R warning alarm" 4 "SPASparking.completewarnalarm" 5 "Reserved" 6 "Reserved" 7 "Reserved" 8 "Scan complete message warning" 9 "System abort message" 10 "Gear shift to Backward" 11 "Gear shift to Forward" 12 "Reserved" 13 "Reserved" 14 "Reserved" 15 "Invalid" ;
VAL_ 359 Spas_Audio_VolumeDown 0 "off" 1 "VolumeDown" 2 "Reserved" 3 "Invalid" ;
VAL_ 359 Spas_Spkr_Flh_Alarm 0 "off" 1 "1st waring" 2 "2nd warning" 3 "3rd warning" ;
VAL_ 359 Spas_Spkr_Fcnt_Alarm 0 "off" 1 "1st waring" 2 "2nd warning" 3 "3rd warning" ;
VAL_ 359 Spas_Spkr_Frh_Alarm 0 "off" 1 "1st waring" 2 "2nd warning" 3 "3rd warning" ;
VAL_ 359 Spas_Spkr_Rlh_Alarm 0 "off" 1 "1st waring" 2 "2nd warning" 3 "3rd warning" ;
VAL_ 359 Spas_Spkr_Rcnt_Alarm 0 "off" 1 "1st waring" 2 "2nd warning" 3 "3rd warning" ;
VAL_ 359 Spas_Spkr_Rrh_Alarm 0 "off" 1 "1st waring" 2 "2nd warning" 3 "3rd warning" ;
VAL_ 359 Lkas_SysStatus 0 "Reserved" 1 "Reserved" 2 "Heavy Rain" 3 "Out-of-Control" 4 "Hand off Warning" 5 "MDPS Failure" 6 "Sensor Failure" 7 "LKAS Failure" 8 "Hazard switch Unavailable" 9 "System Automatic Off" 10 "Reserved" 11 "Reserved" 12 "Reserved" 13 "Reserved" 14 "Reserved" 15 "invalid" ;
VAL_ 359 Lkas_LH_Warning 0 "No warning alarm" 1 "HAPTIC Warning and Display" 2 "LDWS Warning and Display" 3 "Invalid" ;
VAL_ 359 Lkas_RH_Warning 0 "No warning alarm" 1 "HAPTIC Warning and Display" 2 "LDWS Warning and Display" 3 "Invalid" ;
VAL_ 359 Spas_Spkr_Level 0 "Default" 1 "Level 1" 2 "Level 2" 3 "Level 3" 4 "Reserved" 5 "Reserved" 6 "Reserved" 7 "Invalid(Error Value)" ;
VAL_ 359 Lkas_Audio_VolumeDown 0 "off" 1 "VolumeDown" 2 "Reserved" 3 "Invalid" ;
VAL_ 359 Audio_VolumeDown 0 "Off" 1 "VolumeDown" 2 "reserved" 3 "Invalid" ;
VAL_ 359 Pas_BEEP_Alarm 0 "off" 1 "PAS Failure alarm" 2 "Reserved" 3 "Change to TGS R  alarm" 4 "Reserved" 5 "Reserved" 6 "Reserved" 7 "Reserved" 8 "Reserved" 9 "Reserved" 10 "Reserved" 11 "Reserved" 12 "Reserved" 13 "Reserved" 14 "Reserved" 15 "Invalid" ;
VAL_ 359 Pas_Audio_VolumeDown 0 "off" 1 "VolumeDown" 2 "Volume up" 3 "Invalid" ;
VAL_ 359 Pas_Spkr_Level 0 "Default" 1 "Level 1" 2 "Level 2" 3 "Level 3" 4 "Reserved" 5 "Reserved" 6 "Reserved" 7 "Invalid(Error Value)" ;
VAL_ 359 Pas_Spkr_Flh_Alarm 0 "off" 1 "1st waring" 2 "2nd warning" 3 "3rd warning" ;
VAL_ 359 Pas_Spkr_Fcnt_Alarm 0 "off" 1 "1st waring" 2 "2nd warning" 3 "3rd warning" ;
VAL_ 359 Pas_Spkr_Frh_Alarm 0 "off" 1 "1st waring" 2 "2nd warning" 3 "3rd warning" ;
VAL_ 359 Pas_Spkr_Rlh_Alarm 0 "off" 1 "1st waring" 2 "2nd warning" 3 "3rd warning" ;
VAL_ 359 Pas_Spkr_Rcnt_Alarm 0 "off" 1 "1st waring" 2 "2nd warning" 3 "3rd warning" ;
VAL_ 359 Pas_Spkr_Rrh_Alarm 0 "off" 1 "1st waring" 2 "2nd warning" 3 "3rd warning" ;
VAL_ 1376 HU_GPS_Signal2 255 "Invalid" ;
VAL_ 1376 HU_GPS_Signal3 0 "True" 1 "False" 2 "reserved" 3 "Invalid" ;
VAL_ 1376 HU_GPS_Signal4 0 "Normal" 1 "Open" 2 "Short" 3 "Unknown" 4 "GPS Module Error" 7 "Invalid" ;
VAL_ 93 DATC_SWVerMajor 255 "Invalid" ;
VAL_ 93 DATC_SWVerMinor 255 "Invalid" ;
VAL_ 93 DATC_CANVerMajor 255 "Invalid" ;
VAL_ 93 DATC_CANVerMinor 255 "Invalid" ;
VAL_ 344 C_InhibitP 0 "Off" 1 "On" 2 "reserved" 3 "Invalid" ;
VAL_ 344 C_InhibitR 0 "Off" 1 "On" 2 "reserved" 3 "Invalid" ;
VAL_ 344 C_InhibitN 0 "Off" 1 "On" 2 "reserved" 3 "Invalid" ;
VAL_ 344 C_InhibitD 0 "Off" 1 "On" 2 "reserved" 3 "Invalid" ;
VAL_ 344 C_P_BrakeStatus 0 "Off" 1 "On" 2 "reserved" 3 "Invalid" ;
VAL_ 344 C_Clu_AltLStatus 0 "Off" 1 "On" 2 "reserved" 3 "Invalid" ;
VAL_ 344 CF_Clu_LowfuelWarning 0 "Off" 1 "Warning" 2 "reserved" 3 "Invalid" ;
VAL_ 344 C_InhibitRMT 0 "Off" 1 "On" 2 "reserved" 3 "Invalid" ;
VAL_ 344 CF_SMKRKECmd 1 "Lock" 2 "Unlock" 3 "Trunk(or Tail Gate)" 4 "Panic" 5 "Panic stop" 6 "Two Step Unlock Warning" ;
VAL_ 87 NaviValidity 0 "Normal" 1 "Navi Error" 2 "No Navi" 3 "Invalid" ;
VAL_ 343 CF_Lkas_TsrSlifOpt 0 "None SLIF option (default)" 1 "System Disable by USM" 2 "System Enable by USM" 3 "Invalid" ;
VAL_ 343 CF_Lkas_TsrStatus 0 "TSR Information Valid(default)" 1 "TSR Information Invalid Failure" 2 "TSR Information Temporary Unavailable" 3 "Invalid" ;
VAL_ 343 CF_Lkas_TsrAddinfo_Disp 0 "None Display(Default)" 1 "No Passing Zone Display" 2 "Reserved" 3 "Invalid" ;
VAL_ 343 CF_Lkas_TsrSpeed_Display 0 "No recognition(default)" 253 "End of speed limit" 254 "Out of speed limit" 255 "Invalid" ;
VAL_ 75 AMP_EngOrderC2GainSet 0 "Min Value" 1 "Values" 2 "Values" 3 "Values" 4 "Values" 5 "Values" 6 "Values" 7 "Values" 8 "Values" 9 "Values" 10 "Values" 11 "Values" 12 "Values" 13 "Values" 14 "Values" 15 "Values" 16 "Values" 17 "Values" 18 "Values" 19 "Values" 20 "Values" 21 "Values" 22 "Values" 23 "Values" 24 "Max Value" 255 "Invalid" ;
VAL_ 75 AMP_EngOrderC4GainSet 0 "Min Value" 1 "Values" 2 "Values" 3 "Values" 4 "Values" 5 "Values" 6 "Values" 7 "Values" 8 "Values" 9 "Values" 10 "Values" 11 "Values" 12 "Values" 13 "Values" 14 "Values" 15 "Values" 16 "Values" 17 "Values" 18 "Values" 19 "Values" 20 "Values" 21 "Values" 22 "Values" 23 "Values" 24 "Max Value" 255 "Invalid" ;
VAL_ 75 AMP_EngOrderC6GainSet 0 "Min Value" 1 "Values" 2 "Values" 3 "Values" 4 "Values" 5 "Values" 6 "Values" 7 "Values" 8 "Values" 9 "Values" 10 "Values" 11 "Values" 12 "Values" 13 "Values" 14 "Values" 15 "Values" 16 "Values" 17 "Values" 18 "Values" 19 "Values" 20 "Values" 21 "Values" 22 "Values" 23 "Values" 24 "Max Value" 255 "Invalid" ;
VAL_ 75 AMP_APSBand0GainSet 0 "Min Value" 1 "Values" 2 "Values" 3 "Values" 4 "Values" 5 "Values" 6 "Values" 7 "Values" 8 "Values" 9 "Values" 10 "Values" 11 "Values" 12 "Values" 13 "Values" 14 "Values" 15 "Values" 16 "Values" 17 "Values" 18 "Values" 19 "Values" 20 "Values" 21 "Values" 22 "Values" 23 "Values" 24 "Max Value" 255 "Invalid" ;
VAL_ 75 AMP_APSBand1GainSet 0 "Min Value" 1 "Values" 2 "Values" 3 "Values" 4 "Values" 5 "Values" 6 "Values" 7 "Values" 8 "Values" 9 "Values" 10 "Values" 11 "Values" 12 "Values" 13 "Values" 14 "Values" 15 "Values" 16 "Values" 17 "Values" 18 "Values" 19 "Values" 20 "Values" 21 "Values" 22 "Values" 23 "Values" 24 "Max Value" 255 "Invalid" ;
VAL_ 75 AMP_APSBand2GainSet 0 "Min Value" 1 "Values" 2 "Values" 3 "Values" 4 "Values" 5 "Values" 6 "Values" 7 "Values" 8 "Values" 9 "Values" 10 "Values" 11 "Values" 12 "Values" 13 "Values" 14 "Values" 15 "Values" 16 "Values" 17 "Values" 18 "Values" 19 "Values" 20 "Values" 21 "Values" 22 "Values" 23 "Values" 24 "Max Value" 255 "Invalid" ;
VAL_ 75 AMP_APSBand3GainSet 0 "Min Value" 1 "Values" 2 "Values" 3 "Values" 4 "Values" 5 "Values" 6 "Values" 7 "Values" 8 "Values" 9 "Values" 10 "Values" 11 "Values" 12 "Values" 13 "Values" 14 "Values" 15 "Values" 16 "Values" 17 "Values" 18 "Values" 19 "Values" 20 "Values" 21 "Values" 22 "Values" 23 "Values" 24 "Max Value" 255 "Invalid" ;
VAL_ 75 AMP_APSBand4GainSet 0 "Min Value" 1 "Values" 2 "Values" 3 "Values" 4 "Values" 5 "Values" 6 "Values" 7 "Values" 8 "Values" 9 "Values" 10 "Values" 11 "Values" 12 "Values" 13 "Values" 14 "Values" 15 "Values" 16 "Values" 17 "Values" 18 "Values" 19 "Values" 20 "Values" 21 "Values" 22 "Values" 23 "Values" 24 "Max Value" 255 "Invalid" ;
VAL_ 74 AMP_PESSMode 0 "PESS OFF" 1 "PESS ON (Default)" 2 "PESS Check" 3 "Invalid" ;
VAL_ 74 AMP_PESSDesignSet 0 "Type 0 (Default)" 1 "Type 1" 2 "Type 2" 3 "Reserved" 4 "Reserved" 5 "Reserved" 6 "Reserved" 7 "Invalid" ;
VAL_ 74 AMP_PESSAPSSet 0 "Type 0" 1 "Type 1" 2 "Type 2 (Default)" 3 "Type 3" 4 "Type 4" 5 "Reserved" 6 "Reserved" 7 "Invalid" ;
VAL_ 74 AMP_PESSVolumeSet 0 "Min Value" 1 "Values" 2 "Values" 3 "Values" 4 "Values" 5 "Values" 6 "Values" 7 "Values" 8 "Values" 9 "Values" 10 "Values" 11 "Values" 12 "Values" 13 "Values" 14 "Values" 15 "Values" 16 "Values" 17 "Values" 18 "Values" 19 "Values" 20 "Values" 21 "Max Value" 255 "Invalid" ;
VAL_ 327 TMU_TbT_TurnIcon 255 "Invalid" ;
VAL_ 327 TMU_TbT_CountDownBar 0 "Count Down Bar Value" 1 "Count Down Bar Value" 2 "Count Down Bar Value" 3 "Count Down Bar Value" 4 "Count Down Bar Value" 5 "Count Down Bar Value" 6 "Count Down Bar Value" 7 "Count Down Bar Value" 8 "Count Down Bar Value" 9 "Count Down Bar Value" 10 "Count Down Bar Value" 11 "Count Down Bar Value" 12 "Count Down Bar Value" 13 "Count Down Bar Value" 14 "Count Down Bar Value" 15 "Invalid" ;
VAL_ 327 TMU_TbT_Distance_Unit 0 "mile" 1 "feet" 2 "kilometer" 3 "meter" ;
VAL_ 327 TMU_TbT_DestDistance_Unit 0 "mile" 1 "feet" 2 "kilometer" 3 "meter" ;
VAL_ 327 TMU_TbT_DistanceLo 0 "Distance Value 0~90" 1 "Distance Value 0~90" 2 "Distance Value 0~90" 3 "Distance Value 0~90" 4 "Distance Value 0~90" 5 "Distance Value 0~90" 6 "Distance Value 0~90" 7 "Distance Value 0~90" 8 "Distance Value 0~90" 9 "Distance Value 0~90" 15 "Invalid" ;
VAL_ 327 TMU_TbT_DistanceHi 4095 "Invalid" ;
VAL_ 327 TMU_TbT_DestDistanceLo 0 "Distance Value 0~90" 1 "Distance Value 0~90" 2 "Distance Value 0~90" 3 "Distance Value 0~90" 4 "Distance Value 0~90" 5 "Distance Value 0~90" 6 "Distance Value 0~90" 7 "Distance Value 0~90" 8 "Distance Value 0~90" 9 "Distance Value 0~90" 15 "Invalid" ;
VAL_ 327 TMU_TbT_DestDistanceHi 4095 "Invalid" ;
VAL_ 327 TMU_TbT_ExpectRemainHour 255 "Invalid" ;
VAL_ 327 TMU_TbT_ExpectRemainMin 0 "0~59 minute" 1 "0~59 minute" 2 "0~59 minute" 3 "0~59 minute" 4 "0~59 minute" 5 "0~59 minute" 6 "0~59 minute" 7 "0~59 minute" 8 "0~59 minute" 9 "0~59 minute" 10 "0~59 minute" 11 "0~59 minute" 12 "0~59 minute" 13 "0~59 minute" 14 "0~59 minute" 15 "0~59 minute" 16 "0~59 minute" 17 "0~59 minute" 18 "0~59 minute" 19 "0~59 minute" 20 "0~59 minute" 21 "0~59 minute" 22 "0~59 minute" 23 "0~59 minute" 24 "0~59 minute" 25 "0~59 minute" 26 "0~59 minute" 27 "0~59 minute" 28 "0~59 minute" 29 "0~59 minute" 30 "0~59 minute" 31 "0~59 minute" 32 "0~59 minute" 33 "0~59 minute" 34 "0~59 minute" 35 "0~59 minute" 36 "0~59 minute" 37 "0~59 minute" 38 "0~59 minute" 39 "0~59 minute" 40 "0~59 minute" 41 "0~59 minute" 42 "0~59 minute" 43 "0~59 minute" 44 "0~59 minute" 45 "0~59 minute" 46 "0~59 minute" 47 "0~59 minute" 48 "0~59 minute" 49 "0~59 minute" 50 "0~59 minute" 51 "0~59 minute" 52 "0~59 minute" 53 "0~59 minute" 54 "0~59 minute" 55 "0~59 minute" 56 "0~59 minute" 57 "0~59 minute" 58 "0~59 minute" 59 "0~59 minute" 63 "Invalid" ;
VAL_ 326 TMU_CallStatus 0 "Call is disconnected_Idle" 1 "Call is connecting" 2 "Call is connected" 3 "Call is dropped" 4 "Call is ringing _ Incoming Call" 5 "Call is released" 6 "No Service" 7 "Busy" 8 "Call is time ou" ;
VAL_ 326 TMU_CallType 0 "No Type" 1 "ACN Call" 2 "SOS Call" 3 "IVR Call" 4 "Reserved" 5 "Reserved" 6 "Reserved" 7 "Invalid" ;
VAL_ 326 TMU_CDMA_Streng 0 "No Service" 1 "Strength Value" 2 "Strength Value" 3 "Strength Value" 4 "Strength Value" 5 "Strength Value" 6 "Strength Value" 7 "Strength Value" 8 "Reserved" 9 "Reserved" 10 "Reserved" 11 "Reserved" 12 "Reserved" 13 "Reserved" 14 "Reserved" 15 "Invalid" ;
VAL_ 326 TMU_PacketStatus 0 "No packet" 1 "Using Packet" 2 "Busy Network" 3 "Invalid" ;
VAL_ 326 TMU_TalkTimeHour 0 "0~23 hour" 1 "0~23 hour" 2 "0~23 hour" 3 "0~23 hour" 4 "0~23 hour" 5 "0~23 hour" 6 "0~23 hour" 7 "0~23 hour" 8 "0~23 hour" 9 "0~23 hour" 10 "0~23 hour" 11 "0~23 hour" 12 "0~23 hour" 13 "0~23 hour" 14 "0~23 hour" 15 "0~23 hour" 16 "0~23 hour" 17 "0~23 hour" 18 "0~23 hour" 19 "0~23 hour" 20 "0~23 hour" 21 "0~23 hour" 22 "0~23 hour" 23 "0~23 hour" 31 "Invalid" ;
VAL_ 326 TMU_TalkTimeMinute 0 "0~59 minute" 1 "0~59 minute" 2 "0~59 minute" 3 "0~59 minute" 4 "0~59 minute" 5 "0~59 minute" 6 "0~59 minute" 7 "0~59 minute" 8 "0~59 minute" 9 "0~59 minute" 10 "0~59 minute" 11 "0~59 minute" 12 "0~59 minute" 13 "0~59 minute" 14 "0~59 minute" 15 "0~59 minute" 16 "0~59 minute" 17 "0~59 minute" 18 "0~59 minute" 19 "0~59 minute" 20 "0~59 minute" 21 "0~59 minute" 22 "0~59 minute" 23 "0~59 minute" 24 "0~59 minute" 25 "0~59 minute" 26 "0~59 minute" 27 "0~59 minute" 28 "0~59 minute" 29 "0~59 minute" 30 "0~59 minute" 31 "0~59 minute" 32 "0~59 minute" 33 "0~59 minute" 34 "0~59 minute" 35 "0~59 minute" 36 "0~59 minute" 37 "0~59 minute" 38 "0~59 minute" 39 "0~59 minute" 40 "0~59 minute" 41 "0~59 minute" 42 "0~59 minute" 43 "0~59 minute" 44 "0~59 minute" 45 "0~59 minute" 46 "0~59 minute" 47 "0~59 minute" 48 "0~59 minute" 49 "0~59 minute" 50 "0~59 minute" 51 "0~59 minute" 52 "0~59 minute" 53 "0~59 minute" 54 "0~59 minute" 55 "0~59 minute" 56 "0~59 minute" 57 "0~59 minute" 58 "0~59 minute" 59 "0~59 minute" 63 "Invalid" ;
VAL_ 326 TMU_TalkTimeSecond 0 "0~59 second" 1 "0~59 second" 2 "0~59 second" 3 "0~59 second" 4 "0~59 second" 5 "0~59 second" 6 "0~59 second" 7 "0~59 second" 8 "0~59 second" 9 "0~59 second" 10 "0~59 second" 11 "0~59 second" 12 "0~59 second" 13 "0~59 second" 14 "0~59 second" 15 "0~59 second" 16 "0~59 second" 17 "0~59 second" 18 "0~59 second" 19 "0~59 second" 20 "0~59 second" 21 "0~59 second" 22 "0~59 second" 23 "0~59 second" 24 "0~59 second" 25 "0~59 second" 26 "0~59 second" 27 "0~59 second" 28 "0~59 second" 29 "0~59 second" 30 "0~59 second" 31 "0~59 second" 32 "0~59 second" 33 "0~59 second" 34 "0~59 second" 35 "0~59 second" 36 "0~59 second" 37 "0~59 second" 38 "0~59 second" 39 "0~59 second" 40 "0~59 second" 41 "0~59 second" 42 "0~59 second" 43 "0~59 second" 44 "0~59 second" 45 "0~59 second" 46 "0~59 second" 47 "0~59 second" 48 "0~59 second" 49 "0~59 second" 50 "0~59 second" 51 "0~59 second" 52 "0~59 second" 53 "0~59 second" 54 "0~59 second" 55 "0~59 second" 56 "0~59 second" 57 "0~59 second" 58 "0~59 second" 59 "0~59 second" 63 "Invalid" ;
VAL_ 325 TMU_AliveStatus 0 "Not Ready" 1 "On Mode(Operation Mode)" 2 "Engineering Mode" 3 "Update Mode" 4 "Reserved" 5 "Reserved" 6 "Reserved" 7 "Invalid" ;
VAL_ 325 TMU_AudioStatus 0 "No Audio" 1 "Playing Audio" 2 "Reserved" 3 "Invalid" ;
VAL_ 325 TMU_UpdateStatus 0 "No Action" 1 "Updating TMU" 2 "Updating MICOM" 3 "Update Network Acess Device" 4 "Update Done" 5 "Update Fail" 6 "Reserved" 7 "Invalid" ;
VAL_ 325 TMU_LangStatus 0 "No Action" 1 "English" 2 "French" 3 "Spanish" 4 "Chinese" 5 "Korean" 6 "Reserved" 7 "Invalid" ;
VAL_ 325 TMU_VoiceRecStatus 0 "No VR status" 1 "VR is listening" 2 "VR is speaking" 3 "Invalid" ;
VAL_ 325 TMU_MicStatus 0 "Mic Not Use" 1 "Mic Using" 2 "Mic Switching" 3 "Invalid" ;
VAL_ 325 TMU_ServCommuStatus 0 "No Dowloading" 1 "XM Traffic Downloading" 2 "POI Downloading" 3 "Song Tag Uploading" 4 "DTC Uploading_Downloading" 5 "Contents Updating" 6 "Reserved" 7 "Reserved" 8 "Reserved" 9 "Reserved" 10 "Reserved" 11 "Reserved" 12 "Reserved" 13 "Reserved" 14 "Reserved" 15 "Invalid" ;
VAL_ 325 TMU_PowerStatus 0 "IGN OFF" 1 "IGN ON" 2 "Reserved" 3 "Invalid" ;
VAL_ 325 TMU_EngineStatus 0 "Engine Off" 1 "Engine Running" 2 "Reserved" 3 "Invalid" ;
VAL_ 325 TMU_DownProgress 0 "No Download Progress" 255 "Invalid" ;
VAL_ 69 TMU_eCall 0 "No Action" 1 "" 2 "" 3 "Invalid" ;
VAL_ 67 C_ReqDrLock 0 "Off" 1 "On" 2 "Not used" 3 "Invalid" ;
VAL_ 67 C_ReqDrUnlock 0 "Off" 1 "On" 2 "Not used" 3 "Invalid" ;
VAL_ 67 C_ReqHazard 0 "Off" 1 "On" 2 "Not used" 3 "Invalid" ;
VAL_ 67 C_ReqHorn 0 "Off" 1 "On" 2 "Not used" 3 "Invalid" ;
VAL_ 67 C_ReqEngineOperate 0 "Default" 1 "Cranking" 2 "stop" 3 "Invalid" ;
VAL_ 66 CDMA_SelfDiag 0 "Not Used" 1 "Working" 2 "Not Working" 3 "Invalid" ;
VAL_ 66 CDMA_Antena_SelfDiag 0 "Not Used" 1 "Working" 2 "Not Working" 3 "Invalid" ;
VAL_ 1345 TMU_SupVoiceTextService 0 "Not Used" 1 "TRUE" 2 "FALSE" 3 "Invalid" ;
VAL_ 1345 TMU_SupEcoCoachService 0 "Not Used" 1 "TRUE" 2 "FALSE" 3 "Invalid" ;
VAL_ 1345 TMU_SupSongTagService 0 "Not Used" 1 "TRUE" 2 "FALSE" 3 "Invalid" ;
VAL_ 1345 TMU_SupContentService 0 "Not Used" 1 "TRUE" 2 "FALSE" 3 "Invalid" ;
VAL_ 1345 TMU_MajorVersion 255 "Invalid" ;
VAL_ 1345 TMU_MinorVersion 255 "Invalid" ;
VAL_ 1345 TMU_DistributeInfo 0 "Not Used" 1 "HMA TMU (America)" 2 "CHA TMU (China)" 3 "EUR TMU (Europe)" 4 "BRZ TMU (Brazil)" 5 "KMA TMU (America)" 6 "AME TMU (Asia&amp;MiddleEast)" 7 "CUbiS-T(H)" 8 "CUbiS-W(K)" 9 "CUbiS-W(H)" 10 "CUbiS-W(K)" 11 "CUbiS" 12 "Reserved" 13 "Reserved" 14 "Reserved" 15 "Invalid" ;
VAL_ 65 TMU_BarLevel1 0 "0 ~ 63 level" 1 "0 ~ 63 level" 2 "0 ~ 63 level" 3 "0 ~ 63 level" 4 "0 ~ 63 level" 5 "0 ~ 63 level" 6 "0 ~ 63 level" 7 "0 ~ 63 level" 8 "0 ~ 63 level" 9 "0 ~ 63 level" 10 "0 ~ 63 level" 11 "0 ~ 63 level" 12 "0 ~ 63 level" 13 "0 ~ 63 level" 14 "0 ~ 63 level" 15 "0 ~ 63 level" 16 "0 ~ 63 level" 17 "0 ~ 63 level" 18 "0 ~ 63 level" 19 "0 ~ 63 level" 20 "0 ~ 63 level" 21 "0 ~ 63 level" 22 "0 ~ 63 level" 23 "0 ~ 63 level" 24 "0 ~ 63 level" 25 "0 ~ 63 level" 26 "0 ~ 63 level" 27 "0 ~ 63 level" 28 "0 ~ 63 level" 29 "0 ~ 63 level" 30 "0 ~ 63 level" 31 "0 ~ 63 level" 32 "0 ~ 63 level" 33 "0 ~ 63 level" 34 "0 ~ 63 level" 35 "0 ~ 63 level" 36 "0 ~ 63 level" 37 "0 ~ 63 level" 38 "0 ~ 63 level" 39 "0 ~ 63 level" 40 "0 ~ 63 level" 41 "0 ~ 63 level" 42 "0 ~ 63 level" 43 "0 ~ 63 level" 44 "0 ~ 63 level" 45 "0 ~ 63 level" 46 "0 ~ 63 level" 47 "0 ~ 63 level" 48 "0 ~ 63 level" 49 "0 ~ 63 level" 50 "0 ~ 63 level" 51 "0 ~ 63 level" 52 "0 ~ 63 level" 53 "0 ~ 63 level" 54 "0 ~ 63 level" 55 "0 ~ 63 level" 56 "0 ~ 63 level" 57 "0 ~ 63 level" 58 "0 ~ 63 level" 59 "0 ~ 63 level" 60 "0 ~ 63 level" 61 "0 ~ 63 level" 62 "0 ~ 63 level" 63 "0 ~ 63 level" ;
VAL_ 65 TMU_BarLevel2 0 "0 ~ 63 level" 1 "0 ~ 63 level" 2 "0 ~ 63 level" 3 "0 ~ 63 level" 4 "0 ~ 63 level" 5 "0 ~ 63 level" 6 "0 ~ 63 level" 7 "0 ~ 63 level" 8 "0 ~ 63 level" 9 "0 ~ 63 level" 10 "0 ~ 63 level" 11 "0 ~ 63 level" 12 "0 ~ 63 level" 13 "0 ~ 63 level" 14 "0 ~ 63 level" 15 "0 ~ 63 level" 16 "0 ~ 63 level" 17 "0 ~ 63 level" 18 "0 ~ 63 level" 19 "0 ~ 63 level" 20 "0 ~ 63 level" 21 "0 ~ 63 level" 22 "0 ~ 63 level" 23 "0 ~ 63 level" 24 "0 ~ 63 level" 25 "0 ~ 63 level" 26 "0 ~ 63 level" 27 "0 ~ 63 level" 28 "0 ~ 63 level" 29 "0 ~ 63 level" 30 "0 ~ 63 level" 31 "0 ~ 63 level" 32 "0 ~ 63 level" 33 "0 ~ 63 level" 34 "0 ~ 63 level" 35 "0 ~ 63 level" 36 "0 ~ 63 level" 37 "0 ~ 63 level" 38 "0 ~ 63 level" 39 "0 ~ 63 level" 40 "0 ~ 63 level" 41 "0 ~ 63 level" 42 "0 ~ 63 level" 43 "0 ~ 63 level" 44 "0 ~ 63 level" 45 "0 ~ 63 level" 46 "0 ~ 63 level" 47 "0 ~ 63 level" 48 "0 ~ 63 level" 49 "0 ~ 63 level" 50 "0 ~ 63 level" 51 "0 ~ 63 level" 52 "0 ~ 63 level" 53 "0 ~ 63 level" 54 "0 ~ 63 level" 55 "0 ~ 63 level" 56 "0 ~ 63 level" 57 "0 ~ 63 level" 58 "0 ~ 63 level" 59 "0 ~ 63 level" 60 "0 ~ 63 level" 61 "0 ~ 63 level" 62 "0 ~ 63 level" 63 "0 ~ 63 level" ;
VAL_ 65 TMU_BarLevel4 0 "0 ~ 63 level" 1 "0 ~ 63 level" 2 "0 ~ 63 level" 3 "0 ~ 63 level" 4 "0 ~ 63 level" 5 "0 ~ 63 level" 6 "0 ~ 63 level" 7 "0 ~ 63 level" 8 "0 ~ 63 level" 9 "0 ~ 63 level" 10 "0 ~ 63 level" 11 "0 ~ 63 level" 12 "0 ~ 63 level" 13 "0 ~ 63 level" 14 "0 ~ 63 level" 15 "0 ~ 63 level" 16 "0 ~ 63 level" 17 "0 ~ 63 level" 18 "0 ~ 63 level" 19 "0 ~ 63 level" 20 "0 ~ 63 level" 21 "0 ~ 63 level" 22 "0 ~ 63 level" 23 "0 ~ 63 level" 24 "0 ~ 63 level" 25 "0 ~ 63 level" 26 "0 ~ 63 level" 27 "0 ~ 63 level" 28 "0 ~ 63 level" 29 "0 ~ 63 level" 30 "0 ~ 63 level" 31 "0 ~ 63 level" 32 "0 ~ 63 level" 33 "0 ~ 63 level" 34 "0 ~ 63 level" 35 "0 ~ 63 level" 36 "0 ~ 63 level" 37 "0 ~ 63 level" 38 "0 ~ 63 level" 39 "0 ~ 63 level" 40 "0 ~ 63 level" 41 "0 ~ 63 level" 42 "0 ~ 63 level" 43 "0 ~ 63 level" 44 "0 ~ 63 level" 45 "0 ~ 63 level" 46 "0 ~ 63 level" 47 "0 ~ 63 level" 48 "0 ~ 63 level" 49 "0 ~ 63 level" 50 "0 ~ 63 level" 51 "0 ~ 63 level" 52 "0 ~ 63 level" 53 "0 ~ 63 level" 54 "0 ~ 63 level" 55 "0 ~ 63 level" 56 "0 ~ 63 level" 57 "0 ~ 63 level" 58 "0 ~ 63 level" 59 "0 ~ 63 level" 60 "0 ~ 63 level" 61 "0 ~ 63 level" 62 "0 ~ 63 level" 63 "0 ~ 63 level" ;
VAL_ 65 TMU_BarLevel3 0 "0 ~ 63 level" 1 "0 ~ 63 level" 2 "0 ~ 63 level" 3 "0 ~ 63 level" 4 "0 ~ 63 level" 5 "0 ~ 63 level" 6 "0 ~ 63 level" 7 "0 ~ 63 level" 8 "0 ~ 63 level" 9 "0 ~ 63 level" 10 "0 ~ 63 level" 11 "0 ~ 63 level" 12 "0 ~ 63 level" 13 "0 ~ 63 level" 14 "0 ~ 63 level" 15 "0 ~ 63 level" 16 "0 ~ 63 level" 17 "0 ~ 63 level" 18 "0 ~ 63 level" 19 "0 ~ 63 level" 20 "0 ~ 63 level" 21 "0 ~ 63 level" 22 "0 ~ 63 level" 23 "0 ~ 63 level" 24 "0 ~ 63 level" 25 "0 ~ 63 level" 26 "0 ~ 63 level" 27 "0 ~ 63 level" 28 "0 ~ 63 level" 29 "0 ~ 63 level" 30 "0 ~ 63 level" 31 "0 ~ 63 level" 32 "0 ~ 63 level" 33 "0 ~ 63 level" 34 "0 ~ 63 level" 35 "0 ~ 63 level" 36 "0 ~ 63 level" 37 "0 ~ 63 level" 38 "0 ~ 63 level" 39 "0 ~ 63 level" 40 "0 ~ 63 level" 41 "0 ~ 63 level" 42 "0 ~ 63 level" 43 "0 ~ 63 level" 44 "0 ~ 63 level" 45 "0 ~ 63 level" 46 "0 ~ 63 level" 47 "0 ~ 63 level" 48 "0 ~ 63 level" 49 "0 ~ 63 level" 50 "0 ~ 63 level" 51 "0 ~ 63 level" 52 "0 ~ 63 level" 53 "0 ~ 63 level" 54 "0 ~ 63 level" 55 "0 ~ 63 level" 56 "0 ~ 63 level" 57 "0 ~ 63 level" 58 "0 ~ 63 level" 59 "0 ~ 63 level" 60 "0 ~ 63 level" 61 "0 ~ 63 level" 62 "0 ~ 63 level" 63 "0 ~ 63 level" ;
VAL_ 65 TMU_BarLevel5 0 "0 ~ 63 level" 1 "0 ~ 63 level" 2 "0 ~ 63 level" 3 "0 ~ 63 level" 4 "0 ~ 63 level" 5 "0 ~ 63 level" 6 "0 ~ 63 level" 7 "0 ~ 63 level" 8 "0 ~ 63 level" 9 "0 ~ 63 level" 10 "0 ~ 63 level" 11 "0 ~ 63 level" 12 "0 ~ 63 level" 13 "0 ~ 63 level" 14 "0 ~ 63 level" 15 "0 ~ 63 level" 16 "0 ~ 63 level" 17 "0 ~ 63 level" 18 "0 ~ 63 level" 19 "0 ~ 63 level" 20 "0 ~ 63 level" 21 "0 ~ 63 level" 22 "0 ~ 63 level" 23 "0 ~ 63 level" 24 "0 ~ 63 level" 25 "0 ~ 63 level" 26 "0 ~ 63 level" 27 "0 ~ 63 level" 28 "0 ~ 63 level" 29 "0 ~ 63 level" 30 "0 ~ 63 level" 31 "0 ~ 63 level" 32 "0 ~ 63 level" 33 "0 ~ 63 level" 34 "0 ~ 63 level" 35 "0 ~ 63 level" 36 "0 ~ 63 level" 37 "0 ~ 63 level" 38 "0 ~ 63 level" 39 "0 ~ 63 level" 40 "0 ~ 63 level" 41 "0 ~ 63 level" 42 "0 ~ 63 level" 43 "0 ~ 63 level" 44 "0 ~ 63 level" 45 "0 ~ 63 level" 46 "0 ~ 63 level" 47 "0 ~ 63 level" 48 "0 ~ 63 level" 49 "0 ~ 63 level" 50 "0 ~ 63 level" 51 "0 ~ 63 level" 52 "0 ~ 63 level" 53 "0 ~ 63 level" 54 "0 ~ 63 level" 55 "0 ~ 63 level" 56 "0 ~ 63 level" 57 "0 ~ 63 level" 58 "0 ~ 63 level" 59 "0 ~ 63 level" 60 "0 ~ 63 level" 61 "0 ~ 63 level" 62 "0 ~ 63 level" 63 "0 ~ 63 level" ;
VAL_ 65 TMU_BarLevel6 0 "0 ~ 63 level" 1 "0 ~ 63 level" 2 "0 ~ 63 level" 3 "0 ~ 63 level" 4 "0 ~ 63 level" 5 "0 ~ 63 level" 6 "0 ~ 63 level" 7 "0 ~ 63 level" 8 "0 ~ 63 level" 9 "0 ~ 63 level" 10 "0 ~ 63 level" 11 "0 ~ 63 level" 12 "0 ~ 63 level" 13 "0 ~ 63 level" 14 "0 ~ 63 level" 15 "0 ~ 63 level" 16 "0 ~ 63 level" 17 "0 ~ 63 level" 18 "0 ~ 63 level" 19 "0 ~ 63 level" 20 "0 ~ 63 level" 21 "0 ~ 63 level" 22 "0 ~ 63 level" 23 "0 ~ 63 level" 24 "0 ~ 63 level" 25 "0 ~ 63 level" 26 "0 ~ 63 level" 27 "0 ~ 63 level" 28 "0 ~ 63 level" 29 "0 ~ 63 level" 30 "0 ~ 63 level" 31 "0 ~ 63 level" 32 "0 ~ 63 level" 33 "0 ~ 63 level" 34 "0 ~ 63 level" 35 "0 ~ 63 level" 36 "0 ~ 63 level" 37 "0 ~ 63 level" 38 "0 ~ 63 level" 39 "0 ~ 63 level" 40 "0 ~ 63 level" 41 "0 ~ 63 level" 42 "0 ~ 63 level" 43 "0 ~ 63 level" 44 "0 ~ 63 level" 45 "0 ~ 63 level" 46 "0 ~ 63 level" 47 "0 ~ 63 level" 48 "0 ~ 63 level" 49 "0 ~ 63 level" 50 "0 ~ 63 level" 51 "0 ~ 63 level" 52 "0 ~ 63 level" 53 "0 ~ 63 level" 54 "0 ~ 63 level" 55 "0 ~ 63 level" 56 "0 ~ 63 level" 57 "0 ~ 63 level" 58 "0 ~ 63 level" 59 "0 ~ 63 level" 60 "0 ~ 63 level" 61 "0 ~ 63 level" 62 "0 ~ 63 level" 63 "0 ~ 63 level" ;
VAL_ 65 TMU_BarLevel8 0 "0 ~ 63 level" 1 "0 ~ 63 level" 2 "0 ~ 63 level" 3 "0 ~ 63 level" 4 "0 ~ 63 level" 5 "0 ~ 63 level" 6 "0 ~ 63 level" 7 "0 ~ 63 level" 8 "0 ~ 63 level" 9 "0 ~ 63 level" 10 "0 ~ 63 level" 11 "0 ~ 63 level" 12 "0 ~ 63 level" 13 "0 ~ 63 level" 14 "0 ~ 63 level" 15 "0 ~ 63 level" 16 "0 ~ 63 level" 17 "0 ~ 63 level" 18 "0 ~ 63 level" 19 "0 ~ 63 level" 20 "0 ~ 63 level" 21 "0 ~ 63 level" 22 "0 ~ 63 level" 23 "0 ~ 63 level" 24 "0 ~ 63 level" 25 "0 ~ 63 level" 26 "0 ~ 63 level" 27 "0 ~ 63 level" 28 "0 ~ 63 level" 29 "0 ~ 63 level" 30 "0 ~ 63 level" 31 "0 ~ 63 level" 32 "0 ~ 63 level" 33 "0 ~ 63 level" 34 "0 ~ 63 level" 35 "0 ~ 63 level" 36 "0 ~ 63 level" 37 "0 ~ 63 level" 38 "0 ~ 63 level" 39 "0 ~ 63 level" 40 "0 ~ 63 level" 41 "0 ~ 63 level" 42 "0 ~ 63 level" 43 "0 ~ 63 level" 44 "0 ~ 63 level" 45 "0 ~ 63 level" 46 "0 ~ 63 level" 47 "0 ~ 63 level" 48 "0 ~ 63 level" 49 "0 ~ 63 level" 50 "0 ~ 63 level" 51 "0 ~ 63 level" 52 "0 ~ 63 level" 53 "0 ~ 63 level" 54 "0 ~ 63 level" 55 "0 ~ 63 level" 56 "0 ~ 63 level" 57 "0 ~ 63 level" 58 "0 ~ 63 level" 59 "0 ~ 63 level" 60 "0 ~ 63 level" 61 "0 ~ 63 level" 62 "0 ~ 63 level" 63 "0 ~ 63 level" ;
VAL_ 65 TMU_BarLevel7 0 "0 ~ 63 level" 1 "0 ~ 63 level" 2 "0 ~ 63 level" 3 "0 ~ 63 level" 4 "0 ~ 63 level" 5 "0 ~ 63 level" 6 "0 ~ 63 level" 7 "0 ~ 63 level" 8 "0 ~ 63 level" 9 "0 ~ 63 level" 10 "0 ~ 63 level" 11 "0 ~ 63 level" 12 "0 ~ 63 level" 13 "0 ~ 63 level" 14 "0 ~ 63 level" 15 "0 ~ 63 level" 16 "0 ~ 63 level" 17 "0 ~ 63 level" 18 "0 ~ 63 level" 19 "0 ~ 63 level" 20 "0 ~ 63 level" 21 "0 ~ 63 level" 22 "0 ~ 63 level" 23 "0 ~ 63 level" 24 "0 ~ 63 level" 25 "0 ~ 63 level" 26 "0 ~ 63 level" 27 "0 ~ 63 level" 28 "0 ~ 63 level" 29 "0 ~ 63 level" 30 "0 ~ 63 level" 31 "0 ~ 63 level" 32 "0 ~ 63 level" 33 "0 ~ 63 level" 34 "0 ~ 63 level" 35 "0 ~ 63 level" 36 "0 ~ 63 level" 37 "0 ~ 63 level" 38 "0 ~ 63 level" 39 "0 ~ 63 level" 40 "0 ~ 63 level" 41 "0 ~ 63 level" 42 "0 ~ 63 level" 43 "0 ~ 63 level" 44 "0 ~ 63 level" 45 "0 ~ 63 level" 46 "0 ~ 63 level" 47 "0 ~ 63 level" 48 "0 ~ 63 level" 49 "0 ~ 63 level" 50 "0 ~ 63 level" 51 "0 ~ 63 level" 52 "0 ~ 63 level" 53 "0 ~ 63 level" 54 "0 ~ 63 level" 55 "0 ~ 63 level" 56 "0 ~ 63 level" 57 "0 ~ 63 level" 58 "0 ~ 63 level" 59 "0 ~ 63 level" 60 "0 ~ 63 level" 61 "0 ~ 63 level" 62 "0 ~ 63 level" 63 "0 ~ 63 level" ;
VAL_ 65 TMU_BarLevel9 0 "0 ~ 63 level" 1 "0 ~ 63 level" 2 "0 ~ 63 level" 3 "0 ~ 63 level" 4 "0 ~ 63 level" 5 "0 ~ 63 level" 6 "0 ~ 63 level" 7 "0 ~ 63 level" 8 "0 ~ 63 level" 9 "0 ~ 63 level" 10 "0 ~ 63 level" 11 "0 ~ 63 level" 12 "0 ~ 63 level" 13 "0 ~ 63 level" 14 "0 ~ 63 level" 15 "0 ~ 63 level" 16 "0 ~ 63 level" 17 "0 ~ 63 level" 18 "0 ~ 63 level" 19 "0 ~ 63 level" 20 "0 ~ 63 level" 21 "0 ~ 63 level" 22 "0 ~ 63 level" 23 "0 ~ 63 level" 24 "0 ~ 63 level" 25 "0 ~ 63 level" 26 "0 ~ 63 level" 27 "0 ~ 63 level" 28 "0 ~ 63 level" 29 "0 ~ 63 level" 30 "0 ~ 63 level" 31 "0 ~ 63 level" 32 "0 ~ 63 level" 33 "0 ~ 63 level" 34 "0 ~ 63 level" 35 "0 ~ 63 level" 36 "0 ~ 63 level" 37 "0 ~ 63 level" 38 "0 ~ 63 level" 39 "0 ~ 63 level" 40 "0 ~ 63 level" 41 "0 ~ 63 level" 42 "0 ~ 63 level" 43 "0 ~ 63 level" 44 "0 ~ 63 level" 45 "0 ~ 63 level" 46 "0 ~ 63 level" 47 "0 ~ 63 level" 48 "0 ~ 63 level" 49 "0 ~ 63 level" 50 "0 ~ 63 level" 51 "0 ~ 63 level" 52 "0 ~ 63 level" 53 "0 ~ 63 level" 54 "0 ~ 63 level" 55 "0 ~ 63 level" 56 "0 ~ 63 level" 57 "0 ~ 63 level" 58 "0 ~ 63 level" 59 "0 ~ 63 level" 60 "0 ~ 63 level" 61 "0 ~ 63 level" 62 "0 ~ 63 level" 63 "0 ~ 63 level" ;
VAL_ 65 TMU_BarLevel10 0 "0 ~ 63 level" 1 "0 ~ 63 level" 2 "0 ~ 63 level" 3 "0 ~ 63 level" 4 "0 ~ 63 level" 5 "0 ~ 63 level" 6 "0 ~ 63 level" 7 "0 ~ 63 level" 8 "0 ~ 63 level" 9 "0 ~ 63 level" 10 "0 ~ 63 level" 11 "0 ~ 63 level" 12 "0 ~ 63 level" 13 "0 ~ 63 level" 14 "0 ~ 63 level" 15 "0 ~ 63 level" 16 "0 ~ 63 level" 17 "0 ~ 63 level" 18 "0 ~ 63 level" 19 "0 ~ 63 level" 20 "0 ~ 63 level" 21 "0 ~ 63 level" 22 "0 ~ 63 level" 23 "0 ~ 63 level" 24 "0 ~ 63 level" 25 "0 ~ 63 level" 26 "0 ~ 63 level" 27 "0 ~ 63 level" 28 "0 ~ 63 level" 29 "0 ~ 63 level" 30 "0 ~ 63 level" 31 "0 ~ 63 level" 32 "0 ~ 63 level" 33 "0 ~ 63 level" 34 "0 ~ 63 level" 35 "0 ~ 63 level" 36 "0 ~ 63 level" 37 "0 ~ 63 level" 38 "0 ~ 63 level" 39 "0 ~ 63 level" 40 "0 ~ 63 level" 41 "0 ~ 63 level" 42 "0 ~ 63 level" 43 "0 ~ 63 level" 44 "0 ~ 63 level" 45 "0 ~ 63 level" 46 "0 ~ 63 level" 47 "0 ~ 63 level" 48 "0 ~ 63 level" 49 "0 ~ 63 level" 50 "0 ~ 63 level" 51 "0 ~ 63 level" 52 "0 ~ 63 level" 53 "0 ~ 63 level" 54 "0 ~ 63 level" 55 "0 ~ 63 level" 56 "0 ~ 63 level" 57 "0 ~ 63 level" 58 "0 ~ 63 level" 59 "0 ~ 63 level" 60 "0 ~ 63 level" 61 "0 ~ 63 level" 62 "0 ~ 63 level" 63 "0 ~ 63 level" ;
VAL_ 1344 TMU_Arrow 0 "Low" 1 "High" 2 "Equal" 3 "Invalid" ;
VAL_ 1344 TMU_ReFill_Info 0 "No Action" 1 "Clear Request" 2 "Reserved" 3 "Invalid" ;
VAL_ 1344 TMU_AverageMPG 1023 "Invalid" ;
VAL_ 1344 TMU_TotalMPG 1023 "Invalid" ;
VAL_ 1344 TMU_RewardStar 0 "0 Value" 1 "1 Value" 9999 "9999 Value" 16383 "Invalid" ;
VAL_ 64 TMU_DisMode 0 "No Action" 1 "ACN" 2 "SOS" 3 "IVR" 4 "TbT (Audio Only)" 5 "Eco-Coach" 6 "VR Command" 7 "Normal Text" 8 "POI" 9 "Clear Display" 10 "TMU Update" 11 "Eco-coach OFF" 12 "TbT OFF" 13 "Reserved" 14 "Reserved" 15 "Invalid" ;
VAL_ 64 TMU_AudSrcType 0 "No Source Type" 1 "VR Prompt" 2 "TbT Prompt" 3 "ACN Call" 4 "SOS Call" 5 "IVR Call" 6 "Reserved" 7 "Reserved" 8 "Reserved" 9 "Reserved" 10 "Reserved" 11 "Reserved" 12 "Reserved" 13 "Reserved" 14 "Reserved" 15 "Invalid" ;
VAL_ 64 TMU_AudReqCmd 0 "No Action" 1 "Audio Allocation" 2 "Audio Deallocation" 3 "Invalid" ;
VAL_ 64 TMU_LangCmd 0 "No Action" 1 "English" 2 "French" 3 "Spanish" 4 "Chinese" 5 "Korean" 7 "Invalid" ;
VAL_ 64 TMU_ServReq 0 "No Action" 1 "Song Tag (Audio Only)" 2 "Power On by Stolen Vehicle" 3 "Head Unit GPS Time" 4 "Display On Request" 5 "Reserved" 6 "Reserved" 7 "Invalid" ;
VAL_ 64 TMU_ErrorEvent 9 "" 10 "" 11 "" 12 "" 13 "" 14 "" 15 "" 0 "No Error" 1 "VR Command Error" 2 "Traffic Command Error" 3 "Eco-Coach Error" 4 "POI Download Error" 5 "Song Tag Service Error" 6 "Provisioning Error" 7 "Voice Text Error" 8 "Center Con. not Available Err" ;
VAL_ 64 TMU_BeepCmd 0 "No Beep" 1 "Beep On" 2 "Reserved" 3 "Invalid" ;
VAL_ 64 TMU_eCall 0 "No Action" 1 "eCall Mode" 2 "eCall Termination" 3 "Test Mode" 4 "reserved" 5 "reserved" 6 "reserved" 7 "invalid" ;
